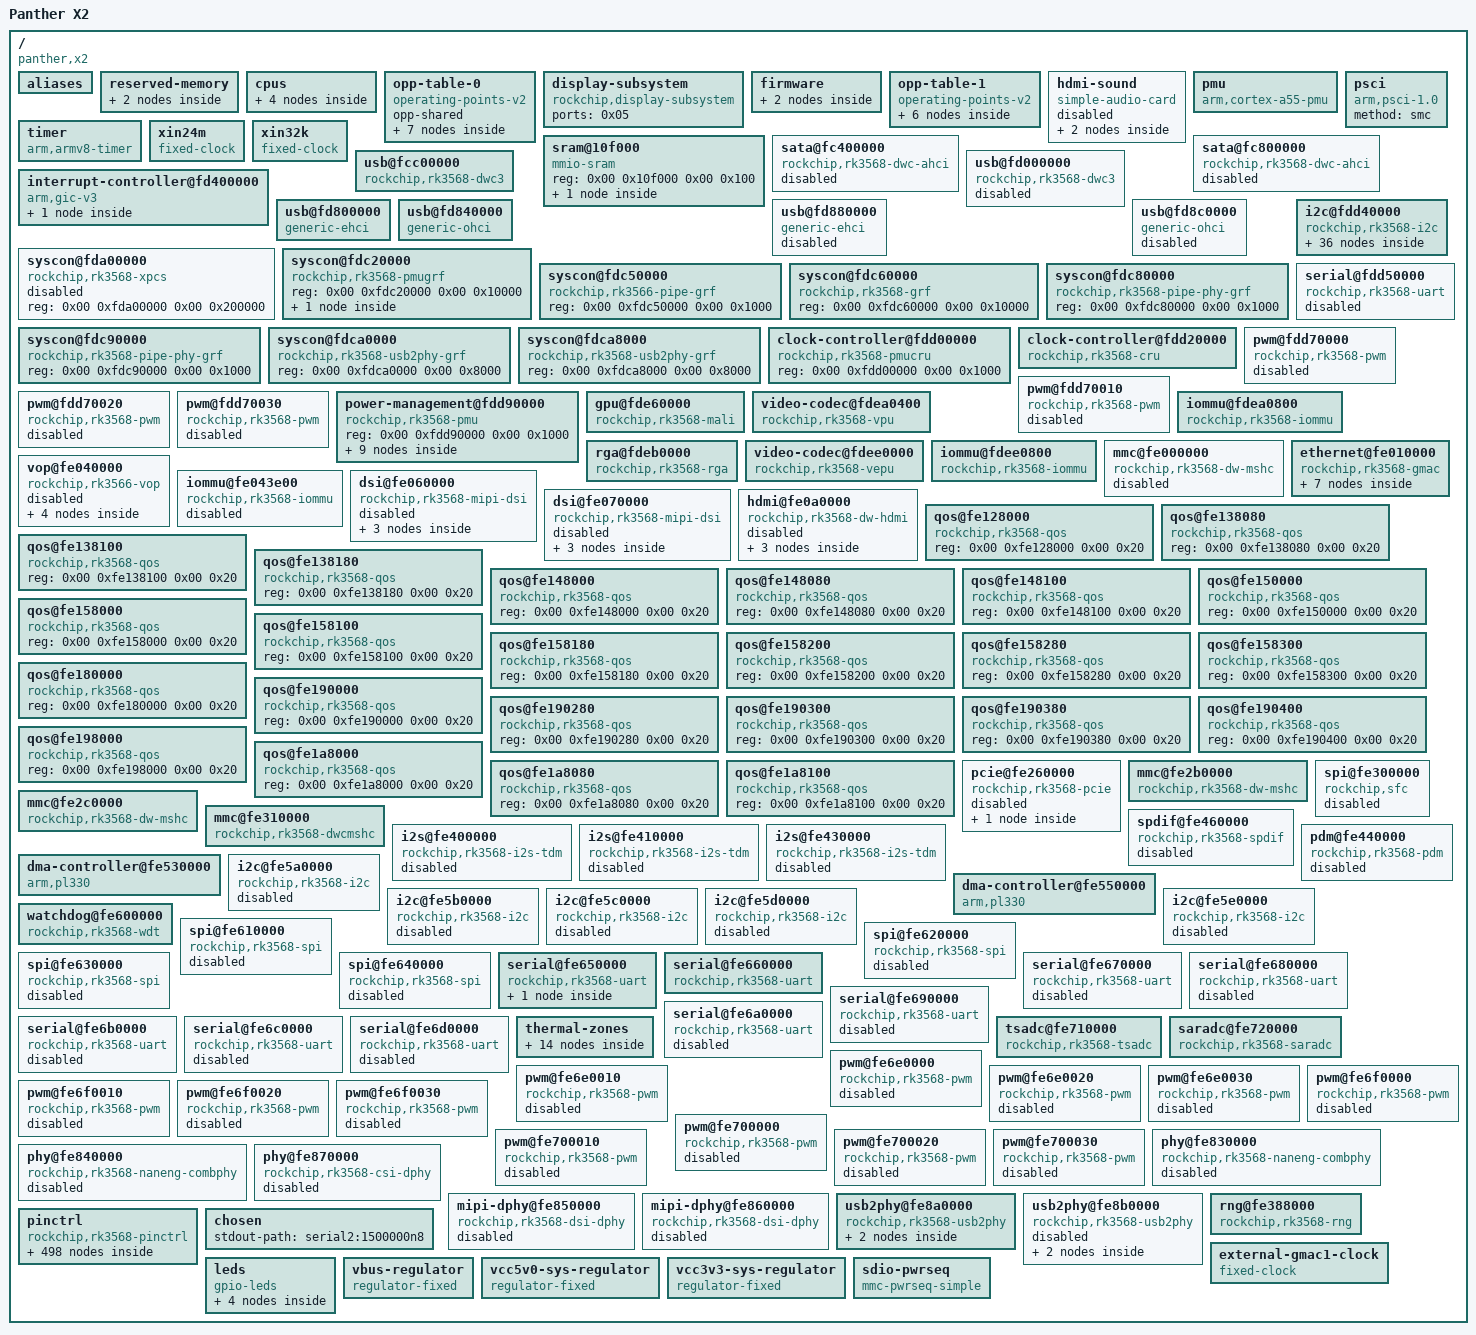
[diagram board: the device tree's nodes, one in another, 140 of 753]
/dts-v1/;

/ {
	interrupt-parent = <0x01>;
	#address-cells = <0x02>;
	#size-cells = <0x02>;
	compatible = "panther,x2\0rockchip,rk3566";
	model = "Panther X2";

	aliases {
		gpio0 = "/pinctrl/gpio@fdd60000";
		gpio1 = "/pinctrl/gpio@fe740000";
		gpio2 = "/pinctrl/gpio@fe750000";
		gpio3 = "/pinctrl/gpio@fe760000";
		gpio4 = "/pinctrl/gpio@fe770000";
		i2c0 = "/i2c@fdd40000";
		i2c1 = "/i2c@fe5a0000";
		i2c2 = "/i2c@fe5b0000";
		i2c3 = "/i2c@fe5c0000";
		i2c4 = "/i2c@fe5d0000";
		i2c5 = "/i2c@fe5e0000";
		serial0 = "/serial@fdd50000";
		serial1 = "/serial@fe650000";
		serial2 = "/serial@fe660000";
		serial3 = "/serial@fe670000";
		serial4 = "/serial@fe680000";
		serial5 = "/serial@fe690000";
		serial6 = "/serial@fe6a0000";
		serial7 = "/serial@fe6b0000";
		serial8 = "/serial@fe6c0000";
		serial9 = "/serial@fe6d0000";
		spi0 = "/spi@fe610000";
		spi1 = "/spi@fe620000";
		spi2 = "/spi@fe630000";
		spi3 = "/spi@fe640000";
		ethernet0 = "/ethernet@fe010000";
		mmc0 = "/mmc@fe310000";
		mmc1 = "/mmc@fe2b0000";
		mmc2 = "/mmc@fe2c0000";
	};

	reserved-memory {
		#address-cells = <0x02>;
		#size-cells = <0x02>;
		ranges;
		phandle = <0xbf>;

		rknpu {
			compatible = "shared-dma-pool";
			inactive;
			reusable;
			size = <0x00 0x20000000>;
			alignment = <0x00 0x1000>;
			status = "disabled";
			phandle = <0xc0>;
		};

		ramoops@110000 {
			compatible = "ramoops";
			reg = <0x00 0x110000 0x00 0xf0000>;
			record-size = <0x20000>;
			console-size = <0x80000>;
			ftrace-size = <0x00>;
			pmsg-size = <0x50000>;
			phandle = <0xc1>;
		};
	};

	cpus {
		#address-cells = <0x02>;
		#size-cells = <0x00>;

		cpu@0 {
			device_type = "cpu";
			compatible = "arm,cortex-a55";
			reg = <0x00 0x00>;
			clocks = <0x02 0x00>;
			#cooling-cells = <0x02>;
			enable-method = "psci";
			operating-points-v2 = <0x03>;
			cpu-supply = <0x04>;
			phandle = <0x09>;
		};

		cpu@100 {
			device_type = "cpu";
			compatible = "arm,cortex-a55";
			reg = <0x00 0x100>;
			#cooling-cells = <0x02>;
			enable-method = "psci";
			operating-points-v2 = <0x03>;
			cpu-supply = <0x04>;
			phandle = <0x0a>;
		};

		cpu@200 {
			device_type = "cpu";
			compatible = "arm,cortex-a55";
			reg = <0x00 0x200>;
			#cooling-cells = <0x02>;
			enable-method = "psci";
			operating-points-v2 = <0x03>;
			cpu-supply = <0x04>;
			phandle = <0x0b>;
		};

		cpu@300 {
			device_type = "cpu";
			compatible = "arm,cortex-a55";
			reg = <0x00 0x300>;
			#cooling-cells = <0x02>;
			enable-method = "psci";
			operating-points-v2 = <0x03>;
			cpu-supply = <0x04>;
			phandle = <0x0c>;
		};
	};

	opp-table-0 {
		compatible = "operating-points-v2";
		opp-shared;
		phandle = <0x03>;

		opp-408000000 {
			opp-hz = <0x00 0x18519600>;
			opp-microvolt = <0xdbba0 0xdbba0 0x118c30>;
			clock-latency-ns = <0x9c40>;
		};

		opp-600000000 {
			opp-hz = <0x00 0x23c34600>;
			opp-microvolt = <0xdbba0 0xdbba0 0x118c30>;
		};

		opp-816000000 {
			opp-hz = <0x00 0x30a32c00>;
			opp-microvolt = <0xdbba0 0xdbba0 0x118c30>;
			opp-suspend;
		};

		opp-1104000000 {
			opp-hz = <0x00 0x41cdb400>;
			opp-microvolt = <0xdbba0 0xdbba0 0x118c30>;
		};

		opp-1416000000 {
			opp-hz = <0x00 0x54667200>;
			opp-microvolt = <0xdbba0 0xdbba0 0x118c30>;
		};

		opp-1608000000 {
			opp-hz = <0x00 0x5fd82200>;
			opp-microvolt = <0xee098 0xee098 0x118c30>;
		};

		opp-1800000000 {
			opp-hz = <0x00 0x6b49d200>;
			opp-microvolt = <0x100590 0x100590 0x118c30>;
		};
	};

	display-subsystem {
		compatible = "rockchip,display-subsystem";
		ports = <0x05>;
		phandle = <0xc2>;
	};

	firmware {

		scmi {
			compatible = "arm,scmi-smc";
			arm,smc-id = <0x82000010>;
			shmem = <0x06>;
			#address-cells = <0x01>;
			#size-cells = <0x00>;
			phandle = <0xc3>;

			protocol@14 {
				reg = <0x14>;
				#clock-cells = <0x01>;
				phandle = <0x02>;
			};
		};
	};

	opp-table-1 {
		compatible = "operating-points-v2";
		phandle = <0x40>;

		opp-200000000 {
			opp-hz = <0x00 0xbebc200>;
			opp-microvolt = <0xc96a8>;
		};

		opp-300000000 {
			opp-hz = <0x00 0x11e1a300>;
			opp-microvolt = <0xc96a8>;
		};

		opp-400000000 {
			opp-hz = <0x00 0x17d78400>;
			opp-microvolt = <0xc96a8>;
		};

		opp-600000000 {
			opp-hz = <0x00 0x23c34600>;
			opp-microvolt = <0xc96a8>;
		};

		opp-700000000 {
			opp-hz = <0x00 0x29b92700>;
			opp-microvolt = <0xdbba0>;
		};

		opp-800000000 {
			opp-hz = <0x00 0x2faf0800>;
			opp-microvolt = <0xf4240>;
		};
	};

	hdmi-sound {
		compatible = "simple-audio-card";
		simple-audio-card,name = "HDMI";
		simple-audio-card,format = "i2s";
		simple-audio-card,mclk-fs = <0x100>;
		status = "disabled";
		phandle = <0xc4>;

		simple-audio-card,codec {
			sound-dai = <0x07>;
		};

		simple-audio-card,cpu {
			sound-dai = <0x08>;
		};
	};

	pmu {
		compatible = "arm,cortex-a55-pmu";
		interrupts = <0x00 0xe4 0x04 0x00 0xe5 0x04 0x00 0xe6 0x04 0x00 0xe7 0x04>;
		interrupt-affinity = <0x09 0x0a 0x0b 0x0c>;
	};

	psci {
		compatible = "arm,psci-1.0";
		method = "smc";
	};

	timer {
		compatible = "arm,armv8-timer";
		interrupts = <0x01 0x0d 0x04 0x01 0x0e 0x04 0x01 0x0b 0x04 0x01 0x0a 0x04>;
		arm,no-tick-in-suspend;
	};

	xin24m {
		compatible = "fixed-clock";
		clock-frequency = <0x16e3600>;
		clock-output-names = "xin24m";
		#clock-cells = <0x00>;
		phandle = <0x1b>;
	};

	xin32k {
		compatible = "fixed-clock";
		clock-frequency = <0x8000>;
		clock-output-names = "xin32k";
		pinctrl-0 = <0x0d>;
		pinctrl-names = "default";
		#clock-cells = <0x00>;
		phandle = <0xc5>;
	};

	sram@10f000 {
		compatible = "mmio-sram";
		reg = <0x00 0x10f000 0x00 0x100>;
		#address-cells = <0x01>;
		#size-cells = <0x01>;
		ranges = <0x00 0x00 0x10f000 0x100>;

		sram@0 {
			compatible = "arm,scmi-shmem";
			reg = <0x00 0x100>;
			phandle = <0x06>;
		};
	};

	sata@fc400000 {
		compatible = "rockchip,rk3568-dwc-ahci\0snps,dwc-ahci";
		reg = <0x00 0xfc400000 0x00 0x1000>;
		clocks = <0x0e 0x9b 0x0e 0x9c 0x0e 0x9d>;
		clock-names = "sata\0pmalive\0rxoob";
		interrupts = <0x00 0x5f 0x04>;
		phys = <0x0f 0x01>;
		phy-names = "sata-phy";
		ports-implemented = <0x01>;
		power-domains = <0x10 0x0f>;
		status = "disabled";
		phandle = <0xc6>;
	};

	sata@fc800000 {
		compatible = "rockchip,rk3568-dwc-ahci\0snps,dwc-ahci";
		reg = <0x00 0xfc800000 0x00 0x1000>;
		clocks = <0x0e 0xa0 0x0e 0xa1 0x0e 0xa2>;
		clock-names = "sata\0pmalive\0rxoob";
		interrupts = <0x00 0x60 0x04>;
		phys = <0x11 0x01>;
		phy-names = "sata-phy";
		ports-implemented = <0x01>;
		power-domains = <0x10 0x0f>;
		status = "disabled";
		phandle = <0xc7>;
	};

	usb@fcc00000 {
		compatible = "rockchip,rk3568-dwc3\0snps,dwc3";
		reg = <0x00 0xfcc00000 0x00 0x400000>;
		interrupts = <0x00 0xa9 0x04>;
		clocks = <0x0e 0xa6 0x0e 0xa7 0x0e 0xa5>;
		clock-names = "ref_clk\0suspend_clk\0bus_clk";
		dr_mode = "host";
		phy_type = "utmi_wide";
		power-domains = <0x10 0x0f>;
		resets = <0x0e 0x94>;
		snps,dis_u2_susphy_quirk;
		status = "okay";
		phys = <0x12>;
		phy-names = "usb2-phy";
		extcon = <0x13>;
		maximum-speed = "high-speed";
		phandle = <0xc8>;
	};

	usb@fd000000 {
		compatible = "rockchip,rk3568-dwc3\0snps,dwc3";
		reg = <0x00 0xfd000000 0x00 0x400000>;
		interrupts = <0x00 0xaa 0x04>;
		clocks = <0x0e 0xa9 0x0e 0xaa 0x0e 0xa8>;
		clock-names = "ref_clk\0suspend_clk\0bus_clk";
		dr_mode = "host";
		phys = <0x14 0x0f 0x04>;
		phy-names = "usb2-phy\0usb3-phy";
		phy_type = "utmi_wide";
		power-domains = <0x10 0x0f>;
		resets = <0x0e 0x95>;
		snps,dis_u2_susphy_quirk;
		status = "disabled";
		phandle = <0xc9>;
	};

	interrupt-controller@fd400000 {
		compatible = "arm,gic-v3";
		#interrupt-cells = <0x03>;
		#address-cells = <0x02>;
		#size-cells = <0x02>;
		ranges;
		interrupt-controller;
		reg = <0x00 0xfd400000 0x00 0x10000 0x00 0xfd460000 0x00 0xc0000>;
		interrupts = <0x01 0x09 0x04>;
		phandle = <0x01>;

		interrupt-controller@fd440000 {
			compatible = "arm,gic-v3-its";
			msi-controller;
			#msi-cells = <0x01>;
			reg = <0x00 0xfd440000 0x00 0x20000>;
			phandle = <0x57>;
		};
	};

	usb@fd800000 {
		compatible = "generic-ehci";
		reg = <0x00 0xfd800000 0x00 0x40000>;
		interrupts = <0x00 0x82 0x04>;
		clocks = <0x0e 0xbd 0x0e 0xbe 0x0e 0xbc>;
		phys = <0x15>;
		phy-names = "usb";
		status = "okay";
		phandle = <0xca>;
	};

	usb@fd840000 {
		compatible = "generic-ohci";
		reg = <0x00 0xfd840000 0x00 0x40000>;
		interrupts = <0x00 0x83 0x04>;
		clocks = <0x0e 0xbd 0x0e 0xbe 0x0e 0xbc>;
		phys = <0x15>;
		phy-names = "usb";
		status = "okay";
		phandle = <0xcb>;
	};

	usb@fd880000 {
		compatible = "generic-ehci";
		reg = <0x00 0xfd880000 0x00 0x40000>;
		interrupts = <0x00 0x85 0x04>;
		clocks = <0x0e 0xbf 0x0e 0xc0 0x0e 0xbc>;
		phys = <0x16>;
		phy-names = "usb";
		status = "disabled";
		phandle = <0xcc>;
	};

	usb@fd8c0000 {
		compatible = "generic-ohci";
		reg = <0x00 0xfd8c0000 0x00 0x40000>;
		interrupts = <0x00 0x86 0x04>;
		clocks = <0x0e 0xbf 0x0e 0xc0 0x0e 0xbc>;
		phys = <0x16>;
		phy-names = "usb";
		status = "disabled";
		phandle = <0xcd>;
	};

	syscon@fda00000 {
		compatible = "rockchip,rk3568-xpcs\0syscon";
		reg = <0x00 0xfda00000 0x00 0x200000>;
		status = "disabled";
		phandle = <0xce>;
	};

	syscon@fdc20000 {
		compatible = "rockchip,rk3568-pmugrf\0syscon\0simple-mfd";
		reg = <0x00 0xfdc20000 0x00 0x10000>;
		phandle = <0xaf>;

		io-domains {
			compatible = "rockchip,rk3568-pmu-io-voltage-domain";
			status = "okay";
			pmuio1-supply = <0x17>;
			pmuio2-supply = <0x17>;
			vccio1-supply = <0x18>;
			vccio2-supply = <0x19>;
			vccio3-supply = <0x1a>;
			vccio4-supply = <0x19>;
			vccio5-supply = <0x18>;
			vccio6-supply = <0x18>;
			vccio7-supply = <0x18>;
			phandle = <0xcf>;
		};
	};

	syscon@fdc50000 {
		reg = <0x00 0xfdc50000 0x00 0x1000>;
		compatible = "rockchip,rk3566-pipe-grf\0syscon";
		phandle = <0xaa>;
	};

	syscon@fdc60000 {
		compatible = "rockchip,rk3568-grf\0syscon\0simple-mfd";
		reg = <0x00 0xfdc60000 0x00 0x10000>;
		phandle = <0x1d>;
	};

	syscon@fdc80000 {
		compatible = "rockchip,rk3568-pipe-phy-grf\0syscon";
		reg = <0x00 0xfdc80000 0x00 0x1000>;
		phandle = <0xab>;
	};

	syscon@fdc90000 {
		compatible = "rockchip,rk3568-pipe-phy-grf\0syscon";
		reg = <0x00 0xfdc90000 0x00 0x1000>;
		phandle = <0xac>;
	};

	syscon@fdca0000 {
		compatible = "rockchip,rk3568-usb2phy-grf\0syscon";
		reg = <0x00 0xfdca0000 0x00 0x8000>;
		phandle = <0xad>;
	};

	syscon@fdca8000 {
		compatible = "rockchip,rk3568-usb2phy-grf\0syscon";
		reg = <0x00 0xfdca8000 0x00 0x8000>;
		phandle = <0xae>;
	};

	clock-controller@fdd00000 {
		compatible = "rockchip,rk3568-pmucru";
		reg = <0x00 0xfdd00000 0x00 0x1000>;
		#clock-cells = <0x01>;
		#reset-cells = <0x01>;
		phandle = <0x1c>;
	};

	clock-controller@fdd20000 {
		compatible = "rockchip,rk3568-cru";
		reg = <0x00 0xfdd20000 0x00 0x1000>;
		clocks = <0x1b>;
		clock-names = "xin24m";
		#clock-cells = <0x01>;
		#reset-cells = <0x01>;
		assigned-clocks = <0x1c 0x05 0x0e 0x04 0x1c 0x01>;
		assigned-clock-rates = <0x8000 0x47868c00 0xbebc200>;
		assigned-clock-parents = <0x1c 0x08>;
		rockchip,grf = <0x1d>;
		phandle = <0x0e>;
	};

	i2c@fdd40000 {
		compatible = "rockchip,rk3568-i2c\0rockchip,rk3399-i2c";
		reg = <0x00 0xfdd40000 0x00 0x1000>;
		interrupts = <0x00 0x2e 0x04>;
		clocks = <0x1c 0x07 0x1c 0x2d>;
		clock-names = "i2c\0pclk";
		pinctrl-0 = <0x1e>;
		pinctrl-names = "default";
		#address-cells = <0x01>;
		#size-cells = <0x00>;
		status = "okay";
		phandle = <0xd0>;

		regulator@1c {
			compatible = "tcs,tcs4525";
			reg = <0x1c>;
			fcs,suspend-voltage-selector = <0x01>;
			regulator-name = "vdd_cpu";
			regulator-min-microvolt = "\0\f5";
			regulator-max-microvolt = <0x118c30>;
			regulator-ramp-delay = <0x8fc>;
			regulator-always-on;
			regulator-boot-on;
			vin-supply = <0x1f>;
			phandle = <0x04>;

			regulator-state-mem {
				regulator-off-in-suspend;
			};
		};

		pmic@20 {
			compatible = "rockchip,rk809";
			reg = <0x20>;
			interrupt-parent = <0x20>;
			interrupts = <0x03 0x08>;
			#clock-cells = <0x01>;
			clock-output-names = "rk808-clkout1\0rk808-clkout2";
			pinctrl-names = "default";
			pinctrl-0 = <0x21>;
			rockchip,system-power-controller;
			wakeup-source;
			vcc1-supply = <0x22>;
			vcc2-supply = <0x22>;
			vcc3-supply = <0x22>;
			vcc4-supply = <0x22>;
			vcc5-supply = <0x22>;
			vcc6-supply = <0x22>;
			vcc7-supply = <0x22>;
			vcc8-supply = <0x22>;
			vcc9-supply = <0x22>;
			phandle = <0x89>;

			regulators {

				DCDC_REG1 {
					regulator-name = "vdd_logic";
					regulator-always-on;
					regulator-boot-on;
					regulator-min-microvolt = <0x7a120>;
					regulator-max-microvolt = <0x149970>;
					regulator-init-microvolt = <0xdbba0>;
					regulator-ramp-delay = <0x1771>;
					regulator-initial-mode = <0x02>;
					phandle = <0xd1>;

					regulator-state-mem {
						regulator-on-in-suspend;
						regulator-suspend-microvolt = <0xdbba0>;
					};
				};

				DCDC_REG2 {
					regulator-name = "vdd_gpu";
					regulator-always-on;
					regulator-boot-on;
					regulator-min-microvolt = <0x7a120>;
					regulator-max-microvolt = <0x149970>;
					regulator-init-microvolt = <0xdbba0>;
					regulator-ramp-delay = <0x1771>;
					regulator-initial-mode = <0x02>;
					phandle = <0x41>;

					regulator-state-mem {
						regulator-off-in-suspend;
					};
				};

				DCDC_REG3 {
					regulator-always-on;
					regulator-boot-on;
					regulator-initial-mode = <0x02>;
					regulator-name = "vcc_ddr";
					phandle = <0xd2>;

					regulator-state-mem {
						regulator-on-in-suspend;
					};
				};

				DCDC_REG4 {
					regulator-always-on;
					regulator-boot-on;
					regulator-min-microvolt = <0x7a120>;
					regulator-max-microvolt = <0x149970>;
					regulator-init-microvolt = <0xdbba0>;
					regulator-initial-mode = <0x02>;
					regulator-name = "vdd_npu";
					phandle = <0xd3>;

					regulator-state-mem {
						regulator-off-in-suspend;
					};
				};

				DCDC_REG5 {
					regulator-name = "vcc_1v8";
					regulator-always-on;
					regulator-boot-on;
					regulator-min-microvolt = <0x1b7740>;
					regulator-max-microvolt = <0x1b7740>;
					phandle = <0x19>;

					regulator-state-mem {
						regulator-on-in-suspend;
						regulator-suspend-microvolt = <0x1b7740>;
					};
				};

				LDO_REG1 {
					regulator-always-on;
					regulator-boot-on;
					regulator-min-microvolt = <0xdbba0>;
					regulator-max-microvolt = <0xdbba0>;
					regulator-name = "vdda0v9_image";
					phandle = <0xd4>;

					regulator-state-mem {
						regulator-on-in-suspend;
						regulator-suspend-microvolt = <0xdbba0>;
					};
				};

				LDO_REG2 {
					regulator-always-on;
					regulator-boot-on;
					regulator-min-microvolt = <0xdbba0>;
					regulator-max-microvolt = <0xdbba0>;
					regulator-name = "vdda_0v9";
					phandle = <0xd5>;

					regulator-state-mem {
						regulator-off-in-suspend;
					};
				};

				LDO_REG3 {
					regulator-always-on;
					regulator-boot-on;
					regulator-min-microvolt = <0xdbba0>;
					regulator-max-microvolt = <0xdbba0>;
					regulator-name = "vdda0v9_pmu";
					phandle = <0xd6>;

					regulator-state-mem {
						regulator-on-in-suspend;
						regulator-suspend-microvolt = <0xdbba0>;
					};
				};

				LDO_REG4 {
					regulator-always-on;
					regulator-boot-on;
					regulator-min-microvolt = <0x325aa0>;
					regulator-max-microvolt = <0x325aa0>;
					regulator-name = "vccio_acodec";
					phandle = <0xd7>;

					regulator-state-mem {
						regulator-off-in-suspend;
					};
				};

				LDO_REG5 {
					regulator-always-on;
					regulator-boot-on;
					regulator-min-microvolt = <0x1b7740>;
					regulator-max-microvolt = <0x325aa0>;
					regulator-name = "vccio_sd";
					phandle = <0x1a>;

					regulator-state-mem {
						regulator-off-in-suspend;
					};
				};

				LDO_REG6 {
					regulator-always-on;
					regulator-boot-on;
					regulator-min-microvolt = <0x325aa0>;
					regulator-max-microvolt = <0x325aa0>;
					regulator-name = "vcc3v3_pmu";
					phandle = <0x17>;

					regulator-state-mem {
						regulator-on-in-suspend;
						regulator-suspend-microvolt = <0x325aa0>;
					};
				};

				LDO_REG7 {
					regulator-always-on;
					regulator-boot-on;
					regulator-min-microvolt = <0x1b7740>;
					regulator-max-microvolt = <0x1b7740>;
					regulator-name = "vcca_1v8";
					phandle = <0x9d>;

					regulator-state-mem {
						regulator-off-in-suspend;
					};
				};

				LDO_REG8 {
					regulator-always-on;
					regulator-boot-on;
					regulator-min-microvolt = <0x1b7740>;
					regulator-max-microvolt = <0x1b7740>;
					regulator-name = "vcca1v8_pmu";
					phandle = <0x8e>;

					regulator-state-mem {
						regulator-off-in-suspend;
					};
				};

				LDO_REG9 {
					regulator-always-on;
					regulator-boot-on;
					regulator-min-microvolt = <0x1b7740>;
					regulator-max-microvolt = <0x1b7740>;
					regulator-name = "vcca1v8_image";
					phandle = <0xd8>;

					regulator-state-mem {
						regulator-off-in-suspend;
					};
				};

				SWITCH_REG1 {
					regulator-name = "vcc_3v3";
					phandle = <0x18>;

					regulator-state-mem {
						regulator-off-in-suspend;
					};
				};

				SWITCH_REG2 {
					regulator-name = "vcc3v3_sd";
					status = "disabled";
					phandle = <0xd9>;

					regulator-state-mem {
						regulator-on-in-suspend;
					};
				};
			};
		};
	};

	serial@fdd50000 {
		compatible = "rockchip,rk3568-uart\0snps,dw-apb-uart";
		reg = <0x00 0xfdd50000 0x00 0x100>;
		interrupts = <0x00 0x74 0x04>;
		clocks = <0x1c 0x0b 0x1c 0x2c>;
		clock-names = "baudclk\0apb_pclk";
		dmas = <0x23 0x00 0x23 0x01>;
		pinctrl-0 = <0x24>;
		pinctrl-names = "default";
		reg-io-width = <0x04>;
		reg-shift = <0x02>;
		status = "disabled";
		phandle = <0xda>;
	};

	pwm@fdd70000 {
		compatible = "rockchip,rk3568-pwm\0rockchip,rk3328-pwm";
		reg = <0x00 0xfdd70000 0x00 0x10>;
		clocks = <0x1c 0x0d 0x1c 0x30>;
		clock-names = "pwm\0pclk";
		pinctrl-0 = <0x25>;
		pinctrl-names = "default";
		#pwm-cells = <0x03>;
		status = "disabled";
		phandle = <0xdb>;
	};

	pwm@fdd70010 {
		compatible = "rockchip,rk3568-pwm\0rockchip,rk3328-pwm";
		reg = <0x00 0xfdd70010 0x00 0x10>;
		clocks = <0x1c 0x0d 0x1c 0x30>;
		clock-names = "pwm\0pclk";
		pinctrl-0 = <0x26>;
		pinctrl-names = "default";
		#pwm-cells = <0x03>;
		status = "disabled";
		phandle = <0xdc>;
	};

	pwm@fdd70020 {
		compatible = "rockchip,rk3568-pwm\0rockchip,rk3328-pwm";
		reg = <0x00 0xfdd70020 0x00 0x10>;
		clocks = <0x1c 0x0d 0x1c 0x30>;
		clock-names = "pwm\0pclk";
		pinctrl-0 = <0x27>;
		pinctrl-names = "default";
		#pwm-cells = <0x03>;
		status = "disabled";
		phandle = <0xdd>;
	};

	pwm@fdd70030 {
		compatible = "rockchip,rk3568-pwm\0rockchip,rk3328-pwm";
		reg = <0x00 0xfdd70030 0x00 0x10>;
		clocks = <0x1c 0x0d 0x1c 0x30>;
		clock-names = "pwm\0pclk";
		pinctrl-0 = <0x28>;
		pinctrl-names = "default";
		#pwm-cells = <0x03>;
		status = "disabled";
		phandle = <0xde>;
	};

	power-management@fdd90000 {
		compatible = "rockchip,rk3568-pmu\0syscon\0simple-mfd";
		reg = <0x00 0xfdd90000 0x00 0x1000>;
		phandle = <0xdf>;

		power-controller {
			compatible = "rockchip,rk3568-power-controller";
			#power-domain-cells = <0x01>;
			#address-cells = <0x01>;
			#size-cells = <0x00>;
			phandle = <0x10>;

			power-domain@7 {
				reg = <0x07>;
				clocks = <0x0e 0x19 0x0e 0x1a>;
				pm_qos = <0x29>;
				#power-domain-cells = <0x00>;
			};

			power-domain@8 {
				reg = <0x08>;
				clocks = <0x0e 0xcc 0x0e 0xcd>;
				pm_qos = <0x2a 0x2b 0x2c>;
				#power-domain-cells = <0x00>;
			};

			power-domain@9 {
				reg = <0x09>;
				clocks = <0x0e 0xda 0x0e 0xdb 0x0e 0xdc>;
				pm_qos = <0x2d 0x2e 0x2f>;
				#power-domain-cells = <0x00>;
			};

			power-domain@10 {
				reg = <0x0a>;
				clocks = <0x0e 0xf1 0x0e 0xf2>;
				pm_qos = <0x30 0x31 0x32 0x33 0x34 0x35>;
				#power-domain-cells = <0x00>;
			};

			power-domain@11 {
				reg = <0x0b>;
				clocks = <0x0e 0xed>;
				pm_qos = <0x36>;
				#power-domain-cells = <0x00>;
			};

			power-domain@13 {
				clocks = <0x0e 0x107>;
				reg = <0x0d>;
				pm_qos = <0x37>;
				#power-domain-cells = <0x00>;
			};

			power-domain@14 {
				reg = <0x0e>;
				clocks = <0x0e 0x102>;
				pm_qos = <0x38 0x39 0x3a>;
				#power-domain-cells = <0x00>;
			};

			power-domain@15 {
				reg = <0x0f>;
				clocks = <0x0e 0x7f>;
				pm_qos = <0x3b 0x3c 0x3d 0x3e 0x3f>;
				#power-domain-cells = <0x00>;
			};
		};
	};

	gpu@fde60000 {
		compatible = "rockchip,rk3568-mali\0arm,mali-bifrost";
		reg = <0x00 0xfde60000 0x00 0x4000>;
		interrupts = <0x00 0x28 0x04 0x00 0x29 0x04 0x00 0x27 0x04>;
		interrupt-names = "job\0mmu\0gpu";
		clocks = <0x02 0x01 0x0e 0x1b>;
		clock-names = "gpu\0bus";
		#cooling-cells = <0x02>;
		operating-points-v2 = <0x40>;
		power-domains = <0x10 0x07>;
		status = "okay";
		mali-supply = <0x41>;
		phandle = <0x9a>;
	};

	video-codec@fdea0400 {
		compatible = "rockchip,rk3568-vpu";
		reg = <0x00 0xfdea0000 0x00 0x800>;
		interrupts = <0x00 0x8b 0x04>;
		interrupt-names = "vdpu";
		clocks = <0x0e 0xee 0x0e 0xef>;
		clock-names = "aclk\0hclk";
		iommus = <0x42>;
		power-domains = <0x10 0x0b>;
		phandle = <0xe0>;
	};

	iommu@fdea0800 {
		compatible = "rockchip,rk3568-iommu";
		reg = <0x00 0xfdea0800 0x00 0x40>;
		interrupts = <0x00 0x8a 0x04>;
		clock-names = "aclk\0iface";
		clocks = <0x0e 0xee 0x0e 0xef>;
		power-domains = <0x10 0x0b>;
		#iommu-cells = <0x00>;
		phandle = <0x42>;
	};

	rga@fdeb0000 {
		compatible = "rockchip,rk3568-rga\0rockchip,rk3288-rga";
		reg = <0x00 0xfdeb0000 0x00 0x180>;
		interrupts = <0x00 0x5a 0x04>;
		clocks = <0x0e 0xf3 0x0e 0xf4 0x0e 0xf5>;
		clock-names = "aclk\0hclk\0sclk";
		resets = <0x0e 0x126 0x0e 0x124 0x0e 0x125>;
		reset-names = "core\0axi\0ahb";
		power-domains = <0x10 0x0a>;
		phandle = <0xe1>;
	};

	video-codec@fdee0000 {
		compatible = "rockchip,rk3568-vepu";
		reg = <0x00 0xfdee0000 0x00 0x800>;
		interrupts = <0x00 0x40 0x04>;
		clocks = <0x0e 0xfd 0x0e 0xfe>;
		clock-names = "aclk\0hclk";
		iommus = <0x43>;
		power-domains = <0x10 0x0a>;
		phandle = <0xe2>;
	};

	iommu@fdee0800 {
		compatible = "rockchip,rk3568-iommu";
		reg = <0x00 0xfdee0800 0x00 0x40>;
		interrupts = <0x00 0x3f 0x04>;
		clocks = <0x0e 0xfd 0x0e 0xfe>;
		clock-names = "aclk\0iface";
		power-domains = <0x10 0x0a>;
		#iommu-cells = <0x00>;
		phandle = <0x43>;
	};

	mmc@fe000000 {
		compatible = "rockchip,rk3568-dw-mshc\0rockchip,rk3288-dw-mshc";
		reg = <0x00 0xfe000000 0x00 0x4000>;
		interrupts = <0x00 0x64 0x04>;
		clocks = <0x0e 0xc1 0x0e 0xc2 0x0e 0x18e 0x0e 0x18f>;
		clock-names = "biu\0ciu\0ciu-drive\0ciu-sample";
		fifo-depth = <0x100>;
		max-frequency = <0x8f0d180>;
		resets = <0x0e 0xeb>;
		reset-names = "reset";
		status = "disabled";
		phandle = <0xe3>;
	};

	ethernet@fe010000 {
		compatible = "rockchip,rk3568-gmac\0snps,dwmac-4.20a";
		reg = <0x00 0xfe010000 0x00 0x10000>;
		interrupts = <0x00 0x20 0x04 0x00 0x1d 0x04>;
		interrupt-names = "macirq\0eth_wake_irq";
		clocks = <0x0e 0x186 0x0e 0x189 0x0e 0x189 0x0e 0xc7 0x0e 0xc3 0x0e 0xc4 0x0e 0x189 0x0e 0xc8>;
		clock-names = "stmmaceth\0mac_clk_rx\0mac_clk_tx\0clk_mac_refout\0aclk_mac\0pclk_mac\0clk_mac_speed\0ptp_ref";
		resets = <0x0e 0xec>;
		reset-names = "stmmaceth";
		rockchip,grf = <0x1d>;
		snps,axi-config = <0x44>;
		snps,mixed-burst;
		snps,mtl-rx-config = <0x45>;
		snps,mtl-tx-config = <0x46>;
		snps,tso;
		status = "okay";
		assigned-clocks = <0x0e 0x189 0x0e 0x187 0x0e 0x186>;
		assigned-clock-parents = <0x0e 0x187 0x0e 0x186 0x47>;
		clock_in_out = "input";
		phy-supply = <0x18>;
		phy-mode = "rgmii";
		pinctrl-names = "default";
		pinctrl-0 = <0x48 0x49 0x4a 0x4b 0x4c 0x4d>;
		snps,reset-gpio = <0x4e 0x01 0x01>;
		snps,reset-active-low;
		snps,reset-delays-us = <0x00 0x4e20 0x186a0>;
		tx_delay = <0x30>;
		rx_delay = <0x10>;
		phy-handle = <0x4f>;
		phandle = <0xe4>;

		mdio {
			compatible = "snps,dwmac-mdio";
			#address-cells = <0x01>;
			#size-cells = <0x00>;
			phandle = <0xe5>;

			ethernet-phy@0 {
				compatible = "ethernet-phy-ieee802.3-c22";
				reg = <0x00>;
				status = "okay";
				phandle = <0x4f>;
			};
		};

		stmmac-axi-config {
			snps,blen = <0x00 0x00 0x00 0x00 0x10 0x08 0x04>;
			snps,rd_osr_lmt = <0x08>;
			snps,wr_osr_lmt = <0x04>;
			phandle = <0x44>;
		};

		rx-queues-config {
			snps,rx-queues-to-use = <0x01>;
			phandle = <0x45>;

			queue0 {
			};
		};

		tx-queues-config {
			snps,tx-queues-to-use = <0x01>;
			phandle = <0x46>;

			queue0 {
			};
		};
	};

	vop@fe040000 {
		reg = <0x00 0xfe040000 0x00 0x3000 0x00 0xfe044000 0x00 0x1000>;
		reg-names = "vop\0gamma-lut";
		interrupts = <0x00 0x94 0x04>;
		clocks = <0x0e 0xdd 0x0e 0xde 0x0e 0xdf 0x0e 0xe0 0x0e 0xe1>;
		clock-names = "aclk\0hclk\0dclk_vp0\0dclk_vp1\0dclk_vp2";
		iommus = <0x50>;
		power-domains = <0x10 0x09>;
		rockchip,grf = <0x1d>;
		status = "disabled";
		compatible = "rockchip,rk3566-vop";
		phandle = <0xe6>;

		ports {
			#address-cells = <0x01>;
			#size-cells = <0x00>;
			phandle = <0x05>;

			port@0 {
				reg = <0x00>;
				#address-cells = <0x01>;
				#size-cells = <0x00>;
				phandle = <0xe7>;
			};

			port@1 {
				reg = <0x01>;
				#address-cells = <0x01>;
				#size-cells = <0x00>;
				phandle = <0xe8>;
			};

			port@2 {
				reg = <0x02>;
				#address-cells = <0x01>;
				#size-cells = <0x00>;
				phandle = <0xe9>;
			};
		};
	};

	iommu@fe043e00 {
		compatible = "rockchip,rk3568-iommu";
		reg = <0x00 0xfe043e00 0x00 0x100 0x00 0xfe043f00 0x00 0x100>;
		interrupts = <0x00 0x94 0x04>;
		clocks = <0x0e 0xdd 0x0e 0xde>;
		clock-names = "aclk\0iface";
		#iommu-cells = <0x00>;
		power-domains = <0x10 0x09>;
		status = "disabled";
		phandle = <0x50>;
	};

	dsi@fe060000 {
		compatible = "rockchip,rk3568-mipi-dsi\0snps,dw-mipi-dsi";
		reg = <0x00 0xfe060000 0x00 0x10000>;
		interrupts = <0x00 0x44 0x04>;
		clock-names = "pclk\0hclk";
		clocks = <0x0e 0xe8 0x0e 0xda>;
		phy-names = "dphy";
		phys = <0x51>;
		power-domains = <0x10 0x09>;
		reset-names = "apb";
		resets = <0x0e 0x110>;
		rockchip,grf = <0x1d>;
		status = "disabled";
		phandle = <0xea>;

		ports {
			#address-cells = <0x01>;
			#size-cells = <0x00>;

			port@0 {
				reg = <0x00>;
				phandle = <0xeb>;
			};

			port@1 {
				reg = <0x01>;
				phandle = <0xec>;
			};
		};
	};

	dsi@fe070000 {
		compatible = "rockchip,rk3568-mipi-dsi\0snps,dw-mipi-dsi";
		reg = <0x00 0xfe070000 0x00 0x10000>;
		interrupts = <0x00 0x45 0x04>;
		clock-names = "pclk\0hclk";
		clocks = <0x0e 0xe9 0x0e 0xda>;
		phy-names = "dphy";
		phys = <0x52>;
		power-domains = <0x10 0x09>;
		reset-names = "apb";
		resets = <0x0e 0x111>;
		rockchip,grf = <0x1d>;
		status = "disabled";
		phandle = <0xed>;

		ports {
			#address-cells = <0x01>;
			#size-cells = <0x00>;

			port@0 {
				reg = <0x00>;
				phandle = <0xee>;
			};

			port@1 {
				reg = <0x01>;
				phandle = <0xef>;
			};
		};
	};

	hdmi@fe0a0000 {
		compatible = "rockchip,rk3568-dw-hdmi";
		reg = <0x00 0xfe0a0000 0x00 0x20000>;
		interrupts = <0x00 0x2d 0x04>;
		clocks = <0x0e 0xe6 0x0e 0xe7 0x0e 0x193 0x1c 0x28 0x0e 0xda>;
		clock-names = "iahb\0isfr\0cec\0ref";
		pinctrl-names = "default";
		pinctrl-0 = <0x53 0x54 0x55>;
		power-domains = <0x10 0x09>;
		reg-io-width = <0x04>;
		rockchip,grf = <0x1d>;
		#sound-dai-cells = <0x00>;
		status = "disabled";
		phandle = <0x07>;

		ports {
			#address-cells = <0x01>;
			#size-cells = <0x00>;

			port@0 {
				reg = <0x00>;
				phandle = <0xf0>;
			};

			port@1 {
				reg = <0x01>;
				phandle = <0xf1>;
			};
		};
	};

	qos@fe128000 {
		compatible = "rockchip,rk3568-qos\0syscon";
		reg = <0x00 0xfe128000 0x00 0x20>;
		phandle = <0x29>;
	};

	qos@fe138080 {
		compatible = "rockchip,rk3568-qos\0syscon";
		reg = <0x00 0xfe138080 0x00 0x20>;
		phandle = <0x38>;
	};

	qos@fe138100 {
		compatible = "rockchip,rk3568-qos\0syscon";
		reg = <0x00 0xfe138100 0x00 0x20>;
		phandle = <0x39>;
	};

	qos@fe138180 {
		compatible = "rockchip,rk3568-qos\0syscon";
		reg = <0x00 0xfe138180 0x00 0x20>;
		phandle = <0x3a>;
	};

	qos@fe148000 {
		compatible = "rockchip,rk3568-qos\0syscon";
		reg = <0x00 0xfe148000 0x00 0x20>;
		phandle = <0x2a>;
	};

	qos@fe148080 {
		compatible = "rockchip,rk3568-qos\0syscon";
		reg = <0x00 0xfe148080 0x00 0x20>;
		phandle = <0x2b>;
	};

	qos@fe148100 {
		compatible = "rockchip,rk3568-qos\0syscon";
		reg = <0x00 0xfe148100 0x00 0x20>;
		phandle = <0x2c>;
	};

	qos@fe150000 {
		compatible = "rockchip,rk3568-qos\0syscon";
		reg = <0x00 0xfe150000 0x00 0x20>;
		phandle = <0x36>;
	};

	qos@fe158000 {
		compatible = "rockchip,rk3568-qos\0syscon";
		reg = <0x00 0xfe158000 0x00 0x20>;
		phandle = <0x30>;
	};

	qos@fe158100 {
		compatible = "rockchip,rk3568-qos\0syscon";
		reg = <0x00 0xfe158100 0x00 0x20>;
		phandle = <0x31>;
	};

	qos@fe158180 {
		compatible = "rockchip,rk3568-qos\0syscon";
		reg = <0x00 0xfe158180 0x00 0x20>;
		phandle = <0x32>;
	};

	qos@fe158200 {
		compatible = "rockchip,rk3568-qos\0syscon";
		reg = <0x00 0xfe158200 0x00 0x20>;
		phandle = <0x33>;
	};

	qos@fe158280 {
		compatible = "rockchip,rk3568-qos\0syscon";
		reg = <0x00 0xfe158280 0x00 0x20>;
		phandle = <0x34>;
	};

	qos@fe158300 {
		compatible = "rockchip,rk3568-qos\0syscon";
		reg = <0x00 0xfe158300 0x00 0x20>;
		phandle = <0x35>;
	};

	qos@fe180000 {
		compatible = "rockchip,rk3568-qos\0syscon";
		reg = <0x00 0xfe180000 0x00 0x20>;
		phandle = <0xf2>;
	};

	qos@fe190000 {
		compatible = "rockchip,rk3568-qos\0syscon";
		reg = <0x00 0xfe190000 0x00 0x20>;
		phandle = <0x3b>;
	};

	qos@fe190280 {
		compatible = "rockchip,rk3568-qos\0syscon";
		reg = <0x00 0xfe190280 0x00 0x20>;
		phandle = <0x3c>;
	};

	qos@fe190300 {
		compatible = "rockchip,rk3568-qos\0syscon";
		reg = <0x00 0xfe190300 0x00 0x20>;
		phandle = <0x3d>;
	};

	qos@fe190380 {
		compatible = "rockchip,rk3568-qos\0syscon";
		reg = <0x00 0xfe190380 0x00 0x20>;
		phandle = <0x3e>;
	};

	qos@fe190400 {
		compatible = "rockchip,rk3568-qos\0syscon";
		reg = <0x00 0xfe190400 0x00 0x20>;
		phandle = <0x3f>;
	};

	qos@fe198000 {
		compatible = "rockchip,rk3568-qos\0syscon";
		reg = <0x00 0xfe198000 0x00 0x20>;
		phandle = <0x37>;
	};

	qos@fe1a8000 {
		compatible = "rockchip,rk3568-qos\0syscon";
		reg = <0x00 0xfe1a8000 0x00 0x20>;
		phandle = <0x2d>;
	};

	qos@fe1a8080 {
		compatible = "rockchip,rk3568-qos\0syscon";
		reg = <0x00 0xfe1a8080 0x00 0x20>;
		phandle = <0x2e>;
	};

	qos@fe1a8100 {
		compatible = "rockchip,rk3568-qos\0syscon";
		reg = <0x00 0xfe1a8100 0x00 0x20>;
		phandle = <0x2f>;
	};

	pcie@fe260000 {
		compatible = "rockchip,rk3568-pcie";
		reg = <0x03 0xc0000000 0x00 0x400000 0x00 0xfe260000 0x00 0x10000 0x00 0xf4000000 0x00 0x100000>;
		reg-names = "dbi\0apb\0config";
		interrupts = <0x00 0x4b 0x04 0x00 0x4a 0x04 0x00 0x49 0x04 0x00 0x48 0x04 0x00 0x47 0x04>;
		interrupt-names = "sys\0pmc\0msg\0legacy\0err";
		bus-range = <0x00 0x0f>;
		clocks = <0x0e 0x81 0x0e 0x82 0x0e 0x83 0x0e 0x84 0x0e 0x85>;
		clock-names = "aclk_mst\0aclk_slv\0aclk_dbi\0pclk\0aux";
		device_type = "pci";
		#interrupt-cells = <0x01>;
		interrupt-map-mask = <0x00 0x00 0x00 0x07>;
		interrupt-map = <0x00 0x00 0x00 0x01 0x56 0x00 0x00 0x00 0x00 0x02 0x56 0x01 0x00 0x00 0x00 0x03 0x56 0x02 0x00 0x00 0x00 0x04 0x56 0x03>;
		linux,pci-domain = <0x00>;
		num-ib-windows = <0x06>;
		num-ob-windows = <0x02>;
		max-link-speed = <0x02>;
		msi-map = <0x00 0x57 0x00 0x1000>;
		num-lanes = <0x01>;
		phys = <0x11 0x02>;
		phy-names = "pcie-phy";
		power-domains = <0x10 0x0f>;
		ranges = <0x1000000 0x00 0xf4100000 0x00 0xf4100000 0x00 0x100000 0x2000000 0x00 0xf4200000 0x00 0xf4200000 0x00 0x1e00000 0x3000000 0x00 0x40000000 0x03 0x00 0x00 0x40000000>;
		resets = <0x0e 0xa1>;
		reset-names = "pipe";
		#address-cells = <0x03>;
		#size-cells = <0x02>;
		status = "disabled";
		phandle = <0xf3>;

		legacy-interrupt-controller {
			#address-cells = <0x00>;
			#interrupt-cells = <0x01>;
			interrupt-controller;
			interrupt-parent = <0x01>;
			interrupts = <0x00 0x48 0x01>;
			phandle = <0x56>;
		};
	};

	mmc@fe2b0000 {
		compatible = "rockchip,rk3568-dw-mshc\0rockchip,rk3288-dw-mshc";
		reg = <0x00 0xfe2b0000 0x00 0x4000>;
		interrupts = <0x00 0x62 0x04>;
		clocks = <0x0e 0xb0 0x0e 0xb1 0x0e 0x18a 0x0e 0x18b>;
		clock-names = "biu\0ciu\0ciu-drive\0ciu-sample";
		fifo-depth = <0x100>;
		max-frequency = <0x8f0d180>;
		resets = <0x0e 0xd4>;
		reset-names = "reset";
		status = "okay";
		broken-cd;
		bus-width = <0x04>;
		cap-sd-highspeed;
		disable-wp;
		pinctrl-names = "default";
		pinctrl-0 = <0x58 0x59 0x5a 0x5b>;
		vqmmc-supply = <0x1a>;
		phandle = <0xf4>;
	};

	mmc@fe2c0000 {
		compatible = "rockchip,rk3568-dw-mshc\0rockchip,rk3288-dw-mshc";
		reg = <0x00 0xfe2c0000 0x00 0x4000>;
		interrupts = <0x00 0x63 0x04>;
		clocks = <0x0e 0xb2 0x0e 0xb3 0x0e 0x18c 0x0e 0x18d>;
		clock-names = "biu\0ciu\0ciu-drive\0ciu-sample";
		fifo-depth = <0x100>;
		max-frequency = <0x8f0d180>;
		resets = <0x0e 0xd6>;
		reset-names = "reset";
		status = "okay";
		supports-sdio;
		bus-width = <0x04>;
		disable-wp;
		cap-sd-highspeed;
		cap-sdio-irq;
		keep-power-in-suspend;
		pinctrl-names = "default";
		pinctrl-0 = <0x5c 0x5d 0x5e>;
		non-removable;
		mmc-pwrseq = <0x5f>;
		phandle = <0xf5>;
	};

	spi@fe300000 {
		compatible = "rockchip,sfc";
		reg = <0x00 0xfe300000 0x00 0x4000>;
		interrupts = <0x00 0x65 0x04>;
		clocks = <0x0e 0x78 0x0e 0x76>;
		clock-names = "clk_sfc\0hclk_sfc";
		pinctrl-0 = <0x60>;
		pinctrl-names = "default";
		status = "disabled";
		phandle = <0xf6>;
	};

	mmc@fe310000 {
		compatible = "rockchip,rk3568-dwcmshc";
		reg = <0x00 0xfe310000 0x00 0x10000>;
		interrupts = <0x00 0x13 0x04>;
		assigned-clocks = <0x0e 0x7b 0x0e 0x7d>;
		assigned-clock-rates = <0xbebc200 0x16e3600>;
		clocks = <0x0e 0x7c 0x0e 0x7a 0x0e 0x79 0x0e 0x7b 0x0e 0x7d>;
		clock-names = "core\0bus\0axi\0block\0timer";
		status = "okay";
		bus-width = <0x08>;
		mmc-hs200-1_8v;
		non-removable;
		vmmc-supply = <0x18>;
		vqmmc-supply = <0x19>;
		phandle = <0xf7>;
	};

	spdif@fe460000 {
		compatible = "rockchip,rk3568-spdif";
		reg = <0x00 0xfe460000 0x00 0x1000>;
		interrupts = <0x00 0x66 0x04>;
		clock-names = "mclk\0hclk";
		clocks = <0x0e 0x5f 0x0e 0x5c>;
		dmas = <0x61 0x01>;
		dma-names = "tx";
		pinctrl-names = "default";
		pinctrl-0 = <0x62>;
		#sound-dai-cells = <0x00>;
		status = "disabled";
		phandle = <0xf8>;
	};

	i2s@fe400000 {
		compatible = "rockchip,rk3568-i2s-tdm";
		reg = <0x00 0xfe400000 0x00 0x1000>;
		interrupts = <0x00 0x34 0x04>;
		assigned-clocks = <0x0e 0x3d 0x0e 0x41>;
		assigned-clock-rates = <0x46cf7100 0x46cf7100>;
		clocks = <0x0e 0x3f 0x0e 0x43 0x0e 0x39>;
		clock-names = "mclk_tx\0mclk_rx\0hclk";
		dmas = <0x61 0x00>;
		dma-names = "tx";
		resets = <0x0e 0x50 0x0e 0x51>;
		reset-names = "tx-m\0rx-m";
		rockchip,grf = <0x1d>;
		#sound-dai-cells = <0x00>;
		status = "disabled";
		phandle = <0x08>;
	};

	i2s@fe410000 {
		compatible = "rockchip,rk3568-i2s-tdm";
		reg = <0x00 0xfe410000 0x00 0x1000>;
		interrupts = <0x00 0x35 0x04>;
		assigned-clocks = <0x0e 0x45 0x0e 0x49>;
		assigned-clock-rates = <0x46cf7100 0x46cf7100>;
		clocks = <0x0e 0x47 0x0e 0x4b 0x0e 0x3a>;
		clock-names = "mclk_tx\0mclk_rx\0hclk";
		dmas = <0x61 0x03 0x61 0x02>;
		dma-names = "rx\0tx";
		resets = <0x0e 0x52 0x0e 0x53>;
		reset-names = "tx-m\0rx-m";
		rockchip,grf = <0x1d>;
		pinctrl-names = "default";
		pinctrl-0 = <0x63 0x64 0x65 0x66 0x67 0x68 0x69 0x6a 0x6b 0x6c 0x6d 0x6e>;
		#sound-dai-cells = <0x00>;
		status = "disabled";
		phandle = <0xf9>;
	};

	i2s@fe430000 {
		compatible = "rockchip,rk3568-i2s-tdm";
		reg = <0x00 0xfe430000 0x00 0x1000>;
		interrupts = <0x00 0x37 0x04>;
		clocks = <0x0e 0x53 0x0e 0x57 0x0e 0x3c>;
		clock-names = "mclk_tx\0mclk_rx\0hclk";
		dmas = <0x61 0x06 0x61 0x07>;
		dma-names = "tx\0rx";
		resets = <0x0e 0x55 0x0e 0x56>;
		reset-names = "tx-m\0rx-m";
		rockchip,grf = <0x1d>;
		#sound-dai-cells = <0x00>;
		status = "disabled";
		phandle = <0xfa>;
	};

	pdm@fe440000 {
		compatible = "rockchip,rk3568-pdm";
		reg = <0x00 0xfe440000 0x00 0x1000>;
		interrupts = <0x00 0x4c 0x04>;
		clocks = <0x0e 0x5a 0x0e 0x59>;
		clock-names = "pdm_clk\0pdm_hclk";
		dmas = <0x61 0x09>;
		dma-names = "rx";
		pinctrl-0 = <0x6f 0x70 0x71 0x72 0x73 0x74>;
		pinctrl-names = "default";
		resets = <0x0e 0x58>;
		reset-names = "pdm-m";
		#sound-dai-cells = <0x00>;
		status = "disabled";
		phandle = <0xfb>;
	};

	dma-controller@fe530000 {
		compatible = "arm,pl330\0arm,primecell";
		reg = <0x00 0xfe530000 0x00 0x4000>;
		interrupts = <0x00 0x0e 0x04 0x00 0x0d 0x04>;
		arm,pl330-periph-burst;
		clocks = <0x0e 0x10d>;
		clock-names = "apb_pclk";
		#dma-cells = <0x01>;
		phandle = <0x23>;
	};

	dma-controller@fe550000 {
		compatible = "arm,pl330\0arm,primecell";
		reg = <0x00 0xfe550000 0x00 0x4000>;
		interrupts = <0x00 0x10 0x04 0x00 0x0f 0x04>;
		arm,pl330-periph-burst;
		clocks = <0x0e 0x10d>;
		clock-names = "apb_pclk";
		#dma-cells = <0x01>;
		phandle = <0x61>;
	};

	i2c@fe5a0000 {
		compatible = "rockchip,rk3568-i2c\0rockchip,rk3399-i2c";
		reg = <0x00 0xfe5a0000 0x00 0x1000>;
		interrupts = <0x00 0x2f 0x04>;
		clocks = <0x0e 0x148 0x0e 0x147>;
		clock-names = "i2c\0pclk";
		pinctrl-0 = <0x75>;
		pinctrl-names = "default";
		#address-cells = <0x01>;
		#size-cells = <0x00>;
		status = "disabled";
		phandle = <0xfc>;
	};

	i2c@fe5b0000 {
		compatible = "rockchip,rk3568-i2c\0rockchip,rk3399-i2c";
		reg = <0x00 0xfe5b0000 0x00 0x1000>;
		interrupts = <0x00 0x30 0x04>;
		clocks = <0x0e 0x14a 0x0e 0x149>;
		clock-names = "i2c\0pclk";
		pinctrl-0 = <0x76>;
		pinctrl-names = "default";
		#address-cells = <0x01>;
		#size-cells = <0x00>;
		status = "disabled";
		phandle = <0xfd>;
	};

	i2c@fe5c0000 {
		compatible = "rockchip,rk3568-i2c\0rockchip,rk3399-i2c";
		reg = <0x00 0xfe5c0000 0x00 0x1000>;
		interrupts = <0x00 0x31 0x04>;
		clocks = <0x0e 0x14c 0x0e 0x14b>;
		clock-names = "i2c\0pclk";
		pinctrl-0 = <0x77>;
		pinctrl-names = "default";
		#address-cells = <0x01>;
		#size-cells = <0x00>;
		status = "disabled";
		phandle = <0xfe>;
	};

	i2c@fe5d0000 {
		compatible = "rockchip,rk3568-i2c\0rockchip,rk3399-i2c";
		reg = <0x00 0xfe5d0000 0x00 0x1000>;
		interrupts = <0x00 0x32 0x04>;
		clocks = <0x0e 0x14e 0x0e 0x14d>;
		clock-names = "i2c\0pclk";
		pinctrl-0 = <0x78>;
		pinctrl-names = "default";
		#address-cells = <0x01>;
		#size-cells = <0x00>;
		status = "disabled";
		phandle = <0xff>;
	};

	i2c@fe5e0000 {
		compatible = "rockchip,rk3568-i2c\0rockchip,rk3399-i2c";
		reg = <0x00 0xfe5e0000 0x00 0x1000>;
		interrupts = <0x00 0x33 0x04>;
		clocks = <0x0e 0x150 0x0e 0x14f>;
		clock-names = "i2c\0pclk";
		pinctrl-0 = <0x79>;
		pinctrl-names = "default";
		#address-cells = <0x01>;
		#size-cells = <0x00>;
		status = "disabled";
		phandle = <0x100>;
	};

	watchdog@fe600000 {
		compatible = "rockchip,rk3568-wdt\0snps,dw-wdt";
		reg = <0x00 0xfe600000 0x00 0x100>;
		interrupts = <0x00 0x95 0x04>;
		clocks = <0x0e 0x116 0x0e 0x115>;
		clock-names = "tclk\0pclk";
		phandle = <0x101>;
	};

	spi@fe610000 {
		compatible = "rockchip,rk3568-spi\0rockchip,rk3066-spi";
		reg = <0x00 0xfe610000 0x00 0x1000>;
		interrupts = <0x00 0x67 0x04>;
		clocks = <0x0e 0x152 0x0e 0x151>;
		clock-names = "spiclk\0apb_pclk";
		dmas = <0x23 0x14 0x23 0x15>;
		dma-names = "tx\0rx";
		pinctrl-names = "default";
		pinctrl-0 = <0x7a 0x7b 0x7c>;
		#address-cells = <0x01>;
		#size-cells = <0x00>;
		status = "disabled";
		phandle = <0x102>;
	};

	spi@fe620000 {
		compatible = "rockchip,rk3568-spi\0rockchip,rk3066-spi";
		reg = <0x00 0xfe620000 0x00 0x1000>;
		interrupts = <0x00 0x68 0x04>;
		clocks = <0x0e 0x154 0x0e 0x153>;
		clock-names = "spiclk\0apb_pclk";
		dmas = <0x23 0x16 0x23 0x17>;
		dma-names = "tx\0rx";
		pinctrl-names = "default";
		pinctrl-0 = <0x7d 0x7e 0x7f>;
		#address-cells = <0x01>;
		#size-cells = <0x00>;
		status = "disabled";
		phandle = <0x103>;
	};

	spi@fe630000 {
		compatible = "rockchip,rk3568-spi\0rockchip,rk3066-spi";
		reg = <0x00 0xfe630000 0x00 0x1000>;
		interrupts = <0x00 0x69 0x04>;
		clocks = <0x0e 0x156 0x0e 0x155>;
		clock-names = "spiclk\0apb_pclk";
		dmas = <0x23 0x18 0x23 0x19>;
		dma-names = "tx\0rx";
		pinctrl-names = "default";
		pinctrl-0 = <0x80 0x81 0x82>;
		#address-cells = <0x01>;
		#size-cells = <0x00>;
		status = "disabled";
		phandle = <0x104>;
	};

	spi@fe640000 {
		compatible = "rockchip,rk3568-spi\0rockchip,rk3066-spi";
		reg = <0x00 0xfe640000 0x00 0x1000>;
		interrupts = <0x00 0x6a 0x04>;
		clocks = <0x0e 0x158 0x0e 0x157>;
		clock-names = "spiclk\0apb_pclk";
		dmas = <0x23 0x1a 0x23 0x1b>;
		dma-names = "tx\0rx";
		pinctrl-names = "default";
		pinctrl-0 = <0x83 0x84 0x85>;
		#address-cells = <0x01>;
		#size-cells = <0x00>;
		status = "disabled";
		phandle = <0x105>;
	};

	serial@fe650000 {
		compatible = "rockchip,rk3568-uart\0snps,dw-apb-uart";
		reg = <0x00 0xfe650000 0x00 0x100>;
		interrupts = <0x00 0x75 0x04>;
		clocks = <0x0e 0x11f 0x0e 0x11c>;
		clock-names = "baudclk\0apb_pclk";
		dmas = <0x23 0x02 0x23 0x03>;
		pinctrl-0 = <0x86 0x87 0x88>;
		pinctrl-names = "default";
		reg-io-width = <0x04>;
		reg-shift = <0x02>;
		status = "okay";
		phandle = <0x106>;

		bluetooth {
			compatible = "brcm,bcm43438-bt";
			clocks = <0x89 0x01>;
			clock-names = "lpo";
			device-wakeup-gpios = <0x8a 0x11 0x00>;
			host-wakeup-gpios = <0x8a 0x10 0x00>;
			shutdown-gpios = <0x8a 0x0f 0x00>;
			max-speed = <0x16e360>;
			pinctrl-names = "default";
			pinctrl-0 = <0x8b 0x8c 0x8d>;
			vbat-supply = <0x22>;
			vddio-supply = <0x8e>;
		};
	};

	serial@fe660000 {
		compatible = "rockchip,rk3568-uart\0snps,dw-apb-uart";
		reg = <0x00 0xfe660000 0x00 0x100>;
		interrupts = <0x00 0x76 0x04>;
		clocks = <0x0e 0x123 0x0e 0x120>;
		clock-names = "baudclk\0apb_pclk";
		dmas = <0x23 0x04 0x23 0x05>;
		pinctrl-0 = <0x8f>;
		pinctrl-names = "default";
		reg-io-width = <0x04>;
		reg-shift = <0x02>;
		status = "okay";
		phandle = <0x107>;
	};

	serial@fe670000 {
		compatible = "rockchip,rk3568-uart\0snps,dw-apb-uart";
		reg = <0x00 0xfe670000 0x00 0x100>;
		interrupts = <0x00 0x77 0x04>;
		clocks = <0x0e 0x127 0x0e 0x124>;
		clock-names = "baudclk\0apb_pclk";
		dmas = <0x23 0x06 0x23 0x07>;
		pinctrl-0 = <0x90>;
		pinctrl-names = "default";
		reg-io-width = <0x04>;
		reg-shift = <0x02>;
		status = "disabled";
		phandle = <0x108>;
	};

	serial@fe680000 {
		compatible = "rockchip,rk3568-uart\0snps,dw-apb-uart";
		reg = <0x00 0xfe680000 0x00 0x100>;
		interrupts = <0x00 0x78 0x04>;
		clocks = <0x0e 0x12b 0x0e 0x128>;
		clock-names = "baudclk\0apb_pclk";
		dmas = <0x23 0x08 0x23 0x09>;
		pinctrl-0 = <0x91>;
		pinctrl-names = "default";
		reg-io-width = <0x04>;
		reg-shift = <0x02>;
		status = "disabled";
		phandle = <0x109>;
	};

	serial@fe690000 {
		compatible = "rockchip,rk3568-uart\0snps,dw-apb-uart";
		reg = <0x00 0xfe690000 0x00 0x100>;
		interrupts = <0x00 0x79 0x04>;
		clocks = <0x0e 0x12f 0x0e 0x12c>;
		clock-names = "baudclk\0apb_pclk";
		dmas = <0x23 0x0a 0x23 0x0b>;
		pinctrl-0 = <0x92>;
		pinctrl-names = "default";
		reg-io-width = <0x04>;
		reg-shift = <0x02>;
		status = "disabled";
		phandle = <0x10a>;
	};

	serial@fe6a0000 {
		compatible = "rockchip,rk3568-uart\0snps,dw-apb-uart";
		reg = <0x00 0xfe6a0000 0x00 0x100>;
		interrupts = <0x00 0x7a 0x04>;
		clocks = <0x0e 0x133 0x0e 0x130>;
		clock-names = "baudclk\0apb_pclk";
		dmas = <0x23 0x0c 0x23 0x0d>;
		pinctrl-0 = <0x93>;
		pinctrl-names = "default";
		reg-io-width = <0x04>;
		reg-shift = <0x02>;
		status = "disabled";
		phandle = <0x10b>;
	};

	serial@fe6b0000 {
		compatible = "rockchip,rk3568-uart\0snps,dw-apb-uart";
		reg = <0x00 0xfe6b0000 0x00 0x100>;
		interrupts = <0x00 0x7b 0x04>;
		clocks = <0x0e 0x137 0x0e 0x134>;
		clock-names = "baudclk\0apb_pclk";
		dmas = <0x23 0x0e 0x23 0x0f>;
		pinctrl-0 = <0x94>;
		pinctrl-names = "default";
		reg-io-width = <0x04>;
		reg-shift = <0x02>;
		status = "disabled";
		phandle = <0x10c>;
	};

	serial@fe6c0000 {
		compatible = "rockchip,rk3568-uart\0snps,dw-apb-uart";
		reg = <0x00 0xfe6c0000 0x00 0x100>;
		interrupts = <0x00 0x7c 0x04>;
		clocks = <0x0e 0x13b 0x0e 0x138>;
		clock-names = "baudclk\0apb_pclk";
		dmas = <0x23 0x10 0x23 0x11>;
		pinctrl-0 = <0x95>;
		pinctrl-names = "default";
		reg-io-width = <0x04>;
		reg-shift = <0x02>;
		status = "disabled";
		phandle = <0x10d>;
	};

	serial@fe6d0000 {
		compatible = "rockchip,rk3568-uart\0snps,dw-apb-uart";
		reg = <0x00 0xfe6d0000 0x00 0x100>;
		interrupts = <0x00 0x7d 0x04>;
		clocks = <0x0e 0x13f 0x0e 0x13c>;
		clock-names = "baudclk\0apb_pclk";
		dmas = <0x23 0x12 0x23 0x13>;
		pinctrl-0 = <0x96>;
		pinctrl-names = "default";
		reg-io-width = <0x04>;
		reg-shift = <0x02>;
		status = "disabled";
		phandle = <0x10e>;
	};

	thermal-zones {
		phandle = <0x10f>;

		cpu-thermal {
			polling-delay-passive = <0x64>;
			polling-delay = <0x3e8>;
			thermal-sensors = <0x97 0x00>;
			phandle = <0x110>;

			trips {

				cpu_alert0 {
					temperature = <0x11170>;
					hysteresis = <0x7d0>;
					type = "passive";
					phandle = <0x98>;
				};

				cpu_alert1 {
					temperature = <0x124f8>;
					hysteresis = <0x7d0>;
					type = "passive";
					phandle = <0x111>;
				};

				cpu_crit {
					temperature = <0x17318>;
					hysteresis = <0x7d0>;
					type = "critical";
					phandle = <0x112>;
				};
			};

			cooling-maps {

				map0 {
					trip = <0x98>;
					cooling-device = <0x09 0xffffffff 0xffffffff 0x0a 0xffffffff 0xffffffff 0x0b 0xffffffff 0xffffffff 0x0c 0xffffffff 0xffffffff>;
				};
			};
		};

		gpu-thermal {
			polling-delay-passive = <0x14>;
			polling-delay = <0x3e8>;
			thermal-sensors = <0x97 0x01>;
			phandle = <0x113>;

			trips {

				gpu-threshold {
					temperature = <0x11170>;
					hysteresis = <0x7d0>;
					type = "passive";
					phandle = <0x114>;
				};

				gpu-target {
					temperature = <0x124f8>;
					hysteresis = <0x7d0>;
					type = "passive";
					phandle = <0x99>;
				};

				gpu-crit {
					temperature = <0x17318>;
					hysteresis = <0x7d0>;
					type = "critical";
					phandle = <0x115>;
				};
			};

			cooling-maps {

				map0 {
					trip = <0x99>;
					cooling-device = <0x9a 0xffffffff 0xffffffff>;
				};
			};
		};
	};

	tsadc@fe710000 {
		compatible = "rockchip,rk3568-tsadc";
		reg = <0x00 0xfe710000 0x00 0x100>;
		interrupts = <0x00 0x73 0x04>;
		assigned-clocks = <0x0e 0x110 0x0e 0x111>;
		assigned-clock-rates = <0x1036640 0xaae60>;
		clocks = <0x0e 0x111 0x0e 0x10f>;
		clock-names = "tsadc\0apb_pclk";
		resets = <0x0e 0x181 0x0e 0x182 0x0e 0x1d7>;
		rockchip,grf = <0x1d>;
		rockchip,hw-tshut-temp = <0x17318>;
		pinctrl-names = "init\0default\0sleep";
		pinctrl-0 = <0x9b>;
		pinctrl-1 = <0x9c>;
		pinctrl-2 = <0x9b>;
		#thermal-sensor-cells = <0x01>;
		status = "okay";
		phandle = <0x97>;
	};

	saradc@fe720000 {
		compatible = "rockchip,rk3568-saradc\0rockchip,rk3399-saradc";
		reg = <0x00 0xfe720000 0x00 0x100>;
		interrupts = <0x00 0x5d 0x04>;
		clocks = <0x0e 0x113 0x0e 0x112>;
		clock-names = "saradc\0apb_pclk";
		resets = <0x0e 0x180>;
		reset-names = "saradc-apb";
		#io-channel-cells = <0x01>;
		status = "okay";
		vref-supply = <0x9d>;
		phandle = <0x116>;
	};

	pwm@fe6e0000 {
		compatible = "rockchip,rk3568-pwm\0rockchip,rk3328-pwm";
		reg = <0x00 0xfe6e0000 0x00 0x10>;
		clocks = <0x0e 0x15a 0x0e 0x159>;
		clock-names = "pwm\0pclk";
		pinctrl-0 = <0x9e>;
		pinctrl-names = "default";
		#pwm-cells = <0x03>;
		status = "disabled";
		phandle = <0x117>;
	};

	pwm@fe6e0010 {
		compatible = "rockchip,rk3568-pwm\0rockchip,rk3328-pwm";
		reg = <0x00 0xfe6e0010 0x00 0x10>;
		clocks = <0x0e 0x15a 0x0e 0x159>;
		clock-names = "pwm\0pclk";
		pinctrl-0 = <0x9f>;
		pinctrl-names = "default";
		#pwm-cells = <0x03>;
		status = "disabled";
		phandle = <0x118>;
	};

	pwm@fe6e0020 {
		compatible = "rockchip,rk3568-pwm\0rockchip,rk3328-pwm";
		reg = <0x00 0xfe6e0020 0x00 0x10>;
		clocks = <0x0e 0x15a 0x0e 0x159>;
		clock-names = "pwm\0pclk";
		pinctrl-0 = <0xa0>;
		pinctrl-names = "default";
		#pwm-cells = <0x03>;
		status = "disabled";
		phandle = <0x119>;
	};

	pwm@fe6e0030 {
		compatible = "rockchip,rk3568-pwm\0rockchip,rk3328-pwm";
		reg = <0x00 0xfe6e0030 0x00 0x10>;
		clocks = <0x0e 0x15a 0x0e 0x159>;
		clock-names = "pwm\0pclk";
		pinctrl-0 = <0xa1>;
		pinctrl-names = "default";
		#pwm-cells = <0x03>;
		status = "disabled";
		phandle = <0x11a>;
	};

	pwm@fe6f0000 {
		compatible = "rockchip,rk3568-pwm\0rockchip,rk3328-pwm";
		reg = <0x00 0xfe6f0000 0x00 0x10>;
		clocks = <0x0e 0x15d 0x0e 0x15c>;
		clock-names = "pwm\0pclk";
		pinctrl-0 = <0xa2>;
		pinctrl-names = "default";
		#pwm-cells = <0x03>;
		status = "disabled";
		phandle = <0x11b>;
	};

	pwm@fe6f0010 {
		compatible = "rockchip,rk3568-pwm\0rockchip,rk3328-pwm";
		reg = <0x00 0xfe6f0010 0x00 0x10>;
		clocks = <0x0e 0x15d 0x0e 0x15c>;
		clock-names = "pwm\0pclk";
		pinctrl-0 = <0xa3>;
		pinctrl-names = "default";
		#pwm-cells = <0x03>;
		status = "disabled";
		phandle = <0x11c>;
	};

	pwm@fe6f0020 {
		compatible = "rockchip,rk3568-pwm\0rockchip,rk3328-pwm";
		reg = <0x00 0xfe6f0020 0x00 0x10>;
		clocks = <0x0e 0x15d 0x0e 0x15c>;
		clock-names = "pwm\0pclk";
		pinctrl-0 = <0xa4>;
		pinctrl-names = "default";
		#pwm-cells = <0x03>;
		status = "disabled";
		phandle = <0x11d>;
	};

	pwm@fe6f0030 {
		compatible = "rockchip,rk3568-pwm\0rockchip,rk3328-pwm";
		reg = <0x00 0xfe6f0030 0x00 0x10>;
		clocks = <0x0e 0x15d 0x0e 0x15c>;
		clock-names = "pwm\0pclk";
		pinctrl-0 = <0xa5>;
		pinctrl-names = "default";
		#pwm-cells = <0x03>;
		status = "disabled";
		phandle = <0x11e>;
	};

	pwm@fe700000 {
		compatible = "rockchip,rk3568-pwm\0rockchip,rk3328-pwm";
		reg = <0x00 0xfe700000 0x00 0x10>;
		clocks = <0x0e 0x160 0x0e 0x15f>;
		clock-names = "pwm\0pclk";
		pinctrl-0 = <0xa6>;
		pinctrl-names = "default";
		#pwm-cells = <0x03>;
		status = "disabled";
		phandle = <0x11f>;
	};

	pwm@fe700010 {
		compatible = "rockchip,rk3568-pwm\0rockchip,rk3328-pwm";
		reg = <0x00 0xfe700010 0x00 0x10>;
		clocks = <0x0e 0x160 0x0e 0x15f>;
		clock-names = "pwm\0pclk";
		pinctrl-0 = <0xa7>;
		pinctrl-names = "default";
		#pwm-cells = <0x03>;
		status = "disabled";
		phandle = <0x120>;
	};

	pwm@fe700020 {
		compatible = "rockchip,rk3568-pwm\0rockchip,rk3328-pwm";
		reg = <0x00 0xfe700020 0x00 0x10>;
		clocks = <0x0e 0x160 0x0e 0x15f>;
		clock-names = "pwm\0pclk";
		pinctrl-0 = <0xa8>;
		pinctrl-names = "default";
		#pwm-cells = <0x03>;
		status = "disabled";
		phandle = <0x121>;
	};

	pwm@fe700030 {
		compatible = "rockchip,rk3568-pwm\0rockchip,rk3328-pwm";
		reg = <0x00 0xfe700030 0x00 0x10>;
		clocks = <0x0e 0x160 0x0e 0x15f>;
		clock-names = "pwm\0pclk";
		pinctrl-0 = <0xa9>;
		pinctrl-names = "default";
		#pwm-cells = <0x03>;
		status = "disabled";
		phandle = <0x122>;
	};

	phy@fe830000 {
		compatible = "rockchip,rk3568-naneng-combphy";
		reg = <0x00 0xfe830000 0x00 0x100>;
		clocks = <0x1c 0x22 0x0e 0x17d 0x0e 0x7f>;
		clock-names = "ref\0apb\0pipe";
		assigned-clocks = <0x1c 0x22>;
		assigned-clock-rates = <0x5f5e100>;
		resets = <0x0e 0x1c7>;
		rockchip,pipe-grf = <0xaa>;
		rockchip,pipe-phy-grf = <0xab>;
		#phy-cells = <0x01>;
		status = "disabled";
		phandle = <0x0f>;
	};

	phy@fe840000 {
		compatible = "rockchip,rk3568-naneng-combphy";
		reg = <0x00 0xfe840000 0x00 0x100>;
		clocks = <0x1c 0x25 0x0e 0x17e 0x0e 0x7f>;
		clock-names = "ref\0apb\0pipe";
		assigned-clocks = <0x1c 0x25>;
		assigned-clock-rates = <0x5f5e100>;
		resets = <0x0e 0x1c9>;
		rockchip,pipe-grf = <0xaa>;
		rockchip,pipe-phy-grf = <0xac>;
		#phy-cells = <0x01>;
		status = "disabled";
		phandle = <0x11>;
	};

	phy@fe870000 {
		compatible = "rockchip,rk3568-csi-dphy";
		reg = <0x00 0xfe870000 0x00 0x10000>;
		clocks = <0x0e 0x179>;
		clock-names = "pclk";
		#phy-cells = <0x00>;
		resets = <0x0e 0x1ba>;
		reset-names = "apb";
		rockchip,grf = <0x1d>;
		status = "disabled";
		phandle = <0x123>;
	};

	mipi-dphy@fe850000 {
		compatible = "rockchip,rk3568-dsi-dphy";
		reg = <0x00 0xfe850000 0x00 0x10000>;
		clock-names = "ref\0pclk";
		clocks = <0x1c 0x17 0x0e 0x17a>;
		#phy-cells = <0x00>;
		power-domains = <0x10 0x09>;
		reset-names = "apb";
		resets = <0x0e 0x1bb>;
		status = "disabled";
		phandle = <0x51>;
	};

	mipi-dphy@fe860000 {
		compatible = "rockchip,rk3568-dsi-dphy";
		reg = <0x00 0xfe860000 0x00 0x10000>;
		clock-names = "ref\0pclk";
		clocks = <0x1c 0x19 0x0e 0x17b>;
		#phy-cells = <0x00>;
		power-domains = <0x10 0x09>;
		reset-names = "apb";
		resets = <0x0e 0x1bc>;
		status = "disabled";
		phandle = <0x52>;
	};

	usb2phy@fe8a0000 {
		compatible = "rockchip,rk3568-usb2phy";
		reg = <0x00 0xfe8a0000 0x00 0x10000>;
		clocks = <0x1c 0x13>;
		clock-names = "phyclk";
		clock-output-names = "clk_usbphy0_480m";
		interrupts = <0x00 0x87 0x04>;
		rockchip,usbgrf = <0xad>;
		#clock-cells = <0x00>;
		status = "okay";
		phandle = <0x13>;

		host-port {
			#phy-cells = <0x00>;
			status = "okay";
			phandle = <0x14>;
		};

		otg-port {
			#phy-cells = <0x00>;
			status = "okay";
			phandle = <0x12>;
		};
	};

	usb2phy@fe8b0000 {
		compatible = "rockchip,rk3568-usb2phy";
		reg = <0x00 0xfe8b0000 0x00 0x10000>;
		clocks = <0x1c 0x15>;
		clock-names = "phyclk";
		clock-output-names = "clk_usbphy1_480m";
		interrupts = <0x00 0x88 0x04>;
		rockchip,usbgrf = <0xae>;
		#clock-cells = <0x00>;
		status = "disabled";
		phandle = <0x124>;

		host-port {
			#phy-cells = <0x00>;
			status = "disabled";
			phandle = <0x16>;
		};

		otg-port {
			#phy-cells = <0x00>;
			status = "disabled";
			phandle = <0x15>;
		};
	};

	rng@fe388000 {
		compatible = "rockchip,rk3568-rng";
		reg = <0x00 0xfe388000 0x00 0x4000>;
		clocks = <0x0e 0x70 0x0e 0x6f>;
		clock-names = "trng_clk\0trng_hclk";
		resets = <0x0e 0x6d>;
		reset-names = "reset";
		phandle = <0x125>;
	};

	pinctrl {
		compatible = "rockchip,rk3568-pinctrl";
		rockchip,grf = <0x1d>;
		rockchip,pmu = <0xaf>;
		#address-cells = <0x02>;
		#size-cells = <0x02>;
		ranges;
		phandle = <0x126>;

		gpio@fdd60000 {
			compatible = "rockchip,gpio-bank";
			reg = <0x00 0xfdd60000 0x00 0x100>;
			interrupts = <0x00 0x21 0x04>;
			clocks = <0x1c 0x2e 0x1c 0x0c>;
			gpio-controller;
			#gpio-cells = <0x02>;
			interrupt-controller;
			#interrupt-cells = <0x02>;
			phandle = <0x20>;
		};

		gpio@fe740000 {
			compatible = "rockchip,gpio-bank";
			reg = <0x00 0xfe740000 0x00 0x100>;
			interrupts = <0x00 0x22 0x04>;
			clocks = <0x0e 0x163 0x0e 0x164>;
			gpio-controller;
			#gpio-cells = <0x02>;
			interrupt-controller;
			#interrupt-cells = <0x02>;
			phandle = <0x127>;
		};

		gpio@fe750000 {
			compatible = "rockchip,gpio-bank";
			reg = <0x00 0xfe750000 0x00 0x100>;
			interrupts = <0x00 0x23 0x04>;
			clocks = <0x0e 0x165 0x0e 0x166>;
			gpio-controller;
			#gpio-cells = <0x02>;
			interrupt-controller;
			#interrupt-cells = <0x02>;
			phandle = <0x8a>;
		};

		gpio@fe760000 {
			compatible = "rockchip,gpio-bank";
			reg = <0x00 0xfe760000 0x00 0x100>;
			interrupts = <0x00 0x24 0x04>;
			clocks = <0x0e 0x167 0x0e 0x168>;
			gpio-controller;
			#gpio-cells = <0x02>;
			interrupt-controller;
			#interrupt-cells = <0x02>;
			phandle = <0x4e>;
		};

		gpio@fe770000 {
			compatible = "rockchip,gpio-bank";
			reg = <0x00 0xfe770000 0x00 0x100>;
			interrupts = <0x00 0x25 0x04>;
			clocks = <0x0e 0x169 0x0e 0x16a>;
			gpio-controller;
			#gpio-cells = <0x02>;
			interrupt-controller;
			#interrupt-cells = <0x02>;
			phandle = <0x128>;
		};

		pcfg-pull-up {
			bias-pull-up;
			phandle = <0xb2>;
		};

		pcfg-pull-down {
			bias-pull-down;
			phandle = <0xb8>;
		};

		pcfg-pull-none {
			bias-disable;
			phandle = <0xb0>;
		};

		pcfg-pull-none-drv-level-0 {
			bias-disable;
			drive-strength = <0x00>;
			phandle = <0x129>;
		};

		pcfg-pull-none-drv-level-1 {
			bias-disable;
			drive-strength = <0x01>;
			phandle = <0xb4>;
		};

		pcfg-pull-none-drv-level-2 {
			bias-disable;
			drive-strength = <0x02>;
			phandle = <0xb3>;
		};

		pcfg-pull-none-drv-level-3 {
			bias-disable;
			drive-strength = <0x03>;
			phandle = <0xb7>;
		};

		pcfg-pull-none-drv-level-4 {
			bias-disable;
			drive-strength = <0x04>;
			phandle = <0x12a>;
		};

		pcfg-pull-none-drv-level-5 {
			bias-disable;
			drive-strength = <0x05>;
			phandle = <0x12b>;
		};

		pcfg-pull-none-drv-level-6 {
			bias-disable;
			drive-strength = <0x06>;
			phandle = <0x12c>;
		};

		pcfg-pull-none-drv-level-7 {
			bias-disable;
			drive-strength = <0x07>;
			phandle = <0x12d>;
		};

		pcfg-pull-none-drv-level-8 {
			bias-disable;
			drive-strength = <0x08>;
			phandle = <0x12e>;
		};

		pcfg-pull-none-drv-level-9 {
			bias-disable;
			drive-strength = <0x09>;
			phandle = <0x12f>;
		};

		pcfg-pull-none-drv-level-10 {
			bias-disable;
			drive-strength = <0x0a>;
			phandle = <0x130>;
		};

		pcfg-pull-none-drv-level-11 {
			bias-disable;
			drive-strength = <0x0b>;
			phandle = <0x131>;
		};

		pcfg-pull-none-drv-level-12 {
			bias-disable;
			drive-strength = <0x0c>;
			phandle = <0x132>;
		};

		pcfg-pull-none-drv-level-13 {
			bias-disable;
			drive-strength = <0x0d>;
			phandle = <0x133>;
		};

		pcfg-pull-none-drv-level-14 {
			bias-disable;
			drive-strength = <0x0e>;
			phandle = <0x134>;
		};

		pcfg-pull-none-drv-level-15 {
			bias-disable;
			drive-strength = <0x0f>;
			phandle = <0x135>;
		};

		pcfg-pull-up-drv-level-0 {
			bias-pull-up;
			drive-strength = <0x00>;
			phandle = <0x136>;
		};

		pcfg-pull-up-drv-level-1 {
			bias-pull-up;
			drive-strength = <0x01>;
			phandle = <0xb6>;
		};

		pcfg-pull-up-drv-level-2 {
			bias-pull-up;
			drive-strength = <0x02>;
			phandle = <0xb1>;
		};

		pcfg-pull-up-drv-level-3 {
			bias-pull-up;
			drive-strength = <0x03>;
			phandle = <0x137>;
		};

		pcfg-pull-up-drv-level-4 {
			bias-pull-up;
			drive-strength = <0x04>;
			phandle = <0x138>;
		};

		pcfg-pull-up-drv-level-5 {
			bias-pull-up;
			drive-strength = <0x05>;
			phandle = <0x139>;
		};

		pcfg-pull-up-drv-level-6 {
			bias-pull-up;
			drive-strength = <0x06>;
			phandle = <0x13a>;
		};

		pcfg-pull-up-drv-level-7 {
			bias-pull-up;
			drive-strength = <0x07>;
			phandle = <0x13b>;
		};

		pcfg-pull-up-drv-level-8 {
			bias-pull-up;
			drive-strength = <0x08>;
			phandle = <0x13c>;
		};

		pcfg-pull-up-drv-level-9 {
			bias-pull-up;
			drive-strength = <0x09>;
			phandle = <0x13d>;
		};

		pcfg-pull-up-drv-level-10 {
			bias-pull-up;
			drive-strength = <0x0a>;
			phandle = <0x13e>;
		};

		pcfg-pull-up-drv-level-11 {
			bias-pull-up;
			drive-strength = <0x0b>;
			phandle = <0x13f>;
		};

		pcfg-pull-up-drv-level-12 {
			bias-pull-up;
			drive-strength = <0x0c>;
			phandle = <0x140>;
		};

		pcfg-pull-up-drv-level-13 {
			bias-pull-up;
			drive-strength = <0x0d>;
			phandle = <0x141>;
		};

		pcfg-pull-up-drv-level-14 {
			bias-pull-up;
			drive-strength = <0x0e>;
			phandle = <0x142>;
		};

		pcfg-pull-up-drv-level-15 {
			bias-pull-up;
			drive-strength = <0x0f>;
			phandle = <0x143>;
		};

		pcfg-pull-down-drv-level-0 {
			bias-pull-down;
			drive-strength = <0x00>;
			phandle = <0x144>;
		};

		pcfg-pull-down-drv-level-1 {
			bias-pull-down;
			drive-strength = <0x01>;
			phandle = <0x145>;
		};

		pcfg-pull-down-drv-level-2 {
			bias-pull-down;
			drive-strength = <0x02>;
			phandle = <0x146>;
		};

		pcfg-pull-down-drv-level-3 {
			bias-pull-down;
			drive-strength = <0x03>;
			phandle = <0x147>;
		};

		pcfg-pull-down-drv-level-4 {
			bias-pull-down;
			drive-strength = <0x04>;
			phandle = <0x148>;
		};

		pcfg-pull-down-drv-level-5 {
			bias-pull-down;
			drive-strength = <0x05>;
			phandle = <0x149>;
		};

		pcfg-pull-down-drv-level-6 {
			bias-pull-down;
			drive-strength = <0x06>;
			phandle = <0x14a>;
		};

		pcfg-pull-down-drv-level-7 {
			bias-pull-down;
			drive-strength = <0x07>;
			phandle = <0x14b>;
		};

		pcfg-pull-down-drv-level-8 {
			bias-pull-down;
			drive-strength = <0x08>;
			phandle = <0x14c>;
		};

		pcfg-pull-down-drv-level-9 {
			bias-pull-down;
			drive-strength = <0x09>;
			phandle = <0x14d>;
		};

		pcfg-pull-down-drv-level-10 {
			bias-pull-down;
			drive-strength = <0x0a>;
			phandle = <0x14e>;
		};

		pcfg-pull-down-drv-level-11 {
			bias-pull-down;
			drive-strength = <0x0b>;
			phandle = <0x14f>;
		};

		pcfg-pull-down-drv-level-12 {
			bias-pull-down;
			drive-strength = <0x0c>;
			phandle = <0x150>;
		};

		pcfg-pull-down-drv-level-13 {
			bias-pull-down;
			drive-strength = <0x0d>;
			phandle = <0x151>;
		};

		pcfg-pull-down-drv-level-14 {
			bias-pull-down;
			drive-strength = <0x0e>;
			phandle = <0x152>;
		};

		pcfg-pull-down-drv-level-15 {
			bias-pull-down;
			drive-strength = <0x0f>;
			phandle = <0x153>;
		};

		pcfg-pull-up-smt {
			bias-pull-up;
			input-schmitt-enable;
			phandle = <0x154>;
		};

		pcfg-pull-down-smt {
			bias-pull-down;
			input-schmitt-enable;
			phandle = <0x155>;
		};

		pcfg-pull-none-smt {
			bias-disable;
			input-schmitt-enable;
			phandle = <0xb5>;
		};

		pcfg-pull-none-drv-level-0-smt {
			bias-disable;
			drive-strength = <0x00>;
			input-schmitt-enable;
			phandle = <0x156>;
		};

		pcfg-output-high {
			output-high;
			phandle = <0x157>;
		};

		pcfg-output-low {
			output-low;
			phandle = <0x158>;
		};

		acodec {

			acodec-pins {
				rockchip,pins = <0x01 0x09 0x05 0xb0 0x01 0x01 0x05 0xb0 0x01 0x00 0x05 0xb0 0x01 0x07 0x05 0xb0 0x01 0x08 0x05 0xb0 0x01 0x03 0x05 0xb0 0x01 0x05 0x05 0xb0>;
				phandle = <0x159>;
			};
		};

		audiopwm {

			audiopwm-lout {
				rockchip,pins = <0x01 0x00 0x04 0xb0>;
				phandle = <0x15a>;
			};

			audiopwm-loutn {
				rockchip,pins = <0x01 0x01 0x06 0xb0>;
				phandle = <0x15b>;
			};

			audiopwm-loutp {
				rockchip,pins = <0x01 0x00 0x06 0xb0>;
				phandle = <0x15c>;
			};

			audiopwm-rout {
				rockchip,pins = <0x01 0x01 0x04 0xb0>;
				phandle = <0x15d>;
			};

			audiopwm-routn {
				rockchip,pins = <0x01 0x07 0x04 0xb0>;
				phandle = <0x15e>;
			};

			audiopwm-routp {
				rockchip,pins = <0x01 0x06 0x04 0xb0>;
				phandle = <0x15f>;
			};
		};

		bt656 {

			bt656m0-pins {
				rockchip,pins = <0x03 0x00 0x02 0xb0 0x02 0x18 0x02 0xb0 0x02 0x19 0x02 0xb0 0x02 0x1a 0x02 0xb0 0x02 0x1b 0x02 0xb0 0x02 0x1c 0x02 0xb0 0x02 0x1d 0x02 0xb0 0x02 0x1e 0x02 0xb0 0x02 0x1f 0x02 0xb0>;
				phandle = <0x160>;
			};

			bt656m1-pins {
				rockchip,pins = <0x04 0x0c 0x05 0xb0 0x03 0x16 0x05 0xb0 0x03 0x17 0x05 0xb0 0x03 0x18 0x05 0xb0 0x03 0x19 0x05 0xb0 0x03 0x1a 0x05 0xb0 0x03 0x1b 0x05 0xb0 0x03 0x1c 0x05 0xb0 0x03 0x1d 0x05 0xb0>;
				phandle = <0x161>;
			};
		};

		bt1120 {

			bt1120-pins {
				rockchip,pins = <0x03 0x06 0x02 0xb0 0x03 0x01 0x02 0xb0 0x03 0x02 0x02 0xb0 0x03 0x03 0x02 0xb0 0x03 0x04 0x02 0xb0 0x03 0x05 0x02 0xb0 0x03 0x07 0x02 0xb0 0x03 0x08 0x02 0xb0 0x03 0x09 0x02 0xb0 0x03 0x0a 0x02 0xb0 0x03 0x0b 0x02 0xb0 0x03 0x0c 0x02 0xb0 0x03 0x0d 0x02 0xb0 0x03 0x0e 0x02 0xb0 0x03 0x11 0x02 0xb0 0x03 0x12 0x02 0xb0 0x03 0x13 0x02 0xb0>;
				phandle = <0x162>;
			};
		};

		cam {

			cam-clkout0 {
				rockchip,pins = <0x04 0x07 0x01 0xb0>;
				phandle = <0x163>;
			};

			cam-clkout1 {
				rockchip,pins = <0x04 0x08 0x01 0xb0>;
				phandle = <0x164>;
			};
		};

		can0 {

			can0m0-pins {
				rockchip,pins = <0x00 0x0c 0x02 0xb0 0x00 0x0b 0x02 0xb0>;
				phandle = <0x165>;
			};

			can0m1-pins {
				rockchip,pins = <0x02 0x02 0x04 0xb0 0x02 0x01 0x04 0xb0>;
				phandle = <0x166>;
			};
		};

		can1 {

			can1m0-pins {
				rockchip,pins = <0x01 0x00 0x03 0xb0 0x01 0x01 0x03 0xb0>;
				phandle = <0x167>;
			};

			can1m1-pins {
				rockchip,pins = <0x04 0x12 0x03 0xb0 0x04 0x13 0x03 0xb0>;
				phandle = <0x168>;
			};
		};

		can2 {

			can2m0-pins {
				rockchip,pins = <0x04 0x0c 0x03 0xb0 0x04 0x0d 0x03 0xb0>;
				phandle = <0x169>;
			};

			can2m1-pins {
				rockchip,pins = <0x02 0x09 0x04 0xb0 0x02 0x0a 0x04 0xb0>;
				phandle = <0x16a>;
			};
		};

		cif {

			cif-clk {
				rockchip,pins = <0x04 0x10 0x01 0xb0>;
				phandle = <0x16b>;
			};

			cif-dvp-clk {
				rockchip,pins = <0x04 0x11 0x01 0xb0 0x04 0x0e 0x01 0xb0 0x04 0x0f 0x01 0xb0>;
				phandle = <0x16c>;
			};

			cif-dvp-bus16 {
				rockchip,pins = <0x03 0x1e 0x01 0xb0 0x03 0x1f 0x01 0xb0 0x04 0x00 0x01 0xb0 0x04 0x01 0x01 0xb0 0x04 0x02 0x01 0xb0 0x04 0x03 0x01 0xb0 0x04 0x04 0x01 0xb0 0x04 0x05 0x01 0xb0>;
				phandle = <0x16d>;
			};

			cif-dvp-bus8 {
				rockchip,pins = <0x03 0x16 0x01 0xb0 0x03 0x17 0x01 0xb0 0x03 0x18 0x01 0xb0 0x03 0x19 0x01 0xb0 0x03 0x1a 0x01 0xb0 0x03 0x1b 0x01 0xb0 0x03 0x1c 0x01 0xb0 0x03 0x1d 0x01 0xb0>;
				phandle = <0x16e>;
			};
		};

		clk32k {

			clk32k-in {
				rockchip,pins = <0x00 0x08 0x01 0xb0>;
				phandle = <0x16f>;
			};

			clk32k-out0 {
				rockchip,pins = <0x00 0x08 0x02 0xb0>;
				phandle = <0x0d>;
			};

			clk32k-out1 {
				rockchip,pins = <0x02 0x16 0x01 0xb0>;
				phandle = <0x170>;
			};
		};

		cpu {

			cpu-pins {
				rockchip,pins = <0x00 0x0f 0x02 0xb0>;
				phandle = <0x171>;
			};
		};

		ebc {

			ebc-extern {
				rockchip,pins = <0x04 0x07 0x02 0xb0 0x04 0x08 0x02 0xb0 0x04 0x09 0x02 0xb0 0x04 0x0d 0x02 0xb0 0x04 0x0a 0x02 0xb0>;
				phandle = <0x172>;
			};

			ebc-pins {
				rockchip,pins = <0x04 0x10 0x02 0xb0 0x04 0x0b 0x02 0xb0 0x04 0x0c 0x02 0xb0 0x04 0x06 0x02 0xb0 0x04 0x11 0x02 0xb0 0x03 0x16 0x02 0xb0 0x03 0x17 0x02 0xb0 0x03 0x18 0x02 0xb0 0x03 0x19 0x02 0xb0 0x03 0x1a 0x02 0xb0 0x03 0x1b 0x02 0xb0 0x03 0x1c 0x02 0xb0 0x03 0x1d 0x02 0xb0 0x03 0x1e 0x02 0xb0 0x03 0x1f 0x02 0xb0 0x04 0x00 0x02 0xb0 0x04 0x01 0x02 0xb0 0x04 0x02 0x02 0xb0 0x04 0x03 0x02 0xb0 0x04 0x04 0x02 0xb0 0x04 0x05 0x02 0xb0 0x04 0x0e 0x02 0xb0 0x04 0x0f 0x02 0xb0>;
				phandle = <0x173>;
			};
		};

		edpdp {

			edpdpm0-pins {
				rockchip,pins = <0x04 0x14 0x01 0xb0>;
				phandle = <0x174>;
			};

			edpdpm1-pins {
				rockchip,pins = <0x00 0x12 0x02 0xb0>;
				phandle = <0x175>;
			};
		};

		emmc {

			emmc-rstnout {
				rockchip,pins = <0x01 0x17 0x01 0xb0>;
				phandle = <0x176>;
			};

			emmc-bus8 {
				rockchip,pins = <0x01 0x0c 0x01 0xb1 0x01 0x0d 0x01 0xb1 0x01 0x0e 0x01 0xb1 0x01 0x0f 0x01 0xb1 0x01 0x10 0x01 0xb1 0x01 0x11 0x01 0xb1 0x01 0x12 0x01 0xb1 0x01 0x13 0x01 0xb1>;
				phandle = <0x177>;
			};

			emmc-clk {
				rockchip,pins = <0x01 0x15 0x01 0xb1>;
				phandle = <0x178>;
			};

			emmc-cmd {
				rockchip,pins = <0x01 0x14 0x01 0xb1>;
				phandle = <0x179>;
			};

			emmc-datastrobe {
				rockchip,pins = <0x01 0x16 0x01 0xb0>;
				phandle = <0x17a>;
			};
		};

		eth0 {

			eth0-pins {
				rockchip,pins = <0x02 0x11 0x02 0xb0>;
				phandle = <0x17b>;
			};
		};

		eth1 {

			eth1m0-pins {
				rockchip,pins = <0x03 0x08 0x03 0xb0>;
				phandle = <0x17c>;
			};

			eth1m1-pins {
				rockchip,pins = <0x04 0x0b 0x03 0xb0>;
				phandle = <0x17d>;
			};
		};

		flash {

			flash-pins {
				rockchip,pins = <0x01 0x18 0x02 0xb0 0x01 0x16 0x03 0xb0 0x01 0x1b 0x02 0xb0 0x01 0x1c 0x02 0xb0 0x01 0x0c 0x02 0xb0 0x01 0x0d 0x02 0xb0 0x01 0x0e 0x02 0xb0 0x01 0x0f 0x02 0xb0 0x01 0x10 0x02 0xb0 0x01 0x11 0x02 0xb0 0x01 0x12 0x02 0xb0 0x01 0x13 0x02 0xb0 0x01 0x15 0x02 0xb0 0x01 0x1a 0x02 0xb0 0x01 0x19 0x02 0xb0 0x00 0x07 0x01 0xb0 0x01 0x17 0x03 0xb0 0x01 0x14 0x02 0xb0>;
				phandle = <0x17e>;
			};
		};

		fspi {

			fspi-pins {
				rockchip,pins = <0x01 0x18 0x01 0xb0 0x01 0x1b 0x01 0xb0 0x01 0x19 0x01 0xb0 0x01 0x1a 0x01 0xb0 0x01 0x17 0x02 0xb0 0x01 0x1c 0x01 0xb0>;
				phandle = <0x60>;
			};

			fspi-cs1 {
				rockchip,pins = <0x01 0x16 0x02 0xb2>;
				phandle = <0x17f>;
			};
		};

		gmac0 {

			gmac0-miim {
				rockchip,pins = <0x02 0x13 0x02 0xb0 0x02 0x14 0x02 0xb0>;
				phandle = <0x180>;
			};

			gmac0-clkinout {
				rockchip,pins = <0x02 0x12 0x02 0xb0>;
				phandle = <0x181>;
			};

			gmac0-rx-er {
				rockchip,pins = <0x02 0x15 0x02 0xb0>;
				phandle = <0x182>;
			};

			gmac0-rx-bus2 {
				rockchip,pins = <0x02 0x0e 0x01 0xb0 0x02 0x0f 0x02 0xb0 0x02 0x10 0x02 0xb0>;
				phandle = <0x183>;
			};

			gmac0-tx-bus2 {
				rockchip,pins = <0x02 0x0b 0x01 0xb3 0x02 0x0c 0x01 0xb3 0x02 0x0d 0x01 0xb0>;
				phandle = <0x184>;
			};

			gmac0-rgmii-clk {
				rockchip,pins = <0x02 0x05 0x02 0xb0 0x02 0x08 0x02 0xb4>;
				phandle = <0x185>;
			};

			gmac0-rgmii-bus {
				rockchip,pins = <0x02 0x03 0x02 0xb0 0x02 0x04 0x02 0xb0 0x02 0x06 0x02 0xb3 0x02 0x07 0x02 0xb3>;
				phandle = <0x186>;
			};
		};

		gmac1 {

			gmac1m0-miim {
				rockchip,pins = <0x03 0x14 0x03 0xb0 0x03 0x15 0x03 0xb0>;
				phandle = <0x48>;
			};

			gmac1m0-clkinout {
				rockchip,pins = <0x03 0x10 0x03 0xb0>;
				phandle = <0x4c>;
			};

			gmac1m0-rx-er {
				rockchip,pins = <0x03 0x0c 0x03 0xb0>;
				phandle = <0x187>;
			};

			gmac1m0-rx-bus2 {
				rockchip,pins = <0x03 0x09 0x03 0xb0 0x03 0x0a 0x03 0xb0 0x03 0x0b 0x03 0xb0>;
				phandle = <0x4a>;
			};

			gmac1m0-tx-bus2 {
				rockchip,pins = <0x03 0x0d 0x03 0xb3 0x03 0x0e 0x03 0xb3 0x03 0x0f 0x03 0xb0>;
				phandle = <0x49>;
			};

			gmac1m0-rgmii-clk {
				rockchip,pins = <0x03 0x07 0x03 0xb0 0x03 0x06 0x03 0xb4>;
				phandle = <0x4b>;
			};

			gmac1m0-rgmii-bus {
				rockchip,pins = <0x03 0x04 0x03 0xb0 0x03 0x05 0x03 0xb0 0x03 0x02 0x03 0xb3 0x03 0x03 0x03 0xb3>;
				phandle = <0x4d>;
			};

			gmac1m1-miim {
				rockchip,pins = <0x04 0x0e 0x03 0xb0 0x04 0x0f 0x03 0xb0>;
				phandle = <0x188>;
			};

			gmac1m1-clkinout {
				rockchip,pins = <0x04 0x11 0x03 0xb0>;
				phandle = <0x189>;
			};

			gmac1m1-rx-er {
				rockchip,pins = <0x04 0x0a 0x03 0xb0>;
				phandle = <0x18a>;
			};

			gmac1m1-rx-bus2 {
				rockchip,pins = <0x04 0x07 0x03 0xb0 0x04 0x08 0x03 0xb0 0x04 0x09 0x03 0xb0>;
				phandle = <0x18b>;
			};

			gmac1m1-tx-bus2 {
				rockchip,pins = <0x04 0x04 0x03 0xb3 0x04 0x05 0x03 0xb3 0x04 0x06 0x03 0xb0>;
				phandle = <0x18c>;
			};

			gmac1m1-rgmii-clk {
				rockchip,pins = <0x04 0x03 0x03 0xb0 0x04 0x00 0x03 0xb4>;
				phandle = <0x18d>;
			};

			gmac1m1-rgmii-bus {
				rockchip,pins = <0x04 0x01 0x03 0xb0 0x04 0x02 0x03 0xb0 0x03 0x1e 0x03 0xb3 0x03 0x1f 0x03 0xb3>;
				phandle = <0x18e>;
			};
		};

		gpu {

			gpu-pins {
				rockchip,pins = <0x00 0x10 0x02 0xb0 0x00 0x06 0x04 0xb0>;
				phandle = <0x18f>;
			};
		};

		hdmitx {

			hdmitxm0-cec {
				rockchip,pins = <0x04 0x19 0x01 0xb0>;
				phandle = <0x55>;
			};

			hdmitxm1-cec {
				rockchip,pins = <0x00 0x17 0x01 0xb0>;
				phandle = <0x190>;
			};

			hdmitx-scl {
				rockchip,pins = <0x04 0x17 0x01 0xb0>;
				phandle = <0x53>;
			};

			hdmitx-sda {
				rockchip,pins = <0x04 0x18 0x01 0xb0>;
				phandle = <0x54>;
			};
		};

		i2c0 {

			i2c0-xfer {
				rockchip,pins = <0x00 0x09 0x01 0xb5 0x00 0x0a 0x01 0xb5>;
				phandle = <0x1e>;
			};
		};

		i2c1 {

			i2c1-xfer {
				rockchip,pins = <0x00 0x0b 0x01 0xb5 0x00 0x0c 0x01 0xb5>;
				phandle = <0x75>;
			};
		};

		i2c2 {

			i2c2m0-xfer {
				rockchip,pins = <0x00 0x0d 0x01 0xb5 0x00 0x0e 0x01 0xb5>;
				phandle = <0x76>;
			};

			i2c2m1-xfer {
				rockchip,pins = <0x04 0x0d 0x01 0xb5 0x04 0x0c 0x01 0xb5>;
				phandle = <0x191>;
			};
		};

		i2c3 {

			i2c3m0-xfer {
				rockchip,pins = <0x01 0x01 0x01 0xb5 0x01 0x00 0x01 0xb5>;
				phandle = <0x77>;
			};

			i2c3m1-xfer {
				rockchip,pins = <0x03 0x0d 0x04 0xb5 0x03 0x0e 0x04 0xb5>;
				phandle = <0x192>;
			};
		};

		i2c4 {

			i2c4m0-xfer {
				rockchip,pins = <0x04 0x0b 0x01 0xb5 0x04 0x0a 0x01 0xb5>;
				phandle = <0x78>;
			};

			i2c4m1-xfer {
				rockchip,pins = <0x02 0x0a 0x02 0xb5 0x02 0x09 0x02 0xb5>;
				phandle = <0x193>;
			};
		};

		i2c5 {

			i2c5m0-xfer {
				rockchip,pins = <0x03 0x0b 0x04 0xb5 0x03 0x0c 0x04 0xb5>;
				phandle = <0x79>;
			};

			i2c5m1-xfer {
				rockchip,pins = <0x04 0x17 0x02 0xb5 0x04 0x18 0x02 0xb5>;
				phandle = <0x194>;
			};
		};

		i2s1 {

			i2s1m0-lrckrx {
				rockchip,pins = <0x01 0x06 0x01 0xb0>;
				phandle = <0x195>;
			};

			i2s1m0-lrcktx {
				rockchip,pins = <0x01 0x05 0x01 0xb0>;
				phandle = <0x196>;
			};

			i2s1m0-mclk {
				rockchip,pins = <0x01 0x02 0x01 0xb0>;
				phandle = <0x197>;
			};

			i2s1m0-sclkrx {
				rockchip,pins = <0x01 0x04 0x01 0xb0>;
				phandle = <0x198>;
			};

			i2s1m0-sclktx {
				rockchip,pins = <0x01 0x03 0x01 0xb0>;
				phandle = <0x199>;
			};

			i2s1m0-sdi0 {
				rockchip,pins = <0x01 0x0b 0x01 0xb0>;
				phandle = <0x19a>;
			};

			i2s1m0-sdi1 {
				rockchip,pins = <0x01 0x0a 0x02 0xb0>;
				phandle = <0x19b>;
			};

			i2s1m0-sdi2 {
				rockchip,pins = <0x01 0x09 0x02 0xb0>;
				phandle = <0x19c>;
			};

			i2s1m0-sdi3 {
				rockchip,pins = <0x01 0x08 0x02 0xb0>;
				phandle = <0x19d>;
			};

			i2s1m0-sdo0 {
				rockchip,pins = <0x01 0x07 0x01 0xb0>;
				phandle = <0x19e>;
			};

			i2s1m0-sdo1 {
				rockchip,pins = <0x01 0x08 0x01 0xb0>;
				phandle = <0x19f>;
			};

			i2s1m0-sdo2 {
				rockchip,pins = <0x01 0x09 0x01 0xb0>;
				phandle = <0x1a0>;
			};

			i2s1m0-sdo3 {
				rockchip,pins = <0x01 0x0a 0x01 0xb0>;
				phandle = <0x1a1>;
			};

			i2s1m1-lrckrx {
				rockchip,pins = <0x04 0x07 0x05 0xb0>;
				phandle = <0x66>;
			};

			i2s1m1-lrcktx {
				rockchip,pins = <0x03 0x18 0x04 0xb0>;
				phandle = <0x65>;
			};

			i2s1m1-mclk {
				rockchip,pins = <0x03 0x16 0x04 0xb0>;
				phandle = <0x1a2>;
			};

			i2s1m1-sclkrx {
				rockchip,pins = <0x04 0x06 0x05 0xb0>;
				phandle = <0x64>;
			};

			i2s1m1-sclktx {
				rockchip,pins = <0x03 0x17 0x04 0xb0>;
				phandle = <0x63>;
			};

			i2s1m1-sdi0 {
				rockchip,pins = <0x03 0x1a 0x04 0xb0>;
				phandle = <0x67>;
			};

			i2s1m1-sdi1 {
				rockchip,pins = <0x03 0x1b 0x04 0xb0>;
				phandle = <0x68>;
			};

			i2s1m1-sdi2 {
				rockchip,pins = <0x03 0x1c 0x04 0xb0>;
				phandle = <0x69>;
			};

			i2s1m1-sdi3 {
				rockchip,pins = <0x03 0x1d 0x04 0xb0>;
				phandle = <0x6a>;
			};

			i2s1m1-sdo0 {
				rockchip,pins = <0x03 0x19 0x04 0xb0>;
				phandle = <0x6b>;
			};

			i2s1m1-sdo1 {
				rockchip,pins = <0x04 0x08 0x05 0xb0>;
				phandle = <0x6c>;
			};

			i2s1m1-sdo2 {
				rockchip,pins = <0x04 0x09 0x04 0xb0>;
				phandle = <0x6d>;
			};

			i2s1m1-sdo3 {
				rockchip,pins = <0x04 0x0d 0x04 0xb0>;
				phandle = <0x6e>;
			};

			i2s1m2-lrckrx {
				rockchip,pins = <0x03 0x15 0x05 0xb0>;
				phandle = <0x1a3>;
			};

			i2s1m2-lrcktx {
				rockchip,pins = <0x02 0x1a 0x05 0xb0>;
				phandle = <0x1a4>;
			};

			i2s1m2-mclk {
				rockchip,pins = <0x02 0x18 0x05 0xb0>;
				phandle = <0x1a5>;
			};

			i2s1m2-sclkrx {
				rockchip,pins = <0x03 0x13 0x05 0xb0>;
				phandle = <0x1a6>;
			};

			i2s1m2-sclktx {
				rockchip,pins = <0x02 0x19 0x05 0xb0>;
				phandle = <0x1a7>;
			};

			i2s1m2-sdi0 {
				rockchip,pins = <0x02 0x1b 0x05 0xb0>;
				phandle = <0x1a8>;
			};

			i2s1m2-sdi1 {
				rockchip,pins = <0x02 0x1c 0x05 0xb0>;
				phandle = <0x1a9>;
			};

			i2s1m2-sdi2 {
				rockchip,pins = <0x02 0x1d 0x05 0xb0>;
				phandle = <0x1aa>;
			};

			i2s1m2-sdi3 {
				rockchip,pins = <0x02 0x1e 0x05 0xb0>;
				phandle = <0x1ab>;
			};

			i2s1m2-sdo0 {
				rockchip,pins = <0x02 0x1f 0x05 0xb0>;
				phandle = <0x1ac>;
			};

			i2s1m2-sdo1 {
				rockchip,pins = <0x03 0x00 0x05 0xb0>;
				phandle = <0x1ad>;
			};

			i2s1m2-sdo2 {
				rockchip,pins = <0x03 0x11 0x05 0xb0>;
				phandle = <0x1ae>;
			};

			i2s1m2-sdo3 {
				rockchip,pins = <0x03 0x12 0x05 0xb0>;
				phandle = <0x1af>;
			};
		};

		i2s2 {

			i2s2m0-lrckrx {
				rockchip,pins = <0x02 0x10 0x01 0xb0>;
				phandle = <0x1b0>;
			};

			i2s2m0-lrcktx {
				rockchip,pins = <0x02 0x13 0x01 0xb0>;
				phandle = <0x1b1>;
			};

			i2s2m0-mclk {
				rockchip,pins = <0x02 0x11 0x01 0xb0>;
				phandle = <0x1b2>;
			};

			i2s2m0-sclkrx {
				rockchip,pins = <0x02 0x0f 0x01 0xb0>;
				phandle = <0x1b3>;
			};

			i2s2m0-sclktx {
				rockchip,pins = <0x02 0x12 0x01 0xb0>;
				phandle = <0x1b4>;
			};

			i2s2m0-sdi {
				rockchip,pins = <0x02 0x15 0x01 0xb0>;
				phandle = <0x1b5>;
			};

			i2s2m0-sdo {
				rockchip,pins = <0x02 0x14 0x01 0xb0>;
				phandle = <0x1b6>;
			};

			i2s2m1-lrckrx {
				rockchip,pins = <0x04 0x05 0x05 0xb0>;
				phandle = <0x1b7>;
			};

			i2s2m1-lrcktx {
				rockchip,pins = <0x04 0x04 0x05 0xb0>;
				phandle = <0x1b8>;
			};

			i2s2m1-mclk {
				rockchip,pins = <0x04 0x0e 0x05 0xb0>;
				phandle = <0x1b9>;
			};

			i2s2m1-sclkrx {
				rockchip,pins = <0x04 0x11 0x05 0xb0>;
				phandle = <0x1ba>;
			};

			i2s2m1-sclktx {
				rockchip,pins = <0x04 0x0f 0x04 0xb0>;
				phandle = <0x1bb>;
			};

			i2s2m1-sdi {
				rockchip,pins = <0x04 0x0a 0x05 0xb0>;
				phandle = <0x1bc>;
			};

			i2s2m1-sdo {
				rockchip,pins = <0x04 0x0b 0x05 0xb0>;
				phandle = <0x1bd>;
			};
		};

		i2s3 {

			i2s3m0-lrck {
				rockchip,pins = <0x03 0x04 0x04 0xb0>;
				phandle = <0x1be>;
			};

			i2s3m0-mclk {
				rockchip,pins = <0x03 0x02 0x04 0xb0>;
				phandle = <0x1bf>;
			};

			i2s3m0-sclk {
				rockchip,pins = <0x03 0x03 0x04 0xb0>;
				phandle = <0x1c0>;
			};

			i2s3m0-sdi {
				rockchip,pins = <0x03 0x06 0x04 0xb0>;
				phandle = <0x1c1>;
			};

			i2s3m0-sdo {
				rockchip,pins = <0x03 0x05 0x04 0xb0>;
				phandle = <0x1c2>;
			};

			i2s3m1-lrck {
				rockchip,pins = <0x04 0x14 0x05 0xb0>;
				phandle = <0x1c3>;
			};

			i2s3m1-mclk {
				rockchip,pins = <0x04 0x12 0x05 0xb0>;
				phandle = <0x1c4>;
			};

			i2s3m1-sclk {
				rockchip,pins = <0x04 0x13 0x05 0xb0>;
				phandle = <0x1c5>;
			};

			i2s3m1-sdi {
				rockchip,pins = <0x04 0x16 0x05 0xb0>;
				phandle = <0x1c6>;
			};

			i2s3m1-sdo {
				rockchip,pins = <0x04 0x15 0x05 0xb0>;
				phandle = <0x1c7>;
			};
		};

		isp {

			isp-pins {
				rockchip,pins = <0x04 0x0c 0x04 0xb0 0x04 0x06 0x01 0xb0 0x04 0x09 0x01 0xb0>;
				phandle = <0x1c8>;
			};
		};

		jtag {

			jtag-pins {
				rockchip,pins = <0x01 0x1f 0x02 0xb0 0x02 0x00 0x02 0xb0>;
				phandle = <0x1c9>;
			};
		};

		lcdc {

			lcdc-ctl {
				rockchip,pins = <0x03 0x00 0x01 0xb0 0x02 0x18 0x01 0xb0 0x02 0x19 0x01 0xb0 0x02 0x1a 0x01 0xb0 0x02 0x1b 0x01 0xb0 0x02 0x1c 0x01 0xb0 0x02 0x1d 0x01 0xb0 0x02 0x1e 0x01 0xb0 0x02 0x1f 0x01 0xb0 0x03 0x01 0x01 0xb0 0x03 0x02 0x01 0xb0 0x03 0x03 0x01 0xb0 0x03 0x04 0x01 0xb0 0x03 0x05 0x01 0xb0 0x03 0x06 0x01 0xb0 0x03 0x07 0x01 0xb0 0x03 0x08 0x01 0xb0 0x03 0x09 0x01 0xb0 0x03 0x0a 0x01 0xb0 0x03 0x0b 0x01 0xb0 0x03 0x0c 0x01 0xb0 0x03 0x0d 0x01 0xb0 0x03 0x0e 0x01 0xb0 0x03 0x0f 0x01 0xb0 0x03 0x10 0x01 0xb0 0x03 0x13 0x01 0xb0 0x03 0x11 0x01 0xb0 0x03 0x12 0x01 0xb0>;
				phandle = <0x1ca>;
			};
		};

		mcu {

			mcu-pins {
				rockchip,pins = <0x00 0x0c 0x04 0xb0 0x00 0x11 0x04 0xb0 0x00 0x0b 0x04 0xb0 0x00 0x12 0x04 0xb0 0x00 0x13 0x04 0xb0>;
				phandle = <0x1cb>;
			};
		};

		npu {

			npu-pins {
				rockchip,pins = <0x00 0x11 0x02 0xb0>;
				phandle = <0x1cc>;
			};
		};

		pcie20 {

			pcie20m0-pins {
				rockchip,pins = <0x00 0x05 0x03 0xb0 0x00 0x0e 0x03 0xb0 0x00 0x0d 0x03 0xb0>;
				phandle = <0x1cd>;
			};

			pcie20m1-pins {
				rockchip,pins = <0x02 0x18 0x04 0xb0 0x03 0x11 0x04 0xb0 0x02 0x19 0x04 0xb0>;
				phandle = <0x1ce>;
			};

			pcie20m2-pins {
				rockchip,pins = <0x01 0x08 0x04 0xb0 0x01 0x0a 0x04 0xb0 0x01 0x09 0x04 0xb0>;
				phandle = <0x1cf>;
			};

			pcie20-buttonrstn {
				rockchip,pins = <0x00 0x0c 0x03 0xb0>;
				phandle = <0x1d0>;
			};
		};

		pcie30x1 {

			pcie30x1m0-pins {
				rockchip,pins = <0x00 0x04 0x03 0xb0 0x00 0x13 0x03 0xb0 0x00 0x12 0x03 0xb0>;
				phandle = <0x1d1>;
			};

			pcie30x1m1-pins {
				rockchip,pins = <0x02 0x1a 0x04 0xb0 0x03 0x01 0x04 0xb0 0x02 0x1b 0x04 0xb0>;
				phandle = <0x1d2>;
			};

			pcie30x1m2-pins {
				rockchip,pins = <0x01 0x05 0x04 0xb0 0x01 0x02 0x04 0xb0 0x01 0x03 0x04 0xb0>;
				phandle = <0x1d3>;
			};

			pcie30x1-buttonrstn {
				rockchip,pins = <0x00 0x0b 0x03 0xb0>;
				phandle = <0x1d4>;
			};
		};

		pcie30x2 {

			pcie30x2m0-pins {
				rockchip,pins = <0x00 0x06 0x02 0xb0 0x00 0x16 0x03 0xb0 0x00 0x15 0x03 0xb0>;
				phandle = <0x1d5>;
			};

			pcie30x2m1-pins {
				rockchip,pins = <0x02 0x1c 0x04 0xb0 0x02 0x1e 0x04 0xb0 0x02 0x1d 0x04 0xb0>;
				phandle = <0x1d6>;
			};

			pcie30x2m2-pins {
				rockchip,pins = <0x04 0x12 0x04 0xb0 0x04 0x14 0x04 0xb0 0x04 0x13 0x04 0xb0>;
				phandle = <0x1d7>;
			};

			pcie30x2-buttonrstn {
				rockchip,pins = <0x00 0x08 0x03 0xb0>;
				phandle = <0x1d8>;
			};
		};

		pdm {

			pdmm0-clk {
				rockchip,pins = <0x01 0x06 0x03 0xb0>;
				phandle = <0x6f>;
			};

			pdmm0-clk1 {
				rockchip,pins = <0x01 0x04 0x03 0xb0>;
				phandle = <0x70>;
			};

			pdmm0-sdi0 {
				rockchip,pins = <0x01 0x0b 0x02 0xb0>;
				phandle = <0x71>;
			};

			pdmm0-sdi1 {
				rockchip,pins = <0x01 0x0a 0x03 0xb0>;
				phandle = <0x72>;
			};

			pdmm0-sdi2 {
				rockchip,pins = <0x01 0x09 0x03 0xb0>;
				phandle = <0x73>;
			};

			pdmm0-sdi3 {
				rockchip,pins = <0x01 0x08 0x03 0xb0>;
				phandle = <0x74>;
			};

			pdmm1-clk {
				rockchip,pins = <0x03 0x1e 0x05 0xb0>;
				phandle = <0x1d9>;
			};

			pdmm1-clk1 {
				rockchip,pins = <0x04 0x00 0x04 0xb0>;
				phandle = <0x1da>;
			};

			pdmm1-sdi0 {
				rockchip,pins = <0x03 0x1f 0x05 0xb0>;
				phandle = <0x1db>;
			};

			pdmm1-sdi1 {
				rockchip,pins = <0x04 0x01 0x04 0xb0>;
				phandle = <0x1dc>;
			};

			pdmm1-sdi2 {
				rockchip,pins = <0x04 0x02 0x05 0xb0>;
				phandle = <0x1dd>;
			};

			pdmm1-sdi3 {
				rockchip,pins = <0x04 0x03 0x05 0xb0>;
				phandle = <0x1de>;
			};

			pdmm2-clk1 {
				rockchip,pins = <0x03 0x14 0x05 0xb0>;
				phandle = <0x1df>;
			};

			pdmm2-sdi0 {
				rockchip,pins = <0x03 0x0b 0x05 0xb0>;
				phandle = <0x1e0>;
			};

			pdmm2-sdi1 {
				rockchip,pins = <0x03 0x0c 0x05 0xb0>;
				phandle = <0x1e1>;
			};

			pdmm2-sdi2 {
				rockchip,pins = <0x03 0x0f 0x05 0xb0>;
				phandle = <0x1e2>;
			};

			pdmm2-sdi3 {
				rockchip,pins = <0x03 0x10 0x05 0xb0>;
				phandle = <0x1e3>;
			};
		};

		pmic {

			pmic-pins {
				rockchip,pins = <0x00 0x02 0x01 0xb0>;
				phandle = <0x1e4>;
			};

			pmic-int-l {
				rockchip,pins = <0x00 0x03 0x00 0xb2>;
				phandle = <0x21>;
			};
		};

		pmu {

			pmu-pins {
				rockchip,pins = <0x00 0x05 0x04 0xb0 0x00 0x06 0x03 0xb0 0x00 0x14 0x04 0xb0 0x00 0x15 0x04 0xb0 0x00 0x16 0x04 0xb0 0x00 0x17 0x04 0xb0>;
				phandle = <0x1e5>;
			};
		};

		pwm0 {

			pwm0m0-pins {
				rockchip,pins = <0x00 0x0f 0x01 0xb0>;
				phandle = <0x25>;
			};

			pwm0m1-pins {
				rockchip,pins = <0x00 0x17 0x02 0xb0>;
				phandle = <0x1e6>;
			};
		};

		pwm1 {

			pwm1m0-pins {
				rockchip,pins = <0x00 0x10 0x01 0xb0>;
				phandle = <0x26>;
			};

			pwm1m1-pins {
				rockchip,pins = <0x00 0x0d 0x04 0xb0>;
				phandle = <0x1e7>;
			};
		};

		pwm2 {

			pwm2m0-pins {
				rockchip,pins = <0x00 0x11 0x01 0xb0>;
				phandle = <0x27>;
			};

			pwm2m1-pins {
				rockchip,pins = <0x00 0x0e 0x04 0xb0>;
				phandle = <0x1e8>;
			};
		};

		pwm3 {

			pwm3-pins {
				rockchip,pins = <0x00 0x12 0x01 0xb0>;
				phandle = <0x28>;
			};
		};

		pwm4 {

			pwm4-pins {
				rockchip,pins = <0x00 0x13 0x01 0xb0>;
				phandle = <0x9e>;
			};
		};

		pwm5 {

			pwm5-pins {
				rockchip,pins = <0x00 0x14 0x01 0xb0>;
				phandle = <0x9f>;
			};
		};

		pwm6 {

			pwm6-pins {
				rockchip,pins = <0x00 0x15 0x01 0xb0>;
				phandle = <0xa0>;
			};
		};

		pwm7 {

			pwm7-pins {
				rockchip,pins = <0x00 0x16 0x01 0xb0>;
				phandle = <0xa1>;
			};
		};

		pwm8 {

			pwm8m0-pins {
				rockchip,pins = <0x03 0x09 0x05 0xb0>;
				phandle = <0xa2>;
			};

			pwm8m1-pins {
				rockchip,pins = <0x01 0x1d 0x04 0xb0>;
				phandle = <0x1e9>;
			};
		};

		pwm9 {

			pwm9m0-pins {
				rockchip,pins = <0x03 0x0a 0x05 0xb0>;
				phandle = <0xa3>;
			};

			pwm9m1-pins {
				rockchip,pins = <0x01 0x1e 0x04 0xb0>;
				phandle = <0x1ea>;
			};
		};

		pwm10 {

			pwm10m0-pins {
				rockchip,pins = <0x03 0x0d 0x05 0xb0>;
				phandle = <0xa4>;
			};

			pwm10m1-pins {
				rockchip,pins = <0x02 0x01 0x02 0xb0>;
				phandle = <0x1eb>;
			};
		};

		pwm11 {

			pwm11m0-pins {
				rockchip,pins = <0x03 0x0e 0x05 0xb0>;
				phandle = <0xa5>;
			};

			pwm11m1-pins {
				rockchip,pins = <0x04 0x10 0x03 0xb0>;
				phandle = <0x1ec>;
			};
		};

		pwm12 {

			pwm12m0-pins {
				rockchip,pins = <0x03 0x0f 0x02 0xb0>;
				phandle = <0xa6>;
			};

			pwm12m1-pins {
				rockchip,pins = <0x04 0x15 0x01 0xb0>;
				phandle = <0x1ed>;
			};
		};

		pwm13 {

			pwm13m0-pins {
				rockchip,pins = <0x03 0x10 0x02 0xb0>;
				phandle = <0xa7>;
			};

			pwm13m1-pins {
				rockchip,pins = <0x04 0x16 0x01 0xb0>;
				phandle = <0x1ee>;
			};
		};

		pwm14 {

			pwm14m0-pins {
				rockchip,pins = <0x03 0x14 0x01 0xb0>;
				phandle = <0xa8>;
			};

			pwm14m1-pins {
				rockchip,pins = <0x04 0x12 0x01 0xb0>;
				phandle = <0x1ef>;
			};
		};

		pwm15 {

			pwm15m0-pins {
				rockchip,pins = <0x03 0x15 0x01 0xb0>;
				phandle = <0xa9>;
			};

			pwm15m1-pins {
				rockchip,pins = <0x04 0x13 0x01 0xb0>;
				phandle = <0x1f0>;
			};
		};

		refclk {

			refclk-pins {
				rockchip,pins = <0x00 0x00 0x01 0xb0>;
				phandle = <0x1f1>;
			};
		};

		sata {

			sata-pins {
				rockchip,pins = <0x00 0x04 0x02 0xb0 0x00 0x06 0x01 0xb0 0x00 0x05 0x02 0xb0>;
				phandle = <0x1f2>;
			};
		};

		sata0 {

			sata0-pins {
				rockchip,pins = <0x04 0x16 0x03 0xb0>;
				phandle = <0x1f3>;
			};
		};

		sata1 {

			sata1-pins {
				rockchip,pins = <0x04 0x15 0x03 0xb0>;
				phandle = <0x1f4>;
			};
		};

		sata2 {

			sata2-pins {
				rockchip,pins = <0x04 0x14 0x03 0xb0>;
				phandle = <0x1f5>;
			};
		};

		scr {

			scr-pins {
				rockchip,pins = <0x01 0x02 0x03 0xb0 0x01 0x07 0x03 0xb2 0x01 0x03 0x03 0xb2 0x01 0x05 0x03 0xb0>;
				phandle = <0x1f6>;
			};
		};

		sdmmc0 {

			sdmmc0-bus4 {
				rockchip,pins = <0x01 0x1d 0x01 0xb1 0x01 0x1e 0x01 0xb1 0x01 0x1f 0x01 0xb1 0x02 0x00 0x01 0xb1>;
				phandle = <0x58>;
			};

			sdmmc0-clk {
				rockchip,pins = <0x02 0x02 0x01 0xb1>;
				phandle = <0x59>;
			};

			sdmmc0-cmd {
				rockchip,pins = <0x02 0x01 0x01 0xb1>;
				phandle = <0x5a>;
			};

			sdmmc0-det {
				rockchip,pins = <0x00 0x04 0x01 0xb2>;
				phandle = <0x5b>;
			};

			sdmmc0-pwren {
				rockchip,pins = <0x00 0x05 0x01 0xb0>;
				phandle = <0x1f7>;
			};
		};

		sdmmc1 {

			sdmmc1-bus4 {
				rockchip,pins = <0x02 0x03 0x01 0xb1 0x02 0x04 0x01 0xb1 0x02 0x05 0x01 0xb1 0x02 0x06 0x01 0xb1>;
				phandle = <0x5c>;
			};

			sdmmc1-clk {
				rockchip,pins = <0x02 0x08 0x01 0xb1>;
				phandle = <0x5e>;
			};

			sdmmc1-cmd {
				rockchip,pins = <0x02 0x07 0x01 0xb1>;
				phandle = <0x5d>;
			};

			sdmmc1-det {
				rockchip,pins = <0x02 0x0a 0x01 0xb2>;
				phandle = <0x1f8>;
			};

			sdmmc1-pwren {
				rockchip,pins = <0x02 0x09 0x01 0xb0>;
				phandle = <0x1f9>;
			};
		};

		sdmmc2 {

			sdmmc2m0-bus4 {
				rockchip,pins = <0x03 0x16 0x03 0xb1 0x03 0x17 0x03 0xb1 0x03 0x18 0x03 0xb1 0x03 0x19 0x03 0xb1>;
				phandle = <0x1fa>;
			};

			sdmmc2m0-clk {
				rockchip,pins = <0x03 0x1b 0x03 0xb1>;
				phandle = <0x1fb>;
			};

			sdmmc2m0-cmd {
				rockchip,pins = <0x03 0x1a 0x03 0xb1>;
				phandle = <0x1fc>;
			};

			sdmmc2m0-det {
				rockchip,pins = <0x03 0x1c 0x03 0xb2>;
				phandle = <0x1fd>;
			};

			sdmmc2m0-pwren {
				rockchip,pins = <0x03 0x1d 0x03 0xb0>;
				phandle = <0x1fe>;
			};

			sdmmc2m1-bus4 {
				rockchip,pins = <0x03 0x01 0x05 0xb1 0x03 0x02 0x05 0xb1 0x03 0x03 0x05 0xb1 0x03 0x04 0x05 0xb1>;
				phandle = <0x1ff>;
			};

			sdmmc2m1-clk {
				rockchip,pins = <0x03 0x06 0x05 0xb1>;
				phandle = <0x200>;
			};

			sdmmc2m1-cmd {
				rockchip,pins = <0x03 0x05 0x05 0xb1>;
				phandle = <0x201>;
			};

			sdmmc2m1-det {
				rockchip,pins = <0x03 0x07 0x04 0xb2>;
				phandle = <0x202>;
			};

			sdmmc2m1-pwren {
				rockchip,pins = <0x03 0x08 0x04 0xb0>;
				phandle = <0x203>;
			};
		};

		spdif {

			spdifm0-tx {
				rockchip,pins = <0x01 0x04 0x04 0xb0>;
				phandle = <0x62>;
			};

			spdifm1-tx {
				rockchip,pins = <0x03 0x15 0x02 0xb0>;
				phandle = <0x204>;
			};

			spdifm2-tx {
				rockchip,pins = <0x04 0x14 0x02 0xb0>;
				phandle = <0x205>;
			};
		};

		spi0 {

			spi0m0-pins {
				rockchip,pins = <0x00 0x0d 0x02 0xb0 0x00 0x15 0x02 0xb0 0x00 0x0e 0x02 0xb0>;
				phandle = <0x7c>;
			};

			spi0m0-cs0 {
				rockchip,pins = <0x00 0x16 0x02 0xb0>;
				phandle = <0x7a>;
			};

			spi0m0-cs1 {
				rockchip,pins = <0x00 0x14 0x02 0xb0>;
				phandle = <0x7b>;
			};

			spi0m1-pins {
				rockchip,pins = <0x02 0x1b 0x03 0xb0 0x02 0x18 0x03 0xb0 0x02 0x19 0x03 0xb0>;
				phandle = <0x206>;
			};

			spi0m1-cs0 {
				rockchip,pins = <0x02 0x1a 0x03 0xb0>;
				phandle = <0x207>;
			};
		};

		spi1 {

			spi1m0-pins {
				rockchip,pins = <0x02 0x0d 0x03 0xb0 0x02 0x0e 0x03 0xb0 0x02 0x0f 0x04 0xb0>;
				phandle = <0x7f>;
			};

			spi1m0-cs0 {
				rockchip,pins = <0x02 0x10 0x04 0xb0>;
				phandle = <0x7d>;
			};

			spi1m0-cs1 {
				rockchip,pins = <0x02 0x16 0x03 0xb0>;
				phandle = <0x7e>;
			};

			spi1m1-pins {
				rockchip,pins = <0x03 0x13 0x03 0xb0 0x03 0x12 0x03 0xb0 0x03 0x11 0x03 0xb0>;
				phandle = <0x208>;
			};

			spi1m1-cs0 {
				rockchip,pins = <0x03 0x01 0x03 0xb0>;
				phandle = <0x209>;
			};
		};

		spi2 {

			spi2m0-pins {
				rockchip,pins = <0x02 0x11 0x04 0xb0 0x02 0x12 0x04 0xb0 0x02 0x13 0x04 0xb0>;
				phandle = <0x82>;
			};

			spi2m0-cs0 {
				rockchip,pins = <0x02 0x14 0x04 0xb0>;
				phandle = <0x80>;
			};

			spi2m0-cs1 {
				rockchip,pins = <0x02 0x15 0x04 0xb0>;
				phandle = <0x81>;
			};

			spi2m1-pins {
				rockchip,pins = <0x03 0x00 0x03 0xb0 0x02 0x1f 0x03 0xb0 0x02 0x1e 0x03 0xb0>;
				phandle = <0x20a>;
			};

			spi2m1-cs0 {
				rockchip,pins = <0x02 0x1d 0x03 0xb0>;
				phandle = <0x20b>;
			};

			spi2m1-cs1 {
				rockchip,pins = <0x02 0x1c 0x03 0xb0>;
				phandle = <0x20c>;
			};
		};

		spi3 {

			spi3m0-pins {
				rockchip,pins = <0x04 0x0b 0x04 0xb0 0x04 0x08 0x04 0xb0 0x04 0x0a 0x04 0xb0>;
				phandle = <0x85>;
			};

			spi3m0-cs0 {
				rockchip,pins = <0x04 0x06 0x04 0xb0>;
				phandle = <0x83>;
			};

			spi3m0-cs1 {
				rockchip,pins = <0x04 0x07 0x04 0xb0>;
				phandle = <0x84>;
			};

			spi3m1-pins {
				rockchip,pins = <0x04 0x12 0x02 0xb0 0x04 0x15 0x02 0xb0 0x04 0x13 0x02 0xb0>;
				phandle = <0x20d>;
			};

			spi3m1-cs0 {
				rockchip,pins = <0x04 0x16 0x02 0xb0>;
				phandle = <0x20e>;
			};

			spi3m1-cs1 {
				rockchip,pins = <0x04 0x19 0x02 0xb0>;
				phandle = <0x20f>;
			};
		};

		tsadc {

			tsadcm0-shut {
				rockchip,pins = <0x00 0x01 0x01 0xb0>;
				phandle = <0x210>;
			};

			tsadcm1-shut {
				rockchip,pins = <0x00 0x02 0x02 0xb0>;
				phandle = <0x211>;
			};

			tsadc-shutorg {
				rockchip,pins = <0x00 0x01 0x02 0xb0>;
				phandle = <0x9c>;
			};

			tsadc-pin {
				rockchip,pins = <0x00 0x01 0x00 0xb0>;
				phandle = <0x9b>;
			};
		};

		uart0 {

			uart0-xfer {
				rockchip,pins = <0x00 0x10 0x03 0xb2 0x00 0x11 0x03 0xb2>;
				phandle = <0x24>;
			};

			uart0-ctsn {
				rockchip,pins = <0x00 0x17 0x03 0xb0>;
				phandle = <0x212>;
			};

			uart0-rtsn {
				rockchip,pins = <0x00 0x14 0x03 0xb0>;
				phandle = <0x213>;
			};
		};

		uart1 {

			uart1m0-xfer {
				rockchip,pins = <0x02 0x0b 0x02 0xb2 0x02 0x0c 0x02 0xb2>;
				phandle = <0x86>;
			};

			uart1m0-ctsn {
				rockchip,pins = <0x02 0x0e 0x02 0xb0>;
				phandle = <0x87>;
			};

			uart1m0-rtsn {
				rockchip,pins = <0x02 0x0d 0x02 0xb0>;
				phandle = <0x88>;
			};

			uart1m1-xfer {
				rockchip,pins = <0x03 0x1f 0x04 0xb2 0x03 0x1e 0x04 0xb2>;
				phandle = <0x214>;
			};

			uart1m1-ctsn {
				rockchip,pins = <0x04 0x11 0x04 0xb0>;
				phandle = <0x215>;
			};

			uart1m1-rtsn {
				rockchip,pins = <0x04 0x0e 0x04 0xb0>;
				phandle = <0x216>;
			};
		};

		uart2 {

			uart2m0-xfer {
				rockchip,pins = <0x00 0x18 0x01 0xb2 0x00 0x19 0x01 0xb2>;
				phandle = <0x8f>;
			};

			uart2m1-xfer {
				rockchip,pins = <0x01 0x1e 0x02 0xb2 0x01 0x1d 0x02 0xb2>;
				phandle = <0x217>;
			};
		};

		uart3 {

			uart3m0-xfer {
				rockchip,pins = <0x01 0x00 0x02 0xb2 0x01 0x01 0x02 0xb2>;
				phandle = <0x90>;
			};

			uart3m0-ctsn {
				rockchip,pins = <0x01 0x03 0x02 0xb0>;
				phandle = <0x218>;
			};

			uart3m0-rtsn {
				rockchip,pins = <0x01 0x02 0x02 0xb0>;
				phandle = <0x219>;
			};

			uart3m1-xfer {
				rockchip,pins = <0x03 0x10 0x04 0xb2 0x03 0x0f 0x04 0xb2>;
				phandle = <0x21a>;
			};
		};

		uart4 {

			uart4m0-xfer {
				rockchip,pins = <0x01 0x04 0x02 0xb2 0x01 0x06 0x02 0xb2>;
				phandle = <0x91>;
			};

			uart4m0-ctsn {
				rockchip,pins = <0x01 0x07 0x02 0xb0>;
				phandle = <0x21b>;
			};

			uart4m0-rtsn {
				rockchip,pins = <0x01 0x05 0x02 0xb0>;
				phandle = <0x21c>;
			};

			uart4m1-xfer {
				rockchip,pins = <0x03 0x09 0x04 0xb2 0x03 0x0a 0x04 0xb2>;
				phandle = <0x21d>;
			};
		};

		uart5 {

			uart5m0-xfer {
				rockchip,pins = <0x02 0x01 0x03 0xb2 0x02 0x02 0x03 0xb2>;
				phandle = <0x92>;
			};

			uart5m0-ctsn {
				rockchip,pins = <0x01 0x1f 0x03 0xb0>;
				phandle = <0x21e>;
			};

			uart5m0-rtsn {
				rockchip,pins = <0x02 0x00 0x03 0xb0>;
				phandle = <0x21f>;
			};

			uart5m1-xfer {
				rockchip,pins = <0x03 0x13 0x04 0xb2 0x03 0x12 0x04 0xb2>;
				phandle = <0x220>;
			};
		};

		uart6 {

			uart6m0-xfer {
				rockchip,pins = <0x02 0x03 0x03 0xb2 0x02 0x04 0x03 0xb2>;
				phandle = <0x93>;
			};

			uart6m0-ctsn {
				rockchip,pins = <0x02 0x10 0x03 0xb0>;
				phandle = <0x221>;
			};

			uart6m0-rtsn {
				rockchip,pins = <0x02 0x0f 0x03 0xb0>;
				phandle = <0x222>;
			};

			uart6m1-xfer {
				rockchip,pins = <0x01 0x1e 0x03 0xb2 0x01 0x1d 0x03 0xb2>;
				phandle = <0x223>;
			};
		};

		uart7 {

			uart7m0-xfer {
				rockchip,pins = <0x02 0x05 0x03 0xb2 0x02 0x06 0x03 0xb2>;
				phandle = <0x94>;
			};

			uart7m0-ctsn {
				rockchip,pins = <0x02 0x12 0x03 0xb0>;
				phandle = <0x224>;
			};

			uart7m0-rtsn {
				rockchip,pins = <0x02 0x11 0x03 0xb0>;
				phandle = <0x225>;
			};

			uart7m1-xfer {
				rockchip,pins = <0x03 0x15 0x04 0xb2 0x03 0x14 0x04 0xb2>;
				phandle = <0x226>;
			};

			uart7m2-xfer {
				rockchip,pins = <0x04 0x03 0x04 0xb2 0x04 0x02 0x04 0xb2>;
				phandle = <0x227>;
			};
		};

		uart8 {

			uart8m0-xfer {
				rockchip,pins = <0x02 0x16 0x02 0xb2 0x02 0x15 0x03 0xb2>;
				phandle = <0x95>;
			};

			uart8m0-ctsn {
				rockchip,pins = <0x02 0x0a 0x03 0xb0>;
				phandle = <0x228>;
			};

			uart8m0-rtsn {
				rockchip,pins = <0x02 0x09 0x03 0xb0>;
				phandle = <0x229>;
			};

			uart8m1-xfer {
				rockchip,pins = <0x03 0x00 0x04 0xb2 0x02 0x1f 0x04 0xb2>;
				phandle = <0x22a>;
			};
		};

		uart9 {

			uart9m0-xfer {
				rockchip,pins = <0x02 0x07 0x03 0xb2 0x02 0x08 0x03 0xb2>;
				phandle = <0x96>;
			};

			uart9m0-ctsn {
				rockchip,pins = <0x02 0x14 0x03 0xb0>;
				phandle = <0x22b>;
			};

			uart9m0-rtsn {
				rockchip,pins = <0x02 0x13 0x03 0xb0>;
				phandle = <0x22c>;
			};

			uart9m1-xfer {
				rockchip,pins = <0x04 0x16 0x04 0xb2 0x04 0x15 0x04 0xb2>;
				phandle = <0x22d>;
			};

			uart9m2-xfer {
				rockchip,pins = <0x04 0x05 0x04 0xb2 0x04 0x04 0x04 0xb2>;
				phandle = <0x22e>;
			};
		};

		vop {

			vopm0-pins {
				rockchip,pins = <0x00 0x13 0x02 0xb0>;
				phandle = <0x22f>;
			};

			vopm1-pins {
				rockchip,pins = <0x03 0x14 0x02 0xb0>;
				phandle = <0x230>;
			};
		};

		spi0-hs {

			spi0m0-pins {
				rockchip,pins = <0x00 0x0d 0x02 0xb6 0x00 0x15 0x02 0xb6 0x00 0x0e 0x02 0xb6>;
				phandle = <0x231>;
			};

			spi0m0-cs0 {
				rockchip,pins = <0x00 0x16 0x02 0xb6>;
				phandle = <0x232>;
			};

			spi0m0-cs1 {
				rockchip,pins = <0x00 0x14 0x02 0xb6>;
				phandle = <0x233>;
			};

			spi0m1-pins {
				rockchip,pins = <0x02 0x1b 0x03 0xb6 0x02 0x18 0x03 0xb6 0x02 0x19 0x03 0xb6>;
				phandle = <0x234>;
			};

			spi0m1-cs0 {
				rockchip,pins = <0x02 0x1a 0x03 0xb6>;
				phandle = <0x235>;
			};
		};

		spi1-hs {

			spi1m0-pins {
				rockchip,pins = <0x02 0x0d 0x03 0xb6 0x02 0x0e 0x03 0xb6 0x02 0x0f 0x04 0xb6>;
				phandle = <0x236>;
			};

			spi1m0-cs0 {
				rockchip,pins = <0x02 0x10 0x04 0xb6>;
				phandle = <0x237>;
			};

			spi1m0-cs1 {
				rockchip,pins = <0x02 0x16 0x03 0xb6>;
				phandle = <0x238>;
			};

			spi1m1-pins {
				rockchip,pins = <0x03 0x13 0x03 0xb6 0x03 0x12 0x03 0xb6 0x03 0x11 0x03 0xb6>;
				phandle = <0x239>;
			};

			spi1m1-cs0 {
				rockchip,pins = <0x03 0x01 0x03 0xb6>;
				phandle = <0x23a>;
			};
		};

		spi2-hs {

			spi2m0-pins {
				rockchip,pins = <0x02 0x11 0x04 0xb6 0x02 0x12 0x04 0xb6 0x02 0x13 0x04 0xb6>;
				phandle = <0x23b>;
			};

			spi2m0-cs0 {
				rockchip,pins = <0x02 0x14 0x04 0xb6>;
				phandle = <0x23c>;
			};

			spi2m0-cs1 {
				rockchip,pins = <0x02 0x15 0x04 0xb6>;
				phandle = <0x23d>;
			};

			spi2m1-pins {
				rockchip,pins = <0x03 0x00 0x03 0xb6 0x02 0x1f 0x03 0xb6 0x02 0x1e 0x03 0xb6>;
				phandle = <0x23e>;
			};

			spi2m1-cs0 {
				rockchip,pins = <0x02 0x1d 0x03 0xb6>;
				phandle = <0x23f>;
			};

			spi2m1-cs1 {
				rockchip,pins = <0x02 0x1c 0x03 0xb6>;
				phandle = <0x240>;
			};
		};

		spi3-hs {

			spi3m0-pins {
				rockchip,pins = <0x04 0x0b 0x04 0xb6 0x04 0x08 0x04 0xb6 0x04 0x0a 0x04 0xb6>;
				phandle = <0x241>;
			};

			spi3m0-cs0 {
				rockchip,pins = <0x04 0x06 0x04 0xb6>;
				phandle = <0x242>;
			};

			spi3m0-cs1 {
				rockchip,pins = <0x04 0x07 0x04 0xb6>;
				phandle = <0x243>;
			};

			spi3m1-pins {
				rockchip,pins = <0x04 0x12 0x02 0xb6 0x04 0x15 0x02 0xb6 0x04 0x13 0x02 0xb6>;
				phandle = <0x244>;
			};

			spi3m1-cs0 {
				rockchip,pins = <0x04 0x16 0x02 0xb6>;
				phandle = <0x245>;
			};

			spi3m1-cs1 {
				rockchip,pins = <0x04 0x19 0x02 0xb6>;
				phandle = <0x246>;
			};
		};

		gmac-txd-level3 {

			gmac0-tx-bus2-level3 {
				rockchip,pins = <0x02 0x0b 0x01 0xb7 0x02 0x0c 0x01 0xb7 0x02 0x0d 0x01 0xb0>;
				phandle = <0x247>;
			};

			gmac0-rgmii-bus-level3 {
				rockchip,pins = <0x02 0x03 0x02 0xb0 0x02 0x04 0x02 0xb0 0x02 0x06 0x02 0xb7 0x02 0x07 0x02 0xb7>;
				phandle = <0x248>;
			};

			gmac1m0-tx-bus2-level3 {
				rockchip,pins = <0x03 0x0d 0x03 0xb7 0x03 0x0e 0x03 0xb7 0x03 0x0f 0x03 0xb0>;
				phandle = <0x249>;
			};

			gmac1m0-rgmii-bus-level3 {
				rockchip,pins = <0x03 0x04 0x03 0xb0 0x03 0x05 0x03 0xb0 0x03 0x02 0x03 0xb7 0x03 0x03 0x03 0xb7>;
				phandle = <0x24a>;
			};

			gmac1m1-tx-bus2-level3 {
				rockchip,pins = <0x04 0x04 0x03 0xb7 0x04 0x05 0x03 0xb7 0x04 0x06 0x03 0xb0>;
				phandle = <0x24b>;
			};

			gmac1m1-rgmii-bus-level3 {
				rockchip,pins = <0x04 0x01 0x03 0xb0 0x04 0x02 0x03 0xb0 0x03 0x1e 0x03 0xb7 0x03 0x1f 0x03 0xb7>;
				phandle = <0x24c>;
			};
		};

		gmac-txc-level2 {

			gmac0-rgmii-clk-level2 {
				rockchip,pins = <0x02 0x05 0x02 0xb0 0x02 0x08 0x02 0xb3>;
				phandle = <0x24d>;
			};

			gmac1m0-rgmii-clk-level2 {
				rockchip,pins = <0x03 0x07 0x03 0xb0 0x03 0x06 0x03 0xb3>;
				phandle = <0x24e>;
			};

			gmac1m1-rgmii-clk-level2 {
				rockchip,pins = <0x04 0x03 0x03 0xb0 0x04 0x00 0x03 0xb3>;
				phandle = <0x24f>;
			};
		};

		sdio-pwrseq {

			wifi-enable-h {
				rockchip,pins = <0x02 0x09 0x00 0xb0>;
				phandle = <0xbe>;
			};
		};

		wireless-wlan {

			wifi-host-wake-irq {
				rockchip,pins = <0x02 0x0a 0x00 0xb8>;
				phandle = <0x250>;
			};
		};

		bt {

			bt-enable-h {
				rockchip,pins = <0x02 0x0f 0x00 0xb0>;
				phandle = <0x8d>;
			};

			bt-host-wake-l {
				rockchip,pins = <0x02 0x10 0x00 0xb0>;
				phandle = <0x8b>;
			};

			bt-wake-l {
				rockchip,pins = <0x02 0x11 0x00 0xb0>;
				phandle = <0x8c>;
			};
		};

		leds {

			led-pwr-enable-h {
				rockchip,pins = <0x00 0x1c 0x00 0xb0>;
				phandle = <0xb9>;
			};

			led-wifi-enable-h {
				rockchip,pins = <0x00 0x1e 0x00 0xb0>;
				phandle = <0xba>;
			};

			led-eth-enable-h {
				rockchip,pins = <0x00 0x1d 0x00 0xb0>;
				phandle = <0xbb>;
			};

			led-status-enable-h {
				rockchip,pins = <0x00 0x1b 0x00 0xb0>;
				phandle = <0xbc>;
			};
		};
	};

	chosen {
		stdout-path = "serial2:1500000n8";
		phandle = <0x251>;
	};

	external-gmac1-clock {
		compatible = "fixed-clock";
		clock-frequency = <0x7735940>;
		clock-output-names = "gmac1_clkin";
		#clock-cells = <0x00>;
		phandle = <0x47>;
	};

	leds {
		compatible = "gpio-leds";

		led-pwr {
			label = "led-pwr";
			default-state = "on";
			gpios = <0x20 0x1c 0x00>;
			pinctrl-names = "default";
			pinctrl-0 = <0xb9>;
			retain-state-suspended;
			status = "okay";
			phandle = <0x252>;
		};

		led-wifi {
			label = "led-wifi";
			default-state = "off";
			gpios = <0x20 0x1e 0x00>;
			pinctrl-names = "default";
			pinctrl-0 = <0xba>;
			retain-state-suspended;
			status = "okay";
			phandle = <0x253>;
		};

		led-eth {
			label = "led-eth";
			default-state = "off";
			gpios = <0x20 0x1d 0x00>;
			pinctrl-names = "default";
			pinctrl-0 = <0xbb>;
			retain-state-suspended;
			status = "okay";
			phandle = <0x254>;
		};

		led-status {
			label = "led-status";
			default-state = "on";
			gpios = <0x20 0x1b 0x00>;
			linux,default-trigger = "heartbeat";
			pinctrl-names = "default";
			pinctrl-0 = <0xbc>;
			retain-state-suspended;
			status = "okay";
			phandle = <0x255>;
		};
	};

	vbus-regulator {
		compatible = "regulator-fixed";
		regulator-name = "vbus";
		regulator-always-on;
		regulator-boot-on;
		regulator-min-microvolt = <0x4c4b40>;
		regulator-max-microvolt = <0x4c4b40>;
		phandle = <0xbd>;
	};

	vcc5v0-sys-regulator {
		compatible = "regulator-fixed";
		regulator-name = "vcc5v0_sys";
		regulator-always-on;
		regulator-boot-on;
		regulator-min-microvolt = <0x4c4b40>;
		regulator-max-microvolt = <0x4c4b40>;
		vin-supply = <0xbd>;
		phandle = <0x1f>;
	};

	vcc3v3-sys-regulator {
		compatible = "regulator-fixed";
		regulator-name = "vcc3v3_sys";
		regulator-always-on;
		regulator-boot-on;
		regulator-min-microvolt = <0x325aa0>;
		regulator-max-microvolt = <0x325aa0>;
		vin-supply = <0x1f>;
		phandle = <0x22>;
	};

	sdio-pwrseq {
		compatible = "mmc-pwrseq-simple";
		clocks = <0x89 0x01>;
		clock-names = "ext_clock";
		pinctrl-names = "default";
		pinctrl-0 = <0xbe>;
		reset-gpios = <0x8a 0x09 0x01>;
		post-power-on-delay-ms = <0x64>;
		phandle = <0x5f>;
	};

	__symbols__ {
		reserved_memory = "/reserved-memory";
		rknpu_reserved = "/reserved-memory/rknpu";
		ramoops = "/reserved-memory/ramoops@110000";
		cpu0 = "/cpus/cpu@0";
		cpu1 = "/cpus/cpu@100";
		cpu2 = "/cpus/cpu@200";
		cpu3 = "/cpus/cpu@300";
		cpu0_opp_table = "/opp-table-0";
		display_subsystem = "/display-subsystem";
		scmi = "/firmware/scmi";
		scmi_clk = "/firmware/scmi/protocol@14";
		gpu_opp_table = "/opp-table-1";
		hdmi_sound = "/hdmi-sound";
		xin24m = "/xin24m";
		xin32k = "/xin32k";
		scmi_shmem = "/sram@10f000/sram@0";
		sata1 = "/sata@fc400000";
		sata2 = "/sata@fc800000";
		usb_host0_xhci = "/usb@fcc00000";
		usb_host1_xhci = "/usb@fd000000";
		gic = "/interrupt-controller@fd400000";
		its = "/interrupt-controller@fd400000/interrupt-controller@fd440000";
		usb_host0_ehci = "/usb@fd800000";
		usb_host0_ohci = "/usb@fd840000";
		usb_host1_ehci = "/usb@fd880000";
		usb_host1_ohci = "/usb@fd8c0000";
		xpcs = "/syscon@fda00000";
		pmugrf = "/syscon@fdc20000";
		pmu_io_domains = "/syscon@fdc20000/io-domains";
		pipegrf = "/syscon@fdc50000";
		grf = "/syscon@fdc60000";
		pipe_phy_grf1 = "/syscon@fdc80000";
		pipe_phy_grf2 = "/syscon@fdc90000";
		usb2phy0_grf = "/syscon@fdca0000";
		usb2phy1_grf = "/syscon@fdca8000";
		pmucru = "/clock-controller@fdd00000";
		cru = "/clock-controller@fdd20000";
		i2c0 = "/i2c@fdd40000";
		vdd_cpu = "/i2c@fdd40000/regulator@1c";
		rk809 = "/i2c@fdd40000/pmic@20";
		vdd_logic = "/i2c@fdd40000/pmic@20/regulators/DCDC_REG1";
		vdd_gpu = "/i2c@fdd40000/pmic@20/regulators/DCDC_REG2";
		vcc_ddr = "/i2c@fdd40000/pmic@20/regulators/DCDC_REG3";
		vdd_npu = "/i2c@fdd40000/pmic@20/regulators/DCDC_REG4";
		vcc_1v8 = "/i2c@fdd40000/pmic@20/regulators/DCDC_REG5";
		vdda0v9_image = "/i2c@fdd40000/pmic@20/regulators/LDO_REG1";
		vdda_0v9 = "/i2c@fdd40000/pmic@20/regulators/LDO_REG2";
		vdda0v9_pmu = "/i2c@fdd40000/pmic@20/regulators/LDO_REG3";
		vccio_acodec = "/i2c@fdd40000/pmic@20/regulators/LDO_REG4";
		vccio_sd = "/i2c@fdd40000/pmic@20/regulators/LDO_REG5";
		vcc3v3_pmu = "/i2c@fdd40000/pmic@20/regulators/LDO_REG6";
		vcca_1v8 = "/i2c@fdd40000/pmic@20/regulators/LDO_REG7";
		vcca1v8_pmu = "/i2c@fdd40000/pmic@20/regulators/LDO_REG8";
		vcca1v8_image = "/i2c@fdd40000/pmic@20/regulators/LDO_REG9";
		vcc_3v3 = "/i2c@fdd40000/pmic@20/regulators/SWITCH_REG1";
		vcc3v3_sd = "/i2c@fdd40000/pmic@20/regulators/SWITCH_REG2";
		uart0 = "/serial@fdd50000";
		pwm0 = "/pwm@fdd70000";
		pwm1 = "/pwm@fdd70010";
		pwm2 = "/pwm@fdd70020";
		pwm3 = "/pwm@fdd70030";
		pmu = "/power-management@fdd90000";
		power = "/power-management@fdd90000/power-controller";
		gpu = "/gpu@fde60000";
		vpu = "/video-codec@fdea0400";
		vdpu_mmu = "/iommu@fdea0800";
		rga = "/rga@fdeb0000";
		vepu = "/video-codec@fdee0000";
		vepu_mmu = "/iommu@fdee0800";
		sdmmc2 = "/mmc@fe000000";
		gmac1 = "/ethernet@fe010000";
		mdio1 = "/ethernet@fe010000/mdio";
		rgmii_phy1 = "/ethernet@fe010000/mdio/ethernet-phy@0";
		gmac1_stmmac_axi_setup = "/ethernet@fe010000/stmmac-axi-config";
		gmac1_mtl_rx_setup = "/ethernet@fe010000/rx-queues-config";
		gmac1_mtl_tx_setup = "/ethernet@fe010000/tx-queues-config";
		vop = "/vop@fe040000";
		vop_out = "/vop@fe040000/ports";
		vp0 = "/vop@fe040000/ports/port@0";
		vp1 = "/vop@fe040000/ports/port@1";
		vp2 = "/vop@fe040000/ports/port@2";
		vop_mmu = "/iommu@fe043e00";
		dsi0 = "/dsi@fe060000";
		dsi0_in = "/dsi@fe060000/ports/port@0";
		dsi0_out = "/dsi@fe060000/ports/port@1";
		dsi1 = "/dsi@fe070000";
		dsi1_in = "/dsi@fe070000/ports/port@0";
		dsi1_out = "/dsi@fe070000/ports/port@1";
		hdmi = "/hdmi@fe0a0000";
		hdmi_in = "/hdmi@fe0a0000/ports/port@0";
		hdmi_out = "/hdmi@fe0a0000/ports/port@1";
		qos_gpu = "/qos@fe128000";
		qos_rkvenc_rd_m0 = "/qos@fe138080";
		qos_rkvenc_rd_m1 = "/qos@fe138100";
		qos_rkvenc_wr_m0 = "/qos@fe138180";
		qos_isp = "/qos@fe148000";
		qos_vicap0 = "/qos@fe148080";
		qos_vicap1 = "/qos@fe148100";
		qos_vpu = "/qos@fe150000";
		qos_ebc = "/qos@fe158000";
		qos_iep = "/qos@fe158100";
		qos_jpeg_dec = "/qos@fe158180";
		qos_jpeg_enc = "/qos@fe158200";
		qos_rga_rd = "/qos@fe158280";
		qos_rga_wr = "/qos@fe158300";
		qos_npu = "/qos@fe180000";
		qos_pcie2x1 = "/qos@fe190000";
		qos_sata1 = "/qos@fe190280";
		qos_sata2 = "/qos@fe190300";
		qos_usb3_0 = "/qos@fe190380";
		qos_usb3_1 = "/qos@fe190400";
		qos_rkvdec = "/qos@fe198000";
		qos_hdcp = "/qos@fe1a8000";
		qos_vop_m0 = "/qos@fe1a8080";
		qos_vop_m1 = "/qos@fe1a8100";
		pcie2x1 = "/pcie@fe260000";
		pcie_intc = "/pcie@fe260000/legacy-interrupt-controller";
		sdmmc0 = "/mmc@fe2b0000";
		sdmmc1 = "/mmc@fe2c0000";
		sfc = "/spi@fe300000";
		sdhci = "/mmc@fe310000";
		spdif = "/spdif@fe460000";
		i2s0_8ch = "/i2s@fe400000";
		i2s1_8ch = "/i2s@fe410000";
		i2s3_2ch = "/i2s@fe430000";
		pdm = "/pdm@fe440000";
		dmac0 = "/dma-controller@fe530000";
		dmac1 = "/dma-controller@fe550000";
		i2c1 = "/i2c@fe5a0000";
		i2c2 = "/i2c@fe5b0000";
		i2c3 = "/i2c@fe5c0000";
		i2c4 = "/i2c@fe5d0000";
		i2c5 = "/i2c@fe5e0000";
		wdt = "/watchdog@fe600000";
		spi0 = "/spi@fe610000";
		spi1 = "/spi@fe620000";
		spi2 = "/spi@fe630000";
		spi3 = "/spi@fe640000";
		uart1 = "/serial@fe650000";
		uart2 = "/serial@fe660000";
		uart3 = "/serial@fe670000";
		uart4 = "/serial@fe680000";
		uart5 = "/serial@fe690000";
		uart6 = "/serial@fe6a0000";
		uart7 = "/serial@fe6b0000";
		uart8 = "/serial@fe6c0000";
		uart9 = "/serial@fe6d0000";
		thermal_zones = "/thermal-zones";
		cpu_thermal = "/thermal-zones/cpu-thermal";
		cpu_alert0 = "/thermal-zones/cpu-thermal/trips/cpu_alert0";
		cpu_alert1 = "/thermal-zones/cpu-thermal/trips/cpu_alert1";
		cpu_crit = "/thermal-zones/cpu-thermal/trips/cpu_crit";
		gpu_thermal = "/thermal-zones/gpu-thermal";
		gpu_threshold = "/thermal-zones/gpu-thermal/trips/gpu-threshold";
		gpu_target = "/thermal-zones/gpu-thermal/trips/gpu-target";
		gpu_crit = "/thermal-zones/gpu-thermal/trips/gpu-crit";
		tsadc = "/tsadc@fe710000";
		saradc = "/saradc@fe720000";
		pwm4 = "/pwm@fe6e0000";
		pwm5 = "/pwm@fe6e0010";
		pwm6 = "/pwm@fe6e0020";
		pwm7 = "/pwm@fe6e0030";
		pwm8 = "/pwm@fe6f0000";
		pwm9 = "/pwm@fe6f0010";
		pwm10 = "/pwm@fe6f0020";
		pwm11 = "/pwm@fe6f0030";
		pwm12 = "/pwm@fe700000";
		pwm13 = "/pwm@fe700010";
		pwm14 = "/pwm@fe700020";
		pwm15 = "/pwm@fe700030";
		combphy1 = "/phy@fe830000";
		combphy2 = "/phy@fe840000";
		csi_dphy = "/phy@fe870000";
		dsi_dphy0 = "/mipi-dphy@fe850000";
		dsi_dphy1 = "/mipi-dphy@fe860000";
		usb2phy0 = "/usb2phy@fe8a0000";
		usb2phy0_host = "/usb2phy@fe8a0000/host-port";
		usb2phy0_otg = "/usb2phy@fe8a0000/otg-port";
		usb2phy1 = "/usb2phy@fe8b0000";
		usb2phy1_host = "/usb2phy@fe8b0000/host-port";
		usb2phy1_otg = "/usb2phy@fe8b0000/otg-port";
		rng = "/rng@fe388000";
		pinctrl = "/pinctrl";
		gpio0 = "/pinctrl/gpio@fdd60000";
		gpio1 = "/pinctrl/gpio@fe740000";
		gpio2 = "/pinctrl/gpio@fe750000";
		gpio3 = "/pinctrl/gpio@fe760000";
		gpio4 = "/pinctrl/gpio@fe770000";
		pcfg_pull_up = "/pinctrl/pcfg-pull-up";
		pcfg_pull_down = "/pinctrl/pcfg-pull-down";
		pcfg_pull_none = "/pinctrl/pcfg-pull-none";
		pcfg_pull_none_drv_level_0 = "/pinctrl/pcfg-pull-none-drv-level-0";
		pcfg_pull_none_drv_level_1 = "/pinctrl/pcfg-pull-none-drv-level-1";
		pcfg_pull_none_drv_level_2 = "/pinctrl/pcfg-pull-none-drv-level-2";
		pcfg_pull_none_drv_level_3 = "/pinctrl/pcfg-pull-none-drv-level-3";
		pcfg_pull_none_drv_level_4 = "/pinctrl/pcfg-pull-none-drv-level-4";
		pcfg_pull_none_drv_level_5 = "/pinctrl/pcfg-pull-none-drv-level-5";
		pcfg_pull_none_drv_level_6 = "/pinctrl/pcfg-pull-none-drv-level-6";
		pcfg_pull_none_drv_level_7 = "/pinctrl/pcfg-pull-none-drv-level-7";
		pcfg_pull_none_drv_level_8 = "/pinctrl/pcfg-pull-none-drv-level-8";
		pcfg_pull_none_drv_level_9 = "/pinctrl/pcfg-pull-none-drv-level-9";
		pcfg_pull_none_drv_level_10 = "/pinctrl/pcfg-pull-none-drv-level-10";
		pcfg_pull_none_drv_level_11 = "/pinctrl/pcfg-pull-none-drv-level-11";
		pcfg_pull_none_drv_level_12 = "/pinctrl/pcfg-pull-none-drv-level-12";
		pcfg_pull_none_drv_level_13 = "/pinctrl/pcfg-pull-none-drv-level-13";
		pcfg_pull_none_drv_level_14 = "/pinctrl/pcfg-pull-none-drv-level-14";
		pcfg_pull_none_drv_level_15 = "/pinctrl/pcfg-pull-none-drv-level-15";
		pcfg_pull_up_drv_level_0 = "/pinctrl/pcfg-pull-up-drv-level-0";
		pcfg_pull_up_drv_level_1 = "/pinctrl/pcfg-pull-up-drv-level-1";
		pcfg_pull_up_drv_level_2 = "/pinctrl/pcfg-pull-up-drv-level-2";
		pcfg_pull_up_drv_level_3 = "/pinctrl/pcfg-pull-up-drv-level-3";
		pcfg_pull_up_drv_level_4 = "/pinctrl/pcfg-pull-up-drv-level-4";
		pcfg_pull_up_drv_level_5 = "/pinctrl/pcfg-pull-up-drv-level-5";
		pcfg_pull_up_drv_level_6 = "/pinctrl/pcfg-pull-up-drv-level-6";
		pcfg_pull_up_drv_level_7 = "/pinctrl/pcfg-pull-up-drv-level-7";
		pcfg_pull_up_drv_level_8 = "/pinctrl/pcfg-pull-up-drv-level-8";
		pcfg_pull_up_drv_level_9 = "/pinctrl/pcfg-pull-up-drv-level-9";
		pcfg_pull_up_drv_level_10 = "/pinctrl/pcfg-pull-up-drv-level-10";
		pcfg_pull_up_drv_level_11 = "/pinctrl/pcfg-pull-up-drv-level-11";
		pcfg_pull_up_drv_level_12 = "/pinctrl/pcfg-pull-up-drv-level-12";
		pcfg_pull_up_drv_level_13 = "/pinctrl/pcfg-pull-up-drv-level-13";
		pcfg_pull_up_drv_level_14 = "/pinctrl/pcfg-pull-up-drv-level-14";
		pcfg_pull_up_drv_level_15 = "/pinctrl/pcfg-pull-up-drv-level-15";
		pcfg_pull_down_drv_level_0 = "/pinctrl/pcfg-pull-down-drv-level-0";
		pcfg_pull_down_drv_level_1 = "/pinctrl/pcfg-pull-down-drv-level-1";
		pcfg_pull_down_drv_level_2 = "/pinctrl/pcfg-pull-down-drv-level-2";
		pcfg_pull_down_drv_level_3 = "/pinctrl/pcfg-pull-down-drv-level-3";
		pcfg_pull_down_drv_level_4 = "/pinctrl/pcfg-pull-down-drv-level-4";
		pcfg_pull_down_drv_level_5 = "/pinctrl/pcfg-pull-down-drv-level-5";
		pcfg_pull_down_drv_level_6 = "/pinctrl/pcfg-pull-down-drv-level-6";
		pcfg_pull_down_drv_level_7 = "/pinctrl/pcfg-pull-down-drv-level-7";
		pcfg_pull_down_drv_level_8 = "/pinctrl/pcfg-pull-down-drv-level-8";
		pcfg_pull_down_drv_level_9 = "/pinctrl/pcfg-pull-down-drv-level-9";
		pcfg_pull_down_drv_level_10 = "/pinctrl/pcfg-pull-down-drv-level-10";
		pcfg_pull_down_drv_level_11 = "/pinctrl/pcfg-pull-down-drv-level-11";
		pcfg_pull_down_drv_level_12 = "/pinctrl/pcfg-pull-down-drv-level-12";
		pcfg_pull_down_drv_level_13 = "/pinctrl/pcfg-pull-down-drv-level-13";
		pcfg_pull_down_drv_level_14 = "/pinctrl/pcfg-pull-down-drv-level-14";
		pcfg_pull_down_drv_level_15 = "/pinctrl/pcfg-pull-down-drv-level-15";
		pcfg_pull_up_smt = "/pinctrl/pcfg-pull-up-smt";
		pcfg_pull_down_smt = "/pinctrl/pcfg-pull-down-smt";
		pcfg_pull_none_smt = "/pinctrl/pcfg-pull-none-smt";
		pcfg_pull_none_drv_level_0_smt = "/pinctrl/pcfg-pull-none-drv-level-0-smt";
		pcfg_output_high = "/pinctrl/pcfg-output-high";
		pcfg_output_low = "/pinctrl/pcfg-output-low";
		acodec_pins = "/pinctrl/acodec/acodec-pins";
		audiopwm_lout = "/pinctrl/audiopwm/audiopwm-lout";
		audiopwm_loutn = "/pinctrl/audiopwm/audiopwm-loutn";
		audiopwm_loutp = "/pinctrl/audiopwm/audiopwm-loutp";
		audiopwm_rout = "/pinctrl/audiopwm/audiopwm-rout";
		audiopwm_routn = "/pinctrl/audiopwm/audiopwm-routn";
		audiopwm_routp = "/pinctrl/audiopwm/audiopwm-routp";
		bt656m0_pins = "/pinctrl/bt656/bt656m0-pins";
		bt656m1_pins = "/pinctrl/bt656/bt656m1-pins";
		bt1120_pins = "/pinctrl/bt1120/bt1120-pins";
		cam_clkout0 = "/pinctrl/cam/cam-clkout0";
		cam_clkout1 = "/pinctrl/cam/cam-clkout1";
		can0m0_pins = "/pinctrl/can0/can0m0-pins";
		can0m1_pins = "/pinctrl/can0/can0m1-pins";
		can1m0_pins = "/pinctrl/can1/can1m0-pins";
		can1m1_pins = "/pinctrl/can1/can1m1-pins";
		can2m0_pins = "/pinctrl/can2/can2m0-pins";
		can2m1_pins = "/pinctrl/can2/can2m1-pins";
		cif_clk = "/pinctrl/cif/cif-clk";
		cif_dvp_clk = "/pinctrl/cif/cif-dvp-clk";
		cif_dvp_bus16 = "/pinctrl/cif/cif-dvp-bus16";
		cif_dvp_bus8 = "/pinctrl/cif/cif-dvp-bus8";
		clk32k_in = "/pinctrl/clk32k/clk32k-in";
		clk32k_out0 = "/pinctrl/clk32k/clk32k-out0";
		clk32k_out1 = "/pinctrl/clk32k/clk32k-out1";
		cpu_pins = "/pinctrl/cpu/cpu-pins";
		ebc_extern = "/pinctrl/ebc/ebc-extern";
		ebc_pins = "/pinctrl/ebc/ebc-pins";
		edpdpm0_pins = "/pinctrl/edpdp/edpdpm0-pins";
		edpdpm1_pins = "/pinctrl/edpdp/edpdpm1-pins";
		emmc_rstnout = "/pinctrl/emmc/emmc-rstnout";
		emmc_bus8 = "/pinctrl/emmc/emmc-bus8";
		emmc_clk = "/pinctrl/emmc/emmc-clk";
		emmc_cmd = "/pinctrl/emmc/emmc-cmd";
		emmc_datastrobe = "/pinctrl/emmc/emmc-datastrobe";
		eth0_pins = "/pinctrl/eth0/eth0-pins";
		eth1m0_pins = "/pinctrl/eth1/eth1m0-pins";
		eth1m1_pins = "/pinctrl/eth1/eth1m1-pins";
		flash_pins = "/pinctrl/flash/flash-pins";
		fspi_pins = "/pinctrl/fspi/fspi-pins";
		fspi_cs1 = "/pinctrl/fspi/fspi-cs1";
		gmac0_miim = "/pinctrl/gmac0/gmac0-miim";
		gmac0_clkinout = "/pinctrl/gmac0/gmac0-clkinout";
		gmac0_rx_er = "/pinctrl/gmac0/gmac0-rx-er";
		gmac0_rx_bus2 = "/pinctrl/gmac0/gmac0-rx-bus2";
		gmac0_tx_bus2 = "/pinctrl/gmac0/gmac0-tx-bus2";
		gmac0_rgmii_clk = "/pinctrl/gmac0/gmac0-rgmii-clk";
		gmac0_rgmii_bus = "/pinctrl/gmac0/gmac0-rgmii-bus";
		gmac1m0_miim = "/pinctrl/gmac1/gmac1m0-miim";
		gmac1m0_clkinout = "/pinctrl/gmac1/gmac1m0-clkinout";
		gmac1m0_rx_er = "/pinctrl/gmac1/gmac1m0-rx-er";
		gmac1m0_rx_bus2 = "/pinctrl/gmac1/gmac1m0-rx-bus2";
		gmac1m0_tx_bus2 = "/pinctrl/gmac1/gmac1m0-tx-bus2";
		gmac1m0_rgmii_clk = "/pinctrl/gmac1/gmac1m0-rgmii-clk";
		gmac1m0_rgmii_bus = "/pinctrl/gmac1/gmac1m0-rgmii-bus";
		gmac1m1_miim = "/pinctrl/gmac1/gmac1m1-miim";
		gmac1m1_clkinout = "/pinctrl/gmac1/gmac1m1-clkinout";
		gmac1m1_rx_er = "/pinctrl/gmac1/gmac1m1-rx-er";
		gmac1m1_rx_bus2 = "/pinctrl/gmac1/gmac1m1-rx-bus2";
		gmac1m1_tx_bus2 = "/pinctrl/gmac1/gmac1m1-tx-bus2";
		gmac1m1_rgmii_clk = "/pinctrl/gmac1/gmac1m1-rgmii-clk";
		gmac1m1_rgmii_bus = "/pinctrl/gmac1/gmac1m1-rgmii-bus";
		gpu_pins = "/pinctrl/gpu/gpu-pins";
		hdmitxm0_cec = "/pinctrl/hdmitx/hdmitxm0-cec";
		hdmitxm1_cec = "/pinctrl/hdmitx/hdmitxm1-cec";
		hdmitx_scl = "/pinctrl/hdmitx/hdmitx-scl";
		hdmitx_sda = "/pinctrl/hdmitx/hdmitx-sda";
		i2c0_xfer = "/pinctrl/i2c0/i2c0-xfer";
		i2c1_xfer = "/pinctrl/i2c1/i2c1-xfer";
		i2c2m0_xfer = "/pinctrl/i2c2/i2c2m0-xfer";
		i2c2m1_xfer = "/pinctrl/i2c2/i2c2m1-xfer";
		i2c3m0_xfer = "/pinctrl/i2c3/i2c3m0-xfer";
		i2c3m1_xfer = "/pinctrl/i2c3/i2c3m1-xfer";
		i2c4m0_xfer = "/pinctrl/i2c4/i2c4m0-xfer";
		i2c4m1_xfer = "/pinctrl/i2c4/i2c4m1-xfer";
		i2c5m0_xfer = "/pinctrl/i2c5/i2c5m0-xfer";
		i2c5m1_xfer = "/pinctrl/i2c5/i2c5m1-xfer";
		i2s1m0_lrckrx = "/pinctrl/i2s1/i2s1m0-lrckrx";
		i2s1m0_lrcktx = "/pinctrl/i2s1/i2s1m0-lrcktx";
		i2s1m0_mclk = "/pinctrl/i2s1/i2s1m0-mclk";
		i2s1m0_sclkrx = "/pinctrl/i2s1/i2s1m0-sclkrx";
		i2s1m0_sclktx = "/pinctrl/i2s1/i2s1m0-sclktx";
		i2s1m0_sdi0 = "/pinctrl/i2s1/i2s1m0-sdi0";
		i2s1m0_sdi1 = "/pinctrl/i2s1/i2s1m0-sdi1";
		i2s1m0_sdi2 = "/pinctrl/i2s1/i2s1m0-sdi2";
		i2s1m0_sdi3 = "/pinctrl/i2s1/i2s1m0-sdi3";
		i2s1m0_sdo0 = "/pinctrl/i2s1/i2s1m0-sdo0";
		i2s1m0_sdo1 = "/pinctrl/i2s1/i2s1m0-sdo1";
		i2s1m0_sdo2 = "/pinctrl/i2s1/i2s1m0-sdo2";
		i2s1m0_sdo3 = "/pinctrl/i2s1/i2s1m0-sdo3";
		i2s1m1_lrckrx = "/pinctrl/i2s1/i2s1m1-lrckrx";
		i2s1m1_lrcktx = "/pinctrl/i2s1/i2s1m1-lrcktx";
		i2s1m1_mclk = "/pinctrl/i2s1/i2s1m1-mclk";
		i2s1m1_sclkrx = "/pinctrl/i2s1/i2s1m1-sclkrx";
		i2s1m1_sclktx = "/pinctrl/i2s1/i2s1m1-sclktx";
		i2s1m1_sdi0 = "/pinctrl/i2s1/i2s1m1-sdi0";
		i2s1m1_sdi1 = "/pinctrl/i2s1/i2s1m1-sdi1";
		i2s1m1_sdi2 = "/pinctrl/i2s1/i2s1m1-sdi2";
		i2s1m1_sdi3 = "/pinctrl/i2s1/i2s1m1-sdi3";
		i2s1m1_sdo0 = "/pinctrl/i2s1/i2s1m1-sdo0";
		i2s1m1_sdo1 = "/pinctrl/i2s1/i2s1m1-sdo1";
		i2s1m1_sdo2 = "/pinctrl/i2s1/i2s1m1-sdo2";
		i2s1m1_sdo3 = "/pinctrl/i2s1/i2s1m1-sdo3";
		i2s1m2_lrckrx = "/pinctrl/i2s1/i2s1m2-lrckrx";
		i2s1m2_lrcktx = "/pinctrl/i2s1/i2s1m2-lrcktx";
		i2s1m2_mclk = "/pinctrl/i2s1/i2s1m2-mclk";
		i2s1m2_sclkrx = "/pinctrl/i2s1/i2s1m2-sclkrx";
		i2s1m2_sclktx = "/pinctrl/i2s1/i2s1m2-sclktx";
		i2s1m2_sdi0 = "/pinctrl/i2s1/i2s1m2-sdi0";
		i2s1m2_sdi1 = "/pinctrl/i2s1/i2s1m2-sdi1";
		i2s1m2_sdi2 = "/pinctrl/i2s1/i2s1m2-sdi2";
		i2s1m2_sdi3 = "/pinctrl/i2s1/i2s1m2-sdi3";
		i2s1m2_sdo0 = "/pinctrl/i2s1/i2s1m2-sdo0";
		i2s1m2_sdo1 = "/pinctrl/i2s1/i2s1m2-sdo1";
		i2s1m2_sdo2 = "/pinctrl/i2s1/i2s1m2-sdo2";
		i2s1m2_sdo3 = "/pinctrl/i2s1/i2s1m2-sdo3";
		i2s2m0_lrckrx = "/pinctrl/i2s2/i2s2m0-lrckrx";
		i2s2m0_lrcktx = "/pinctrl/i2s2/i2s2m0-lrcktx";
		i2s2m0_mclk = "/pinctrl/i2s2/i2s2m0-mclk";
		i2s2m0_sclkrx = "/pinctrl/i2s2/i2s2m0-sclkrx";
		i2s2m0_sclktx = "/pinctrl/i2s2/i2s2m0-sclktx";
		i2s2m0_sdi = "/pinctrl/i2s2/i2s2m0-sdi";
		i2s2m0_sdo = "/pinctrl/i2s2/i2s2m0-sdo";
		i2s2m1_lrckrx = "/pinctrl/i2s2/i2s2m1-lrckrx";
		i2s2m1_lrcktx = "/pinctrl/i2s2/i2s2m1-lrcktx";
		i2s2m1_mclk = "/pinctrl/i2s2/i2s2m1-mclk";
		i2s2m1_sclkrx = "/pinctrl/i2s2/i2s2m1-sclkrx";
		i2s2m1_sclktx = "/pinctrl/i2s2/i2s2m1-sclktx";
		i2s2m1_sdi = "/pinctrl/i2s2/i2s2m1-sdi";
		i2s2m1_sdo = "/pinctrl/i2s2/i2s2m1-sdo";
		i2s3m0_lrck = "/pinctrl/i2s3/i2s3m0-lrck";
		i2s3m0_mclk = "/pinctrl/i2s3/i2s3m0-mclk";
		i2s3m0_sclk = "/pinctrl/i2s3/i2s3m0-sclk";
		i2s3m0_sdi = "/pinctrl/i2s3/i2s3m0-sdi";
		i2s3m0_sdo = "/pinctrl/i2s3/i2s3m0-sdo";
		i2s3m1_lrck = "/pinctrl/i2s3/i2s3m1-lrck";
		i2s3m1_mclk = "/pinctrl/i2s3/i2s3m1-mclk";
		i2s3m1_sclk = "/pinctrl/i2s3/i2s3m1-sclk";
		i2s3m1_sdi = "/pinctrl/i2s3/i2s3m1-sdi";
		i2s3m1_sdo = "/pinctrl/i2s3/i2s3m1-sdo";
		isp_pins = "/pinctrl/isp/isp-pins";
		jtag_pins = "/pinctrl/jtag/jtag-pins";
		lcdc_ctl = "/pinctrl/lcdc/lcdc-ctl";
		mcu_pins = "/pinctrl/mcu/mcu-pins";
		npu_pins = "/pinctrl/npu/npu-pins";
		pcie20m0_pins = "/pinctrl/pcie20/pcie20m0-pins";
		pcie20m1_pins = "/pinctrl/pcie20/pcie20m1-pins";
		pcie20m2_pins = "/pinctrl/pcie20/pcie20m2-pins";
		pcie20_buttonrstn = "/pinctrl/pcie20/pcie20-buttonrstn";
		pcie30x1m0_pins = "/pinctrl/pcie30x1/pcie30x1m0-pins";
		pcie30x1m1_pins = "/pinctrl/pcie30x1/pcie30x1m1-pins";
		pcie30x1m2_pins = "/pinctrl/pcie30x1/pcie30x1m2-pins";
		pcie30x1_buttonrstn = "/pinctrl/pcie30x1/pcie30x1-buttonrstn";
		pcie30x2m0_pins = "/pinctrl/pcie30x2/pcie30x2m0-pins";
		pcie30x2m1_pins = "/pinctrl/pcie30x2/pcie30x2m1-pins";
		pcie30x2m2_pins = "/pinctrl/pcie30x2/pcie30x2m2-pins";
		pcie30x2_buttonrstn = "/pinctrl/pcie30x2/pcie30x2-buttonrstn";
		pdmm0_clk = "/pinctrl/pdm/pdmm0-clk";
		pdmm0_clk1 = "/pinctrl/pdm/pdmm0-clk1";
		pdmm0_sdi0 = "/pinctrl/pdm/pdmm0-sdi0";
		pdmm0_sdi1 = "/pinctrl/pdm/pdmm0-sdi1";
		pdmm0_sdi2 = "/pinctrl/pdm/pdmm0-sdi2";
		pdmm0_sdi3 = "/pinctrl/pdm/pdmm0-sdi3";
		pdmm1_clk = "/pinctrl/pdm/pdmm1-clk";
		pdmm1_clk1 = "/pinctrl/pdm/pdmm1-clk1";
		pdmm1_sdi0 = "/pinctrl/pdm/pdmm1-sdi0";
		pdmm1_sdi1 = "/pinctrl/pdm/pdmm1-sdi1";
		pdmm1_sdi2 = "/pinctrl/pdm/pdmm1-sdi2";
		pdmm1_sdi3 = "/pinctrl/pdm/pdmm1-sdi3";
		pdmm2_clk1 = "/pinctrl/pdm/pdmm2-clk1";
		pdmm2_sdi0 = "/pinctrl/pdm/pdmm2-sdi0";
		pdmm2_sdi1 = "/pinctrl/pdm/pdmm2-sdi1";
		pdmm2_sdi2 = "/pinctrl/pdm/pdmm2-sdi2";
		pdmm2_sdi3 = "/pinctrl/pdm/pdmm2-sdi3";
		pmic_pins = "/pinctrl/pmic/pmic-pins";
		pmic_int_l = "/pinctrl/pmic/pmic-int-l";
		pmu_pins = "/pinctrl/pmu/pmu-pins";
		pwm0m0_pins = "/pinctrl/pwm0/pwm0m0-pins";
		pwm0m1_pins = "/pinctrl/pwm0/pwm0m1-pins";
		pwm1m0_pins = "/pinctrl/pwm1/pwm1m0-pins";
		pwm1m1_pins = "/pinctrl/pwm1/pwm1m1-pins";
		pwm2m0_pins = "/pinctrl/pwm2/pwm2m0-pins";
		pwm2m1_pins = "/pinctrl/pwm2/pwm2m1-pins";
		pwm3_pins = "/pinctrl/pwm3/pwm3-pins";
		pwm4_pins = "/pinctrl/pwm4/pwm4-pins";
		pwm5_pins = "/pinctrl/pwm5/pwm5-pins";
		pwm6_pins = "/pinctrl/pwm6/pwm6-pins";
		pwm7_pins = "/pinctrl/pwm7/pwm7-pins";
		pwm8m0_pins = "/pinctrl/pwm8/pwm8m0-pins";
		pwm8m1_pins = "/pinctrl/pwm8/pwm8m1-pins";
		pwm9m0_pins = "/pinctrl/pwm9/pwm9m0-pins";
		pwm9m1_pins = "/pinctrl/pwm9/pwm9m1-pins";
		pwm10m0_pins = "/pinctrl/pwm10/pwm10m0-pins";
		pwm10m1_pins = "/pinctrl/pwm10/pwm10m1-pins";
		pwm11m0_pins = "/pinctrl/pwm11/pwm11m0-pins";
		pwm11m1_pins = "/pinctrl/pwm11/pwm11m1-pins";
		pwm12m0_pins = "/pinctrl/pwm12/pwm12m0-pins";
		pwm12m1_pins = "/pinctrl/pwm12/pwm12m1-pins";
		pwm13m0_pins = "/pinctrl/pwm13/pwm13m0-pins";
		pwm13m1_pins = "/pinctrl/pwm13/pwm13m1-pins";
		pwm14m0_pins = "/pinctrl/pwm14/pwm14m0-pins";
		pwm14m1_pins = "/pinctrl/pwm14/pwm14m1-pins";
		pwm15m0_pins = "/pinctrl/pwm15/pwm15m0-pins";
		pwm15m1_pins = "/pinctrl/pwm15/pwm15m1-pins";
		refclk_pins = "/pinctrl/refclk/refclk-pins";
		sata_pins = "/pinctrl/sata/sata-pins";
		sata0_pins = "/pinctrl/sata0/sata0-pins";
		sata1_pins = "/pinctrl/sata1/sata1-pins";
		sata2_pins = "/pinctrl/sata2/sata2-pins";
		scr_pins = "/pinctrl/scr/scr-pins";
		sdmmc0_bus4 = "/pinctrl/sdmmc0/sdmmc0-bus4";
		sdmmc0_clk = "/pinctrl/sdmmc0/sdmmc0-clk";
		sdmmc0_cmd = "/pinctrl/sdmmc0/sdmmc0-cmd";
		sdmmc0_det = "/pinctrl/sdmmc0/sdmmc0-det";
		sdmmc0_pwren = "/pinctrl/sdmmc0/sdmmc0-pwren";
		sdmmc1_bus4 = "/pinctrl/sdmmc1/sdmmc1-bus4";
		sdmmc1_clk = "/pinctrl/sdmmc1/sdmmc1-clk";
		sdmmc1_cmd = "/pinctrl/sdmmc1/sdmmc1-cmd";
		sdmmc1_det = "/pinctrl/sdmmc1/sdmmc1-det";
		sdmmc1_pwren = "/pinctrl/sdmmc1/sdmmc1-pwren";
		sdmmc2m0_bus4 = "/pinctrl/sdmmc2/sdmmc2m0-bus4";
		sdmmc2m0_clk = "/pinctrl/sdmmc2/sdmmc2m0-clk";
		sdmmc2m0_cmd = "/pinctrl/sdmmc2/sdmmc2m0-cmd";
		sdmmc2m0_det = "/pinctrl/sdmmc2/sdmmc2m0-det";
		sdmmc2m0_pwren = "/pinctrl/sdmmc2/sdmmc2m0-pwren";
		sdmmc2m1_bus4 = "/pinctrl/sdmmc2/sdmmc2m1-bus4";
		sdmmc2m1_clk = "/pinctrl/sdmmc2/sdmmc2m1-clk";
		sdmmc2m1_cmd = "/pinctrl/sdmmc2/sdmmc2m1-cmd";
		sdmmc2m1_det = "/pinctrl/sdmmc2/sdmmc2m1-det";
		sdmmc2m1_pwren = "/pinctrl/sdmmc2/sdmmc2m1-pwren";
		spdifm0_tx = "/pinctrl/spdif/spdifm0-tx";
		spdifm1_tx = "/pinctrl/spdif/spdifm1-tx";
		spdifm2_tx = "/pinctrl/spdif/spdifm2-tx";
		spi0m0_pins = "/pinctrl/spi0/spi0m0-pins";
		spi0m0_cs0 = "/pinctrl/spi0/spi0m0-cs0";
		spi0m0_cs1 = "/pinctrl/spi0/spi0m0-cs1";
		spi0m1_pins = "/pinctrl/spi0/spi0m1-pins";
		spi0m1_cs0 = "/pinctrl/spi0/spi0m1-cs0";
		spi1m0_pins = "/pinctrl/spi1/spi1m0-pins";
		spi1m0_cs0 = "/pinctrl/spi1/spi1m0-cs0";
		spi1m0_cs1 = "/pinctrl/spi1/spi1m0-cs1";
		spi1m1_pins = "/pinctrl/spi1/spi1m1-pins";
		spi1m1_cs0 = "/pinctrl/spi1/spi1m1-cs0";
		spi2m0_pins = "/pinctrl/spi2/spi2m0-pins";
		spi2m0_cs0 = "/pinctrl/spi2/spi2m0-cs0";
		spi2m0_cs1 = "/pinctrl/spi2/spi2m0-cs1";
		spi2m1_pins = "/pinctrl/spi2/spi2m1-pins";
		spi2m1_cs0 = "/pinctrl/spi2/spi2m1-cs0";
		spi2m1_cs1 = "/pinctrl/spi2/spi2m1-cs1";
		spi3m0_pins = "/pinctrl/spi3/spi3m0-pins";
		spi3m0_cs0 = "/pinctrl/spi3/spi3m0-cs0";
		spi3m0_cs1 = "/pinctrl/spi3/spi3m0-cs1";
		spi3m1_pins = "/pinctrl/spi3/spi3m1-pins";
		spi3m1_cs0 = "/pinctrl/spi3/spi3m1-cs0";
		spi3m1_cs1 = "/pinctrl/spi3/spi3m1-cs1";
		tsadcm0_shut = "/pinctrl/tsadc/tsadcm0-shut";
		tsadcm1_shut = "/pinctrl/tsadc/tsadcm1-shut";
		tsadc_shutorg = "/pinctrl/tsadc/tsadc-shutorg";
		tsadc_pin = "/pinctrl/tsadc/tsadc-pin";
		uart0_xfer = "/pinctrl/uart0/uart0-xfer";
		uart0_ctsn = "/pinctrl/uart0/uart0-ctsn";
		uart0_rtsn = "/pinctrl/uart0/uart0-rtsn";
		uart1m0_xfer = "/pinctrl/uart1/uart1m0-xfer";
		uart1m0_ctsn = "/pinctrl/uart1/uart1m0-ctsn";
		uart1m0_rtsn = "/pinctrl/uart1/uart1m0-rtsn";
		uart1m1_xfer = "/pinctrl/uart1/uart1m1-xfer";
		uart1m1_ctsn = "/pinctrl/uart1/uart1m1-ctsn";
		uart1m1_rtsn = "/pinctrl/uart1/uart1m1-rtsn";
		uart2m0_xfer = "/pinctrl/uart2/uart2m0-xfer";
		uart2m1_xfer = "/pinctrl/uart2/uart2m1-xfer";
		uart3m0_xfer = "/pinctrl/uart3/uart3m0-xfer";
		uart3m0_ctsn = "/pinctrl/uart3/uart3m0-ctsn";
		uart3m0_rtsn = "/pinctrl/uart3/uart3m0-rtsn";
		uart3m1_xfer = "/pinctrl/uart3/uart3m1-xfer";
		uart4m0_xfer = "/pinctrl/uart4/uart4m0-xfer";
		uart4m0_ctsn = "/pinctrl/uart4/uart4m0-ctsn";
		uart4m0_rtsn = "/pinctrl/uart4/uart4m0-rtsn";
		uart4m1_xfer = "/pinctrl/uart4/uart4m1-xfer";
		uart5m0_xfer = "/pinctrl/uart5/uart5m0-xfer";
		uart5m0_ctsn = "/pinctrl/uart5/uart5m0-ctsn";
		uart5m0_rtsn = "/pinctrl/uart5/uart5m0-rtsn";
		uart5m1_xfer = "/pinctrl/uart5/uart5m1-xfer";
		uart6m0_xfer = "/pinctrl/uart6/uart6m0-xfer";
		uart6m0_ctsn = "/pinctrl/uart6/uart6m0-ctsn";
		uart6m0_rtsn = "/pinctrl/uart6/uart6m0-rtsn";
		uart6m1_xfer = "/pinctrl/uart6/uart6m1-xfer";
		uart7m0_xfer = "/pinctrl/uart7/uart7m0-xfer";
		uart7m0_ctsn = "/pinctrl/uart7/uart7m0-ctsn";
		uart7m0_rtsn = "/pinctrl/uart7/uart7m0-rtsn";
		uart7m1_xfer = "/pinctrl/uart7/uart7m1-xfer";
		uart7m2_xfer = "/pinctrl/uart7/uart7m2-xfer";
		uart8m0_xfer = "/pinctrl/uart8/uart8m0-xfer";
		uart8m0_ctsn = "/pinctrl/uart8/uart8m0-ctsn";
		uart8m0_rtsn = "/pinctrl/uart8/uart8m0-rtsn";
		uart8m1_xfer = "/pinctrl/uart8/uart8m1-xfer";
		uart9m0_xfer = "/pinctrl/uart9/uart9m0-xfer";
		uart9m0_ctsn = "/pinctrl/uart9/uart9m0-ctsn";
		uart9m0_rtsn = "/pinctrl/uart9/uart9m0-rtsn";
		uart9m1_xfer = "/pinctrl/uart9/uart9m1-xfer";
		uart9m2_xfer = "/pinctrl/uart9/uart9m2-xfer";
		vopm0_pins = "/pinctrl/vop/vopm0-pins";
		vopm1_pins = "/pinctrl/vop/vopm1-pins";
		spi0m0_pins_hs = "/pinctrl/spi0-hs/spi0m0-pins";
		spi0m0_cs0_hs = "/pinctrl/spi0-hs/spi0m0-cs0";
		spi0m0_cs1_hs = "/pinctrl/spi0-hs/spi0m0-cs1";
		spi0m1_pins_hs = "/pinctrl/spi0-hs/spi0m1-pins";
		spi0m1_cs0_hs = "/pinctrl/spi0-hs/spi0m1-cs0";
		spi1m0_pins_hs = "/pinctrl/spi1-hs/spi1m0-pins";
		spi1m0_cs0_hs = "/pinctrl/spi1-hs/spi1m0-cs0";
		spi1m0_cs1_hs = "/pinctrl/spi1-hs/spi1m0-cs1";
		spi1m1_pins_hs = "/pinctrl/spi1-hs/spi1m1-pins";
		spi1m1_cs0_hs = "/pinctrl/spi1-hs/spi1m1-cs0";
		spi2m0_pins_hs = "/pinctrl/spi2-hs/spi2m0-pins";
		spi2m0_cs0_hs = "/pinctrl/spi2-hs/spi2m0-cs0";
		spi2m0_cs1_hs = "/pinctrl/spi2-hs/spi2m0-cs1";
		spi2m1_pins_hs = "/pinctrl/spi2-hs/spi2m1-pins";
		spi2m1_cs0_hs = "/pinctrl/spi2-hs/spi2m1-cs0";
		spi2m1_cs1_hs = "/pinctrl/spi2-hs/spi2m1-cs1";
		spi3m0_pins_hs = "/pinctrl/spi3-hs/spi3m0-pins";
		spi3m0_cs0_hs = "/pinctrl/spi3-hs/spi3m0-cs0";
		spi3m0_cs1_hs = "/pinctrl/spi3-hs/spi3m0-cs1";
		spi3m1_pins_hs = "/pinctrl/spi3-hs/spi3m1-pins";
		spi3m1_cs0_hs = "/pinctrl/spi3-hs/spi3m1-cs0";
		spi3m1_cs1_hs = "/pinctrl/spi3-hs/spi3m1-cs1";
		gmac0_tx_bus2_level3 = "/pinctrl/gmac-txd-level3/gmac0-tx-bus2-level3";
		gmac0_rgmii_bus_level3 = "/pinctrl/gmac-txd-level3/gmac0-rgmii-bus-level3";
		gmac1m0_tx_bus2_level3 = "/pinctrl/gmac-txd-level3/gmac1m0-tx-bus2-level3";
		gmac1m0_rgmii_bus_level3 = "/pinctrl/gmac-txd-level3/gmac1m0-rgmii-bus-level3";
		gmac1m1_tx_bus2_level3 = "/pinctrl/gmac-txd-level3/gmac1m1-tx-bus2-level3";
		gmac1m1_rgmii_bus_level3 = "/pinctrl/gmac-txd-level3/gmac1m1-rgmii-bus-level3";
		gmac0_rgmii_clk_level2 = "/pinctrl/gmac-txc-level2/gmac0-rgmii-clk-level2";
		gmac1m0_rgmii_clk_level2 = "/pinctrl/gmac-txc-level2/gmac1m0-rgmii-clk-level2";
		gmac1m1_rgmii_clk_level2 = "/pinctrl/gmac-txc-level2/gmac1m1-rgmii-clk-level2";
		wifi_enable_h = "/pinctrl/sdio-pwrseq/wifi-enable-h";
		wifi_host_wake_irq = "/pinctrl/wireless-wlan/wifi-host-wake-irq";
		bt_enable_h = "/pinctrl/bt/bt-enable-h";
		bt_host_wake_l = "/pinctrl/bt/bt-host-wake-l";
		bt_wake_l = "/pinctrl/bt/bt-wake-l";
		led_pwr_enable_h = "/pinctrl/leds/led-pwr-enable-h";
		led_wifi_enable_h = "/pinctrl/leds/led-wifi-enable-h";
		led_eth_enable_h = "/pinctrl/leds/led-eth-enable-h";
		led_status_enable_h = "/pinctrl/leds/led-status-enable-h";
		chosen = "/chosen";
		gmac1_clkin = "/external-gmac1-clock";
		led_pwr = "/leds/led-pwr";
		led_wifi = "/leds/led-wifi";
		led_eth = "/leds/led-eth";
		led_status = "/leds/led-status";
		vbus = "/vbus-regulator";
		vcc5v0_sys = "/vcc5v0-sys-regulator";
		vcc3v3_sys = "/vcc3v3-sys-regulator";
		sdio_pwrseq = "/sdio-pwrseq";
	};
};
